[part 14 of 15: package /ComponentTypes]
AUTOSAR XML (schema 4-3-0)
package /ComponentTypes  (continued)
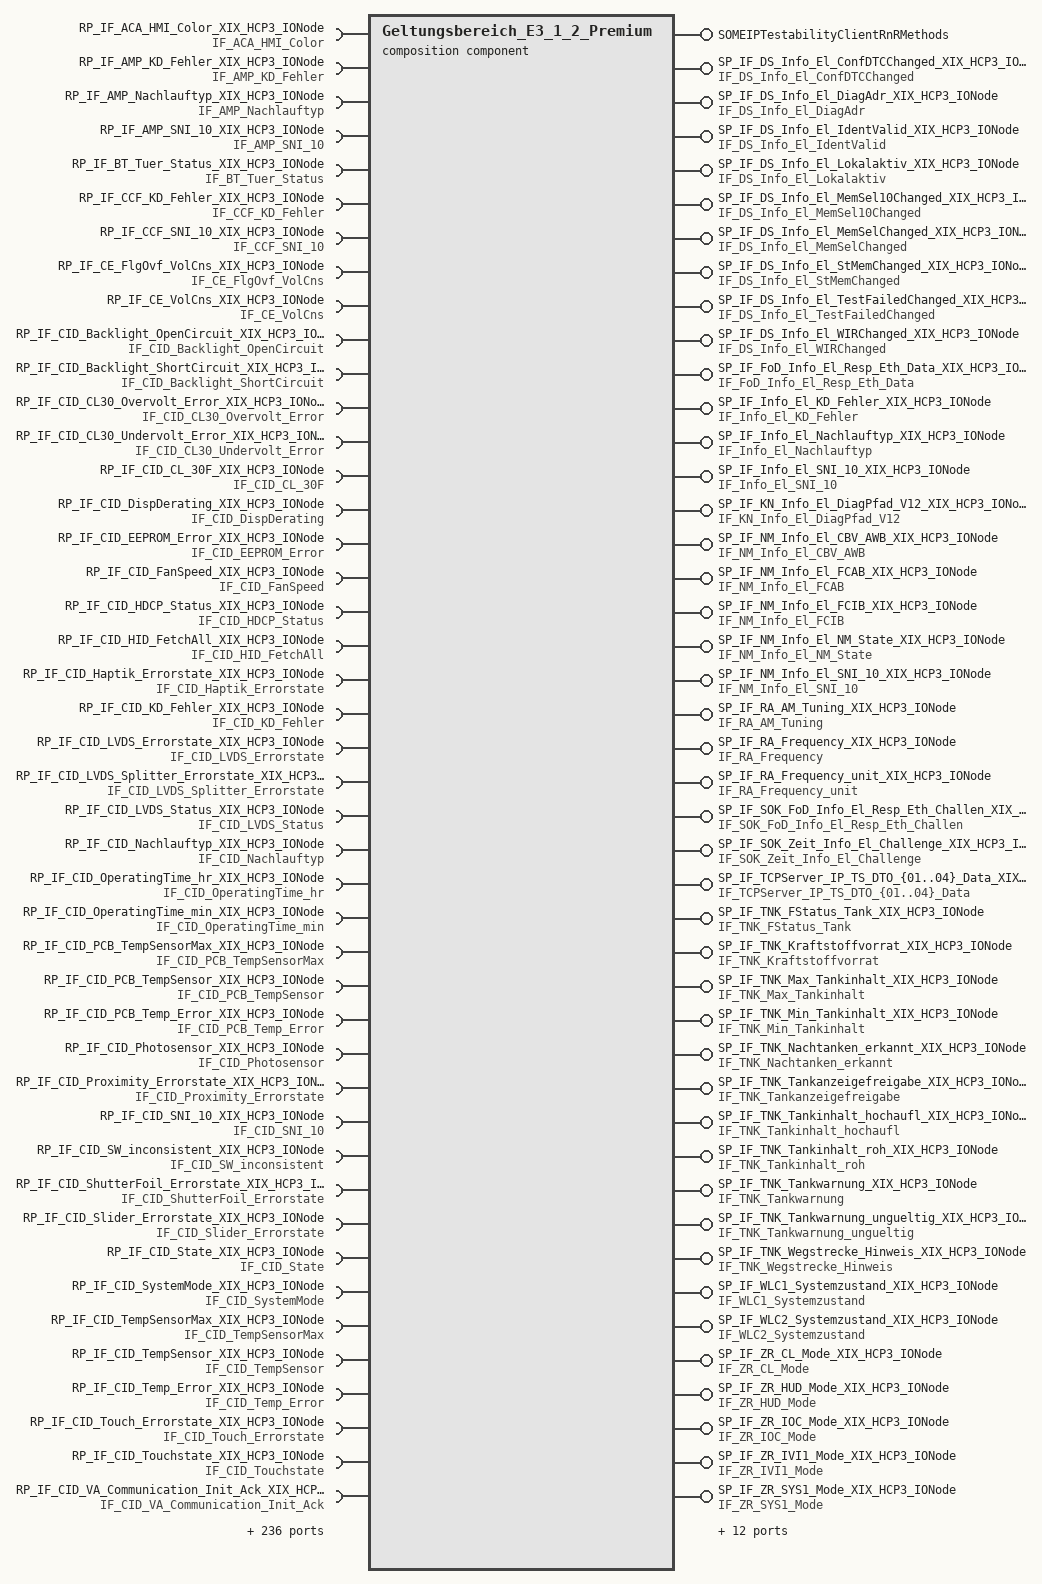
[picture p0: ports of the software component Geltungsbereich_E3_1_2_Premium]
  composition sw component type Geltungsbereich_E3_1_2_Premium
    59 x provide port:
      SOMEIPTestabilityClientRnRMethods: provided-interface=SOMEIPTestabilityClientRnRMethods
      SP_IF_DS_Info_El_ConfDTCChanged_XIX_HCP3_IONode: provided-interface=IF_DS_Info_El_ConfDTCChanged
      SP_IF_DS_Info_El_DiagAdr_XIX_HCP3_IONode: provided-interface=IF_DS_Info_El_DiagAdr
      SP_IF_DS_Info_El_IdentValid_XIX_HCP3_IONode: provided-interface=IF_DS_Info_El_IdentValid
      SP_IF_DS_Info_El_Lokalaktiv_XIX_HCP3_IONode: provided-interface=IF_DS_Info_El_Lokalaktiv
      SP_IF_DS_Info_El_MemSel10Changed_XIX_HCP3_IONode: provided-interface=IF_DS_Info_El_MemSel10Changed
      SP_IF_DS_Info_El_MemSelChanged_XIX_HCP3_IONode: provided-interface=IF_DS_Info_El_MemSelChanged
      SP_IF_DS_Info_El_StMemChanged_XIX_HCP3_IONode: provided-interface=IF_DS_Info_El_StMemChanged
      SP_IF_DS_Info_El_TestFailedChanged_XIX_HCP3_IONode: provided-interface=IF_DS_Info_El_TestFailedChanged
      SP_IF_DS_Info_El_WIRChanged_XIX_HCP3_IONode: provided-interface=IF_DS_Info_El_WIRChanged
      SP_IF_FoD_Info_El_Resp_Eth_Data_XIX_HCP3_IONode: provided-interface=IF_FoD_Info_El_Resp_Eth_Data
      SP_IF_Info_El_KD_Fehler_XIX_HCP3_IONode: provided-interface=IF_Info_El_KD_Fehler
      SP_IF_Info_El_Nachlauftyp_XIX_HCP3_IONode: provided-interface=IF_Info_El_Nachlauftyp
      SP_IF_Info_El_SNI_10_XIX_HCP3_IONode: provided-interface=IF_Info_El_SNI_10
      SP_IF_KN_Info_El_DiagPfad_V12_XIX_HCP3_IONode: provided-interface=IF_KN_Info_El_DiagPfad_V12
      SP_IF_NM_Info_El_CBV_AWB_XIX_HCP3_IONode: provided-interface=IF_NM_Info_El_CBV_AWB
      SP_IF_NM_Info_El_FCAB_XIX_HCP3_IONode: provided-interface=IF_NM_Info_El_FCAB
      SP_IF_NM_Info_El_FCIB_XIX_HCP3_IONode: provided-interface=IF_NM_Info_El_FCIB
      SP_IF_NM_Info_El_NM_State_XIX_HCP3_IONode: provided-interface=IF_NM_Info_El_NM_State
      SP_IF_NM_Info_El_SNI_10_XIX_HCP3_IONode: provided-interface=IF_NM_Info_El_SNI_10
      SP_IF_RA_AM_Tuning_XIX_HCP3_IONode: provided-interface=IF_RA_AM_Tuning
      SP_IF_RA_Frequency_XIX_HCP3_IONode: provided-interface=IF_RA_Frequency
      SP_IF_RA_Frequency_unit_XIX_HCP3_IONode: provided-interface=IF_RA_Frequency_unit
      SP_IF_SOK_FoD_Info_El_Resp_Eth_Challen_XIX_HCP3_IONode: provided-interface=IF_SOK_FoD_Info_El_Resp_Eth_Challen
      SP_IF_SOK_Zeit_Info_El_Challenge_XIX_HCP3_IONode: provided-interface=IF_SOK_Zeit_Info_El_Challenge
      SP_IF_TCPServer_IP_TS_DTO_{01..04}_Data_XIX_HCP3_IONode: provided-interface=IF_TCPServer_IP_TS_DTO_{01..04}_Data
      SP_IF_TNK_FStatus_Tank_XIX_HCP3_IONode: provided-interface=IF_TNK_FStatus_Tank
      SP_IF_TNK_Kraftstoffvorrat_XIX_HCP3_IONode: provided-interface=IF_TNK_Kraftstoffvorrat
      SP_IF_TNK_Max_Tankinhalt_XIX_HCP3_IONode: provided-interface=IF_TNK_Max_Tankinhalt
      SP_IF_TNK_Min_Tankinhalt_XIX_HCP3_IONode: provided-interface=IF_TNK_Min_Tankinhalt
      SP_IF_TNK_Nachtanken_erkannt_XIX_HCP3_IONode: provided-interface=IF_TNK_Nachtanken_erkannt
      SP_IF_TNK_Tankanzeigefreigabe_XIX_HCP3_IONode: provided-interface=IF_TNK_Tankanzeigefreigabe
      SP_IF_TNK_Tankinhalt_hochaufl_XIX_HCP3_IONode: provided-interface=IF_TNK_Tankinhalt_hochaufl
      SP_IF_TNK_Tankinhalt_roh_XIX_HCP3_IONode: provided-interface=IF_TNK_Tankinhalt_roh
      SP_IF_TNK_Tankwarnung_XIX_HCP3_IONode: provided-interface=IF_TNK_Tankwarnung
      SP_IF_TNK_Tankwarnung_ungueltig_XIX_HCP3_IONode: provided-interface=IF_TNK_Tankwarnung_ungueltig
      SP_IF_TNK_Wegstrecke_Hinweis_XIX_HCP3_IONode: provided-interface=IF_TNK_Wegstrecke_Hinweis
      SP_IF_WLC1_Systemzustand_XIX_HCP3_IONode: provided-interface=IF_WLC1_Systemzustand
      SP_IF_WLC2_Systemzustand_XIX_HCP3_IONode: provided-interface=IF_WLC2_Systemzustand
      SP_IF_ZR_CL_Mode_XIX_HCP3_IONode: provided-interface=IF_ZR_CL_Mode
      SP_IF_ZR_HUD_Mode_XIX_HCP3_IONode: provided-interface=IF_ZR_HUD_Mode
      SP_IF_ZR_IOC_Mode_XIX_HCP3_IONode: provided-interface=IF_ZR_IOC_Mode
      SP_IF_ZR_IVI1_Mode_XIX_HCP3_IONode: provided-interface=IF_ZR_IVI1_Mode
      SP_IF_ZR_SYS1_Mode_XIX_HCP3_IONode: provided-interface=IF_ZR_SYS1_Mode
      SP_IF_ZR_State_CID_XIX_HCP3_IONode: provided-interface=IF_ZR_State_CID
      SP_IF_ZR_State_FID_XIX_HCP3_IONode: provided-interface=IF_ZR_State_FID
      SP_IF_ZR_State_PID_XIX_HCP3_IONode: provided-interface=IF_ZR_State_PID
      SP_IF_ZR_VA_Challenge_CID_XIX_HCP3_IONode: provided-interface=IF_ZR_VA_Challenge_CID
      SP_IF_ZR_VA_Challenge_FID_XIX_HCP3_IONode: provided-interface=IF_ZR_VA_Challenge_FID
      SP_IF_ZR_VA_Challenge_PID_XIX_HCP3_IONode: provided-interface=IF_ZR_VA_Challenge_PID
      SP_IF_ZR_VA_Communication_Init_Ack_CID_XIX_HCP3_IONode: provided-interface=IF_ZR_VA_Communication_Init_Ack_CID
      SP_IF_ZR_VA_Communication_Init_Ack_FID_XIX_HCP3_IONode: provided-interface=IF_ZR_VA_Communication_Init_Ack_FID
      SP_IF_ZR_VA_Communication_Init_Ack_PID_XIX_HCP3_IONode: provided-interface=IF_ZR_VA_Communication_Init_Ack_PID
      SP_IF_ZR_VA_Communication_Init_CID_XIX_HCP3_IONode: provided-interface=IF_ZR_VA_Communication_Init_CID
      SP_IF_ZR_VA_Communication_Init_FID_XIX_HCP3_IONode: provided-interface=IF_ZR_VA_Communication_Init_FID
      SP_IF_ZR_VA_Communication_Init_PID_XIX_HCP3_IONode: provided-interface=IF_ZR_VA_Communication_Init_PID
    286 x require port:
      RP_IF_ACA_HMI_Color_XIX_HCP3_IONode: required-interface=IF_ACA_HMI_Color
      RP_IF_AMP_KD_Fehler_XIX_HCP3_IONode: required-interface=IF_AMP_KD_Fehler
      RP_IF_AMP_Nachlauftyp_XIX_HCP3_IONode: required-interface=IF_AMP_Nachlauftyp
      RP_IF_AMP_SNI_10_XIX_HCP3_IONode: required-interface=IF_AMP_SNI_10
      RP_IF_BT_Tuer_Status_XIX_HCP3_IONode: required-interface=IF_BT_Tuer_Status
      RP_IF_CCF_KD_Fehler_XIX_HCP3_IONode: required-interface=IF_CCF_KD_Fehler
      RP_IF_CCF_SNI_10_XIX_HCP3_IONode: required-interface=IF_CCF_SNI_10
      RP_IF_CE_FlgOvf_VolCns_XIX_HCP3_IONode: required-interface=IF_CE_FlgOvf_VolCns
      RP_IF_CE_VolCns_XIX_HCP3_IONode: required-interface=IF_CE_VolCns
      RP_IF_CID_Backlight_OpenCircuit_XIX_HCP3_IONode: required-interface=IF_CID_Backlight_OpenCircuit
      RP_IF_CID_Backlight_ShortCircuit_XIX_HCP3_IONode: required-interface=IF_CID_Backlight_ShortCircuit
      RP_IF_CID_CL30_Overvolt_Error_XIX_HCP3_IONode: required-interface=IF_CID_CL30_Overvolt_Error
      RP_IF_CID_CL30_Undervolt_Error_XIX_HCP3_IONode: required-interface=IF_CID_CL30_Undervolt_Error
      RP_IF_CID_CL_30F_XIX_HCP3_IONode: required-interface=IF_CID_CL_30F
      RP_IF_CID_DispDerating_XIX_HCP3_IONode: required-interface=IF_CID_DispDerating
      RP_IF_CID_EEPROM_Error_XIX_HCP3_IONode: required-interface=IF_CID_EEPROM_Error
      RP_IF_CID_FanSpeed_XIX_HCP3_IONode: required-interface=IF_CID_FanSpeed
      RP_IF_CID_HDCP_Status_XIX_HCP3_IONode: required-interface=IF_CID_HDCP_Status
      RP_IF_CID_HID_FetchAll_XIX_HCP3_IONode: required-interface=IF_CID_HID_FetchAll
      RP_IF_CID_Haptik_Errorstate_XIX_HCP3_IONode: required-interface=IF_CID_Haptik_Errorstate
      RP_IF_CID_KD_Fehler_XIX_HCP3_IONode: required-interface=IF_CID_KD_Fehler
      RP_IF_CID_LVDS_Errorstate_XIX_HCP3_IONode: required-interface=IF_CID_LVDS_Errorstate
      RP_IF_CID_LVDS_Splitter_Errorstate_XIX_HCP3_IONode: required-interface=IF_CID_LVDS_Splitter_Errorstate
      RP_IF_CID_LVDS_Status_XIX_HCP3_IONode: required-interface=IF_CID_LVDS_Status
      RP_IF_CID_Nachlauftyp_XIX_HCP3_IONode: required-interface=IF_CID_Nachlauftyp
      RP_IF_CID_OperatingTime_hr_XIX_HCP3_IONode: required-interface=IF_CID_OperatingTime_hr
      RP_IF_CID_OperatingTime_min_XIX_HCP3_IONode: required-interface=IF_CID_OperatingTime_min
      RP_IF_CID_PCB_TempSensorMax_XIX_HCP3_IONode: required-interface=IF_CID_PCB_TempSensorMax
      RP_IF_CID_PCB_TempSensor_XIX_HCP3_IONode: required-interface=IF_CID_PCB_TempSensor
      RP_IF_CID_PCB_Temp_Error_XIX_HCP3_IONode: required-interface=IF_CID_PCB_Temp_Error
      RP_IF_CID_Photosensor_XIX_HCP3_IONode: required-interface=IF_CID_Photosensor
      RP_IF_CID_Proximity_Errorstate_XIX_HCP3_IONode: required-interface=IF_CID_Proximity_Errorstate
      RP_IF_CID_SNI_10_XIX_HCP3_IONode: required-interface=IF_CID_SNI_10
      RP_IF_CID_SW_inconsistent_XIX_HCP3_IONode: required-interface=IF_CID_SW_inconsistent
      RP_IF_CID_ShutterFoil_Errorstate_XIX_HCP3_IONode: required-interface=IF_CID_ShutterFoil_Errorstate
      RP_IF_CID_Slider_Errorstate_XIX_HCP3_IONode: required-interface=IF_CID_Slider_Errorstate
      RP_IF_CID_State_XIX_HCP3_IONode: required-interface=IF_CID_State
      RP_IF_CID_SystemMode_XIX_HCP3_IONode: required-interface=IF_CID_SystemMode
      RP_IF_CID_TempSensorMax_XIX_HCP3_IONode: required-interface=IF_CID_TempSensorMax
      RP_IF_CID_TempSensor_XIX_HCP3_IONode: required-interface=IF_CID_TempSensor
      RP_IF_CID_Temp_Error_XIX_HCP3_IONode: required-interface=IF_CID_Temp_Error
      RP_IF_CID_Touch_Errorstate_XIX_HCP3_IONode: required-interface=IF_CID_Touch_Errorstate
      RP_IF_CID_Touchstate_XIX_HCP3_IONode: required-interface=IF_CID_Touchstate
      RP_IF_CID_VA_Communication_Init_Ack_XIX_HCP3_IONode: required-interface=IF_CID_VA_Communication_Init_Ack
      RP_IF_CID_VA_Communication_Init_XIX_HCP3_IONode: required-interface=IF_CID_VA_Communication_Init
      RP_IF_CID_VA_Response_XIX_HCP3_IONode: required-interface=IF_CID_VA_Response
      RP_IF_CID_VW_SL_App_SW_Version_Nr_XIX_HCP3_IONode: required-interface=IF_CID_VW_SL_App_SW_Version_Nr
      RP_IF_CID_VW_SL_HW_Version_Nr_XIX_HCP3_IONode: required-interface=IF_CID_VW_SL_HW_Version_Nr
      RP_IF_CID_VW_SL_Spare_Part_Nr_EndNr_XIX_HCP3_IONode: required-interface=IF_CID_VW_SL_Spare_Part_Nr_EndNr
      RP_IF_CID_VW_SL_Spare_Part_Nr_Index_XIX_HCP3_IONode: required-interface=IF_CID_VW_SL_Spare_Part_Nr_Index
      RP_IF_CID_VW_SL_Spare_Part_Nr_MittelNr_XIX_HCP3_IONode: required-interface=IF_CID_VW_SL_Spare_Part_Nr_MittelNr
      RP_IF_CID_VW_SL_Spare_Part_Nr_TMA_XIX_HCP3_IONode: required-interface=IF_CID_VW_SL_Spare_Part_Nr_TMA
      RP_IF_DTSO_StPTEgySrc_XIX_HCP3_IONode: required-interface=IF_DTSO_StPTEgySrc
      RP_IF_DTSO_StPrpUnitAcvWhl_XIX_HCP3_IONode: required-interface=IF_DTSO_StPrpUnitAcvWhl
      RP_IF_DW_Kilometerstand_XIX_HCP3_IONode: required-interface=IF_DW_Kilometerstand
      RP_IF_DispKBI_FS_KD_Fehler_XIX_HCP3_IONode: required-interface=IF_DispKBI_FS_KD_Fehler
      RP_IF_DispKBI_FS_Nachlauftyp_XIX_HCP3_IONode: required-interface=IF_DispKBI_FS_Nachlauftyp
      RP_IF_DispKBI_FS_SNI_10_XIX_HCP3_IONode: required-interface=IF_DispKBI_FS_SNI_10
      RP_IF_FID_Backlight_OpenCircuit_XIX_HCP3_IONode: required-interface=IF_FID_Backlight_OpenCircuit
      RP_IF_FID_Backlight_ShortCircuit_XIX_HCP3_IONode: required-interface=IF_FID_Backlight_ShortCircuit
      RP_IF_FID_CL30_Overvolt_Error_XIX_HCP3_IONode: required-interface=IF_FID_CL30_Overvolt_Error
      RP_IF_FID_CL30_Undervolt_Error_XIX_HCP3_IONode: required-interface=IF_FID_CL30_Undervolt_Error
      RP_IF_FID_CL_30F_XIX_HCP3_IONode: required-interface=IF_FID_CL_30F
      RP_IF_FID_DispDerating_XIX_HCP3_IONode: required-interface=IF_FID_DispDerating
      RP_IF_FID_EEPROM_Error_XIX_HCP3_IONode: required-interface=IF_FID_EEPROM_Error
      RP_IF_FID_LVDS_Errorstate_XIX_HCP3_IONode: required-interface=IF_FID_LVDS_Errorstate
      RP_IF_FID_LVDS_State_XIX_HCP3_IONode: required-interface=IF_FID_LVDS_State
      RP_IF_FID_OperatingTime_hr_XIX_HCP3_IONode: required-interface=IF_FID_OperatingTime_hr
      RP_IF_FID_OperatingTime_min_XIX_HCP3_IONode: required-interface=IF_FID_OperatingTime_min
      RP_IF_FID_PCB_TempSensorMax_XIX_HCP3_IONode: required-interface=IF_FID_PCB_TempSensorMax
      RP_IF_FID_PCB_TempSensor_XIX_HCP3_IONode: required-interface=IF_FID_PCB_TempSensor
      RP_IF_FID_PCB_Temp_Error_XIX_HCP3_IONode: required-interface=IF_FID_PCB_Temp_Error
      RP_IF_FID_Photosensor_XIX_HCP3_IONode: required-interface=IF_FID_Photosensor
      RP_IF_FID_SW_inconsistent_XIX_HCP3_IONode: required-interface=IF_FID_SW_inconsistent
      RP_IF_FID_State_XIX_HCP3_IONode: required-interface=IF_FID_State
      RP_IF_FID_SystemMode_XIX_HCP3_IONode: required-interface=IF_FID_SystemMode
      RP_IF_FID_TempSensorMax_XIX_HCP3_IONode: required-interface=IF_FID_TempSensorMax
      RP_IF_FID_TempSensor_XIX_HCP3_IONode: required-interface=IF_FID_TempSensor
      RP_IF_FID_Temp_Error_XIX_HCP3_IONode: required-interface=IF_FID_Temp_Error
      RP_IF_FID_VA_Communication_Init_Ack_XIX_HCP3_IONode: required-interface=IF_FID_VA_Communication_Init_Ack
      RP_IF_FID_VA_Communication_Init_XIX_HCP3_IONode: required-interface=IF_FID_VA_Communication_Init
      RP_IF_FID_VA_Response_XIX_HCP3_IONode: required-interface=IF_FID_VA_Response
      RP_IF_FT_Tuer_Status_XIX_HCP3_IONode: required-interface=IF_FT_Tuer_Status
      RP_IF_FT_Tuer_geoeffnet_XIX_HCP3_IONode: required-interface=IF_FT_Tuer_geoeffnet
      RP_IF_FoD_Info_El_Req_Eth_Data_XIX_HCP3_IONode: required-interface=IF_FoD_Info_El_Req_Eth_Data
      RP_IF_Gateway_Nachlauftyp_XIX_HCP3_IONode: required-interface=IF_Gateway_Nachlauftyp
      RP_IF_HBFS_Tuer_Status_XIX_HCP3_IONode: required-interface=IF_HBFS_Tuer_Status
      RP_IF_HCP3Sys03_KD_Fehler_XIX_HCP3_IONode: required-interface=IF_HCP3Sys03_KD_Fehler
      RP_IF_HCP3Sys03_SNI_10_XIX_HCP3_IONode: required-interface=IF_HCP3Sys03_SNI_10
      RP_IF_HFS_Tuer_Status_XIX_HCP3_IONode: required-interface=IF_HFS_Tuer_Status
      RP_IF_HUD_KD_Fehler_XIX_HCP3_IONode: required-interface=IF_HUD_KD_Fehler
      RP_IF_HUD_Nachlauftyp_XIX_HCP3_IONode: required-interface=IF_HUD_Nachlauftyp
      RP_IF_HUD_SNI_10_XIX_HCP3_IONode: required-interface=IF_HUD_SNI_10
      RP_IF_SG_HWP_01_XIX_HCP3_IONode: required-interface=IF_SG_HWP_01
      RP_IF_HWP_HMI_State_XIX_HCP3_IONode: required-interface=IF_HWP_HMI_State
      RP_IF_ICAS3Sys01_KD_Fehler_XIX_HCP3_IONode: required-interface=IF_ICAS3Sys01_KD_Fehler
      RP_IF_ICAS3Sys01_SNI_10_XIX_HCP3_IONode: required-interface=IF_ICAS3Sys01_SNI_10
      RP_IF_IP_TS_CTO_01_Data_XIX_HCP3_IONode: required-interface=IF_IP_TS_CTO_01_Data
      RP_IF_IP_TS_DTO_{01..04}_Data_XIX_HCP3_IONode: required-interface=IF_IP_TS_DTO_{01..04}_Data
      RP_IF_KL_Geblaese_Status_XIX_HCP3_IONode: required-interface=IF_KL_Geblaese_Status
      RP_IF_KN_AMP_DiagPfad_V12_XIX_HCP3_IONode: required-interface=IF_KN_AMP_DiagPfad_V12
      RP_IF_KN_CCF_DiagPfad_V12_XIX_HCP3_IONode: required-interface=IF_KN_CCF_DiagPfad_V12
      RP_IF_KN_CID_DiagPfad_V12_XIX_HCP3_IONode: required-interface=IF_KN_CID_DiagPfad_V12
      RP_IF_KN_DispKBI_FS_DiagPfad_V12_XIX_HCP3_IONode: required-interface=IF_KN_DispKBI_FS_DiagPfad_V12
      RP_IF_KN_HCP3Sys03_DiagPfad_V12_XIX_HCP3_IONode: required-interface=IF_KN_HCP3Sys03_DiagPfad_V12
      RP_IF_KN_HUD_DiagPfad_V12_XIX_HCP3_IONode: required-interface=IF_KN_HUD_DiagPfad_V12
      RP_IF_KN_ICAS3Sys01_DiagPfad_V12_XIX_HCP3_IONode: required-interface=IF_KN_ICAS3Sys01_DiagPfad_V12
      RP_IF_KN_PID_DiagPfad_V12_XIX_HCP3_IONode: required-interface=IF_KN_PID_DiagPfad_V12
      RP_IF_KN_WLC1_DiagPfad_V12_XIX_HCP3_IONode: required-interface=IF_KN_WLC1_DiagPfad_V12
      RP_IF_KN_WLC2_DiagPfad_V12_XIX_HCP3_IONode: required-interface=IF_KN_WLC2_DiagPfad_V12
      RP_IF_SG_ClampControl_01_XIX_HCP3_IONode: required-interface=IF_SG_ClampControl_01
      RP_IF_LSR_CL30_Overvolt_Error_XIX_HCP3_IONode: required-interface=IF_LSR_CL30_Overvolt_Error
      RP_IF_LSR_CL30_Undervoltage_Error_XIX_HCP3_IONode: required-interface=IF_LSR_CL30_Undervoltage_Error
      RP_IF_LSR_EEPROM_Error_TF_XIX_HCP3_IONode: required-interface=IF_LSR_EEPROM_Error_TF
      RP_IF_LSR_EEPROM_Error_TNCTOC_XIX_HCP3_IONode: required-interface=IF_LSR_EEPROM_Error_TNCTOC
      RP_IF_LSR_SW_inconsistent_TF_XIX_HCP3_IONode: required-interface=IF_LSR_SW_inconsistent_TF
      RP_IF_LSR_SW_inconsistent_TNCTOC_XIX_HCP3_IONode: required-interface=IF_LSR_SW_inconsistent_TNCTOC
      RP_IF_LSR_SystemMode_XIX_HCP3_IONode: required-interface=IF_LSR_SystemMode
      RP_IF_LSR_VW_SL_App_SW_Version_Nr_XIX_HCP3_IONode: required-interface=IF_LSR_VW_SL_App_SW_Version_Nr
      RP_IF_LSR_VW_SL_HW_Version_Nr_XIX_HCP3_IONode: required-interface=IF_LSR_VW_SL_HW_Version_Nr
      RP_IF_LSR_VW_SL_Spare_Part_Nr_EndNr_XIX_HCP3_IONode: required-interface=IF_LSR_VW_SL_Spare_Part_Nr_EndNr
      RP_IF_LSR_VW_SL_Spare_Part_Nr_Index_XIX_HCP3_IONode: required-interface=IF_LSR_VW_SL_Spare_Part_Nr_Index
      RP_IF_LSR_VW_SL_Spare_Part_Nr_MittelNr_XIX_HCP3_IONode: required-interface=IF_LSR_VW_SL_Spare_Part_Nr_MittelNr
      RP_IF_LSR_VW_SL_Spare_Part_Nr_TMA_XIX_HCP3_IONode: required-interface=IF_LSR_VW_SL_Spare_Part_Nr_TMA
      RP_IF_LSR_dimming_PWM_XIX_HCP3_IONode: required-interface=IF_LSR_dimming_PWM
      RP_IF_LSR_dimming_post_carriage_XIX_HCP3_IONode: required-interface=IF_LSR_dimming_post_carriage
      RP_IF_MFL_Eventcode_1_XIX_HCP3_IONode: required-interface=IF_MFL_Eventcode_1
      RP_IF_MFL_Eventcode_2_XIX_HCP3_IONode: required-interface=IF_MFL_Eventcode_2
      RP_IF_MFL_Marke_XIX_HCP3_IONode: required-interface=IF_MFL_Marke
      RP_IF_MFL_Paddle_Verbau_XIX_HCP3_IONode: required-interface=IF_MFL_Paddle_Verbau
      RP_IF_MFL_Tastencode_1_XIX_HCP3_IONode: required-interface=IF_MFL_Tastencode_1
      RP_IF_MFL_Tastencode_2_XIX_HCP3_IONode: required-interface=IF_MFL_Tastencode_2
      RP_IF_MFL_Variante_XIX_HCP3_IONode: required-interface=IF_MFL_Variante
      RP_IF_MM_PropulsionSystemActive_XIX_HCP3_IONode: required-interface=IF_MM_PropulsionSystemActive
      RP_IF_NM_AMP_FCIB_XIX_HCP3_IONode: required-interface=IF_NM_AMP_FCIB
      RP_IF_NM_CCF_CBV_AWB_XIX_HCP3_IONode: required-interface=IF_NM_CCF_CBV_AWB
      RP_IF_NM_CCF_CBV_CRI_XIX_HCP3_IONode: required-interface=IF_NM_CCF_CBV_CRI
      RP_IF_NM_CCF_FCAB_XIX_HCP3_IONode: required-interface=IF_NM_CCF_FCAB
      RP_IF_NM_CCF_FCIB_XIX_HCP3_IONode: required-interface=IF_NM_CCF_FCIB
      RP_IF_NM_CCF_NM_State_XIX_HCP3_IONode: required-interface=IF_NM_CCF_NM_State
      RP_IF_NM_CCF_SNI_10_XIX_HCP3_IONode: required-interface=IF_NM_CCF_SNI_10
      RP_IF_NM_CID_CBV_AWB_XIX_HCP3_IONode: required-interface=IF_NM_CID_CBV_AWB
      RP_IF_NM_CID_FCAB_XIX_HCP3_IONode: required-interface=IF_NM_CID_FCAB
      RP_IF_NM_CID_FCIB_XIX_HCP3_IONode: required-interface=IF_NM_CID_FCIB
      RP_IF_NM_CID_NM_State_XIX_HCP3_IONode: required-interface=IF_NM_CID_NM_State
      RP_IF_NM_CID_SNI_10_XIX_HCP3_IONode: required-interface=IF_NM_CID_SNI_10
      RP_IF_NM_DispKBI_FS_CBV_AWB_XIX_HCP3_IONode: required-interface=IF_NM_DispKBI_FS_CBV_AWB
      RP_IF_NM_DispKBI_FS_FCAB_XIX_HCP3_IONode: required-interface=IF_NM_DispKBI_FS_FCAB
      RP_IF_NM_DispKBI_FS_FCIB_XIX_HCP3_IONode: required-interface=IF_NM_DispKBI_FS_FCIB
      RP_IF_NM_DispKBI_FS_NM_State_XIX_HCP3_IONode: required-interface=IF_NM_DispKBI_FS_NM_State
      RP_IF_NM_DispKBI_FS_SNI_10_XIX_HCP3_IONode: required-interface=IF_NM_DispKBI_FS_SNI_10
      RP_IF_NM_Gateway_CBV_AWB_XIX_HCP3_IONode: required-interface=IF_NM_Gateway_CBV_AWB
      RP_IF_NM_Gateway_FCAB_XIX_HCP3_IONode: required-interface=IF_NM_Gateway_FCAB
      RP_IF_NM_Gateway_FCIB_XIX_HCP3_IONode: required-interface=IF_NM_Gateway_FCIB
      RP_IF_NM_Gateway_NM_State_XIX_HCP3_IONode: required-interface=IF_NM_Gateway_NM_State
      RP_IF_NM_Gateway_SNI_10_XIX_HCP3_IONode: required-interface=IF_NM_Gateway_SNI_10
      RP_IF_NM_HUD_CBV_AWB_XIX_HCP3_IONode: required-interface=IF_NM_HUD_CBV_AWB
      RP_IF_NM_HUD_FCAB_XIX_HCP3_IONode: required-interface=IF_NM_HUD_FCAB
      RP_IF_NM_HUD_FCIB_XIX_HCP3_IONode: required-interface=IF_NM_HUD_FCIB
      RP_IF_NM_HUD_NM_State_XIX_HCP3_IONode: required-interface=IF_NM_HUD_NM_State
      RP_IF_NM_HUD_SNI_10_XIX_HCP3_IONode: required-interface=IF_NM_HUD_SNI_10
      RP_IF_NM_LSR_1_CBV_AWB_XIX_HCP3_IONode: required-interface=IF_NM_LSR_1_CBV_AWB
      RP_IF_NM_LSR_1_FCAB_XIX_HCP3_IONode: required-interface=IF_NM_LSR_1_FCAB
      RP_IF_NM_LSR_1_NM_State_XIX_HCP3_IONode: required-interface=IF_NM_LSR_1_NM_State
      RP_IF_NM_LSR_1_SNI_10_XIX_HCP3_IONode: required-interface=IF_NM_LSR_1_SNI_10
      RP_IF_NM_PID_CBV_AWB_XIX_HCP3_IONode: required-interface=IF_NM_PID_CBV_AWB
      RP_IF_NM_PID_FCAB_XIX_HCP3_IONode: required-interface=IF_NM_PID_FCAB
      RP_IF_NM_PID_FCIB_XIX_HCP3_IONode: required-interface=IF_NM_PID_FCIB
      RP_IF_NM_PID_NM_State_XIX_HCP3_IONode: required-interface=IF_NM_PID_NM_State
      RP_IF_NM_PID_SNI_10_XIX_HCP3_IONode: required-interface=IF_NM_PID_SNI_10
      RP_IF_NM_WLC1_CBV_AWB_XIX_HCP3_IONode: required-interface=IF_NM_WLC1_CBV_AWB
      RP_IF_NM_WLC1_FCAB_XIX_HCP3_IONode: required-interface=IF_NM_WLC1_FCAB
      RP_IF_NM_WLC1_FCIB_XIX_HCP3_IONode: required-interface=IF_NM_WLC1_FCIB
      RP_IF_NM_WLC1_NM_State_XIX_HCP3_IONode: required-interface=IF_NM_WLC1_NM_State
      RP_IF_NM_WLC1_SNI_10_XIX_HCP3_IONode: required-interface=IF_NM_WLC1_SNI_10
      RP_IF_NM_WLC2_CBV_AWB_XIX_HCP3_IONode: required-interface=IF_NM_WLC2_CBV_AWB
      RP_IF_NM_WLC2_FCAB_XIX_HCP3_IONode: required-interface=IF_NM_WLC2_FCAB
      RP_IF_NM_WLC2_FCIB_XIX_HCP3_IONode: required-interface=IF_NM_WLC2_FCIB
      RP_IF_NM_WLC2_NM_State_XIX_HCP3_IONode: required-interface=IF_NM_WLC2_NM_State
      RP_IF_NM_WLC2_SNI_10_XIX_HCP3_IONode: required-interface=IF_NM_WLC2_SNI_10
      RP_IF_NVEM_Abschaltstufe_XIX_HCP3_IONode: required-interface=IF_NVEM_Abschaltstufe
      RP_IF_OBD_Driving_Cycle_XIX_HCP3_IONode: required-interface=IF_OBD_Driving_Cycle
      RP_IF_OBD_Warm_Up_Cycle_XIX_HCP3_IONode: required-interface=IF_OBD_Warm_Up_Cycle
      RP_IF_SG_ORU_Control_A_01_XIX_HCP3_IONode: required-interface=IF_SG_ORU_Control_A_01
      RP_IF_SG_ORU_Control_D_01_XIX_HCP3_IONode: required-interface=IF_SG_ORU_Control_D_01
      RP_IF_ORU_Status_XIX_HCP3_IONode: required-interface=IF_ORU_Status
      RP_IF_SG_OTAMC_D_01_XIX_HCP3_IONode: required-interface=IF_SG_OTAMC_D_01
      RP_IF_PID_Backlight_OpenCircuit_XIX_HCP3_IONode: required-interface=IF_PID_Backlight_OpenCircuit
      RP_IF_PID_Backlight_ShortCircuit_XIX_HCP3_IONode: required-interface=IF_PID_Backlight_ShortCircuit
      RP_IF_PID_CL30_Overvoltage_Error_XIX_HCP3_IONode: required-interface=IF_PID_CL30_Overvoltage_Error
      RP_IF_PID_CL30_Undervoltage_Error_XIX_HCP3_IONode: required-interface=IF_PID_CL30_Undervoltage_Error
      RP_IF_PID_CL_30F_XIX_HCP3_IONode: required-interface=IF_PID_CL_30F
      RP_IF_PID_DispDerating_XIX_HCP3_IONode: required-interface=IF_PID_DispDerating
      RP_IF_PID_EEPROM_Error_XIX_HCP3_IONode: required-interface=IF_PID_EEPROM_Error
      RP_IF_PID_FanSpeed_XIX_HCP3_IONode: required-interface=IF_PID_FanSpeed
      RP_IF_PID_HDCP_Status_XIX_HCP3_IONode: required-interface=IF_PID_HDCP_Status
      RP_IF_PID_Haptik_Errorstate_XIX_HCP3_IONode: required-interface=IF_PID_Haptik_Errorstate
      RP_IF_PID_KD_Fehler_XIX_HCP3_IONode: required-interface=IF_PID_KD_Fehler
      RP_IF_PID_LVDS_Errorstate_XIX_HCP3_IONode: required-interface=IF_PID_LVDS_Errorstate
      RP_IF_PID_LVDS_Splitter_Errorstate_XIX_HCP3_IONode: required-interface=IF_PID_LVDS_Splitter_Errorstate
      RP_IF_PID_LVDS_State_XIX_HCP3_IONode: required-interface=IF_PID_LVDS_State
      RP_IF_PID_Nachlauftyp_XIX_HCP3_IONode: required-interface=IF_PID_Nachlauftyp
      RP_IF_PID_OperatingTime_hr_XIX_HCP3_IONode: required-interface=IF_PID_OperatingTime_hr
      RP_IF_PID_OperatingTime_min_XIX_HCP3_IONode: required-interface=IF_PID_OperatingTime_min
      RP_IF_PID_PCB_TempSensorMax_XIX_HCP3_IONode: required-interface=IF_PID_PCB_TempSensorMax
      RP_IF_PID_PCB_TempSensor_XIX_HCP3_IONode: required-interface=IF_PID_PCB_TempSensor
      RP_IF_PID_PCB_Temp_Error_XIX_HCP3_IONode: required-interface=IF_PID_PCB_Temp_Error
      RP_IF_PID_Photosensor_XIX_HCP3_IONode: required-interface=IF_PID_Photosensor
      RP_IF_PID_Proximity_Errorstate_XIX_HCP3_IONode: required-interface=IF_PID_Proximity_Errorstate
      RP_IF_PID_SNI_10_XIX_HCP3_IONode: required-interface=IF_PID_SNI_10
      RP_IF_PID_SW_inconsistent_XIX_HCP3_IONode: required-interface=IF_PID_SW_inconsistent
      RP_IF_PID_ShutterFoil_Errorstate_XIX_HCP3_IONode: required-interface=IF_PID_ShutterFoil_Errorstate
      RP_IF_PID_Slider_Errorstate_XIX_HCP3_IONode: required-interface=IF_PID_Slider_Errorstate
      RP_IF_PID_State_XIX_HCP3_IONode: required-interface=IF_PID_State
      RP_IF_PID_SystemMode_XIX_HCP3_IONode: required-interface=IF_PID_SystemMode
      RP_IF_PID_TempSensorMax_XIX_HCP3_IONode: required-interface=IF_PID_TempSensorMax
      RP_IF_PID_TempSensor_XIX_HCP3_IONode: required-interface=IF_PID_TempSensor
      RP_IF_PID_Temp_Error_XIX_HCP3_IONode: required-interface=IF_PID_Temp_Error
      RP_IF_PID_Touch_Errorstate_XIX_HCP3_IONode: required-interface=IF_PID_Touch_Errorstate
      RP_IF_PID_Touchstate_XIX_HCP3_IONode: required-interface=IF_PID_Touchstate
      RP_IF_PID_VA_Communication_Init_Ack_XIX_HCP3_IONode: required-interface=IF_PID_VA_Communication_Init_Ack
      RP_IF_PID_VA_Communication_Init_XIX_HCP3_IONode: required-interface=IF_PID_VA_Communication_Init
      RP_IF_PID_VA_Response_XIX_HCP3_IONode: required-interface=IF_PID_VA_Response
      RP_IF_PID_VW_SL_App_SW_Version_Nr_XIX_HCP3_IONode: required-interface=IF_PID_VW_SL_App_SW_Version_Nr
      RP_IF_PID_VW_SL_HW_Version_Nr_XIX_HCP3_IONode: required-interface=IF_PID_VW_SL_HW_Version_Nr
      RP_IF_PID_VW_SL_Spare_Part_Nr_EndNr_XIX_HCP3_IONode: required-interface=IF_PID_VW_SL_Spare_Part_Nr_EndNr
      RP_IF_PID_VW_SL_Spare_Part_Nr_Index_XIX_HCP3_IONode: required-interface=IF_PID_VW_SL_Spare_Part_Nr_Index
      RP_IF_PID_VW_SL_Spare_Part_Nr_MittelNr_XIX_HCP3_IONode: required-interface=IF_PID_VW_SL_Spare_Part_Nr_MittelNr
      RP_IF_PID_VW_SL_Spare_Part_Nr_TMA_XIX_HCP3_IONode: required-interface=IF_PID_VW_SL_Spare_Part_Nr_TMA
      RP_IF_PTAcvSrv_StDrvMd_XIX_HCP3_IONode: required-interface=IF_PTAcvSrv_StDrvMd
      RP_IF_PTAcvSrv_StPwrMd_XIX_HCP3_IONode: required-interface=IF_PTAcvSrv_StPwrMd
      RP_IF_SI_NWDF_30_XIX_HCP3_IONode: required-interface=IF_SI_NWDF_30
      RP_IF_SI_NWDF_XIX_HCP3_IONode: required-interface=IF_SI_NWDF
      RP_IF_SI_NWDF_gueltig_XIX_HCP3_IONode: required-interface=IF_SI_NWDF_gueltig
      RP_IF_SI_P_Mode_XIX_HCP3_IONode: required-interface=IF_SI_P_Mode
      RP_IF_SI_P_Mode_gueltig_XIX_HCP3_IONode: required-interface=IF_SI_P_Mode_gueltig
      RP_IF_SI_QRS_Mode_XIX_HCP3_IONode: required-interface=IF_SI_QRS_Mode
      RP_IF_SI_T_Mode_XIX_HCP3_IONode: required-interface=IF_SI_T_Mode
      RP_IF_SI_T_Schutz_XIX_HCP3_IONode: required-interface=IF_SI_T_Schutz
      RP_IF_SOK_FoD_Info_El_Req_Eth_Challeng_XIX_HCP3_IONode: required-interface=IF_SOK_FoD_Info_El_Req_Eth_Challeng
      RP_IF_SOK_Zeit_Info_El_Zeit_XIX_HCP3_IONode: required-interface=IF_SOK_Zeit_Info_El_Zeit
      RP_IF_SOK_ungeschuetzte_Zeit_XIX_HCP3_IONode: required-interface=IF_SOK_ungeschuetzte_Zeit
      RP_IF_STH_KVS_Ueberlauf_XIX_HCP3_IONode: required-interface=IF_STH_KVS_Ueberlauf
      RP_IF_STH_KVS_XIX_HCP3_IONode: required-interface=IF_STH_KVS
      RP_IF_TG_Geber_1_Mittelwert_XIX_HCP3_IONode: required-interface=IF_TG_Geber_1_Mittelwert
      RP_IF_TG_Geber_1_Stand_XIX_HCP3_IONode: required-interface=IF_TG_Geber_1_Stand
      RP_IF_TG_Geber_2_Mittelwert_XIX_HCP3_IONode: required-interface=IF_TG_Geber_2_Mittelwert
      RP_IF_TG_Geber_2_Stand_XIX_HCP3_IONode: required-interface=IF_TG_Geber_2_Stand
      RP_IF_TG_Geber_3_Mittelwert_XIX_HCP3_IONode: required-interface=IF_TG_Geber_3_Mittelwert
      RP_IF_TG_Geber_3_Stand_XIX_HCP3_IONode: required-interface=IF_TG_Geber_3_Stand
      RP_IF_TG_Geber_4_Mittelwert_XIX_HCP3_IONode: required-interface=IF_TG_Geber_4_Mittelwert
      RP_IF_TG_Geber_4_Stand_XIX_HCP3_IONode: required-interface=IF_TG_Geber_4_Stand
      RP_IF_TG_QBit_Geber_{1..4}_XIX_HCP3_IONode: required-interface=IF_TG_QBit_Geber_{1..4}
      RP_IF_UH_Jahr_XIX_HCP3_IONode: required-interface=IF_UH_Jahr
      RP_IF_UH_Minute_XIX_HCP3_IONode: required-interface=IF_UH_Minute
      RP_IF_UH_Monat_XIX_HCP3_IONode: required-interface=IF_UH_Monat
      RP_IF_UH_Sekunde_XIX_HCP3_IONode: required-interface=IF_UH_Sekunde
      RP_IF_UH_Stunde_XIX_HCP3_IONode: required-interface=IF_UH_Stunde
      RP_IF_UH_Tag_XIX_HCP3_IONode: required-interface=IF_UH_Tag
      RP_IF_VDSO_DKmtg_Auth_XIX_HCP3_IONode: required-interface=IF_VDSO_DKmtg_Auth
      RP_IF_VDSO_DKmtg_XIX_HCP3_IONode: required-interface=IF_VDSO_DKmtg
      RP_IF_SG_VDSO_05_XIX_HCP3_IONode: required-interface=IF_SG_VDSO_05
      RP_IF_SG_WFS_02_XIX_HCP3_IONode: required-interface=IF_SG_WFS_02
      RP_IF_WLC1_ChargingEfficiency_XIX_HCP3_IONode: required-interface=IF_WLC1_ChargingEfficiency
      RP_IF_WLC1_ChargingStatus_XIX_HCP3_IONode: required-interface=IF_WLC1_ChargingStatus
      RP_IF_WLC1_KD_Fehler_XIX_HCP3_IONode: required-interface=IF_WLC1_KD_Fehler
      RP_IF_WLC1_Nachlauftyp_XIX_HCP3_IONode: required-interface=IF_WLC1_Nachlauftyp
      RP_IF_WLC1_SNI_10_XIX_HCP3_IONode: required-interface=IF_WLC1_SNI_10
      RP_IF_WLC1_UsedChargingStandard_XIX_HCP3_IONode: required-interface=IF_WLC1_UsedChargingStandard
      RP_IF_WLC2_ChargingEfficiency_XIX_HCP3_IONode: required-interface=IF_WLC2_ChargingEfficiency
      RP_IF_WLC2_ChargingStatus_XIX_HCP3_IONode: required-interface=IF_WLC2_ChargingStatus
      RP_IF_WLC2_KD_Fehler_XIX_HCP3_IONode: required-interface=IF_WLC2_KD_Fehler
      RP_IF_WLC2_Nachlauftyp_XIX_HCP3_IONode: required-interface=IF_WLC2_Nachlauftyp
      RP_IF_WLC2_SNI_10_XIX_HCP3_IONode: required-interface=IF_WLC2_SNI_10
      RP_IF_WLC2_UsedChargingStandard_XIX_HCP3_IONode: required-interface=IF_WLC2_UsedChargingStandard
      RP_IF_ZV_Heck_offen_XIX_HCP3_IONode: required-interface=IF_ZV_Heck_offen
      RP_IF_ZV_Tasten_HMI_Anf_XIX_HCP3_IONode: required-interface=IF_ZV_Tasten_HMI_Anf
      RP_IF_ZV_verriegelt_extern_ist_02_XIX_HCP3_IONode: required-interface=IF_ZV_verriegelt_extern_ist_02
      SOMEIPTestabilityClientEvents: required-interface=SOMEIPTestabilityClientEvents
      SOMEIPTestabilityClientMethods: required-interface=SOMEIPTestabilityClientMethods
    14 x component:
      FoDSlave_HCP3_XIX_FoD_XIX_HCP3_IONode: type=FoDSlave_HCP3_XIX_FoD_XIX_HCP3_IONode
      IDS_Sensors_HCP3_IONode_XIX_IDS_ANH_XIX_HCP3_IONode: type=IDS_Sensors_HCP3_IONode_XIX_IDS_ANH_XIX_HCP3_IONode
      Infrastructure_Info_El_XIX_network_infrastructure_XIX_HCP3_IONode: type=Infrastructure_Info_El_XIX_network_infrastructure_XIX_HCP3_IONode
      ORU_Infrastructure_Info_El_XIX_ORU6_XIX_HCP3_IONode: type=ORU_Infrastructure_Info_El_XIX_ORU6_XIX_HCP3_IONode
      OTA_Infrastructure_HCP3_XIX_OTAMC_XIX_HCP3_IONode: type=OTA_Infrastructure_HCP3_XIX_OTAMC_XIX_HCP3_IONode
      OTA_Infrastructure_Info_El_XIX_RP_XIX_HCP3_IONode: type=OTA_Infrastructure_Info_El_XIX_RP_XIX_HCP3_IONode
      PowerManagement_HCP3_IONode_XIX_CockpitInfotainment_Systemfunktionen_XIX_HCP3_IONode: type=PowerManagement_HCP3_IONode_XIX_CockpitInfotainment_Systemfunktionen_XIX_HCP3_IONode
      SOK_Participant_HCP3_IONode_XIX_SOK_XIX_HCP3_IONode: type=SOK_Participant_HCP3_IONode_XIX_SOK_XIX_HCP3_IONode
      TankAlgorithm_XIX_Tank_XIX_HCP3_IONode: type=TankAlgorithm_XIX_Tank_XIX_HCP3_IONode
      Tracing_HCP3_IONode_XIX_CockpitInfotainment_Systemfunktionen_XIX_HCP3_IONode: type=Tracing_HCP3_IONode_XIX_CockpitInfotainment_Systemfunktionen_XIX_HCP3_IONode
      VNSM3_1_XIX_WUSL_XIX_HCP3_IONode: type=VNSM3_1_XIX_WUSL_XIX_HCP3_IONode
      VehicleComm_HCP3_IONode_XIX_CockpitInfotainment_Systemfunktionen_XIX_HCP3_IONode: type=VehicleComm_HCP3_IONode_XIX_CockpitInfotainment_Systemfunktionen_XIX_HCP3_IONode
      WUM_Client3_XIX_WUM_XIX_HCP3_IONode: type=WUM_Client3_XIX_WUM_XIX_HCP3_IONode
      diagnosis_infrastructure_Info_El_XIX_diagnosis_infrastructure_XIX_HCP3_IONode: type=diagnosis_infrastructure_Info_El_XIX_diagnosis_infrastructure_XIX_HCP3_IONode
    delegate VehicleComm_HCP3_IONode_XIX_CockpitInfotainment_Systemfunktionen_XIX_HCP3_IONode.RP_IF_ACA_HMI_Color_XIX_VehicleComm_HCP3_IONode_XIX_CockpitInfotainment_Systemfunktionen_XIX_HCP3_IONode <-> outer port RP_IF_ACA_HMI_Color_XIX_HCP3_IONode  # _XIX_AdaptiveCruiseAssistACA_XIX_ACA_4_XIX_HCP21_SMH_PERF_XIX_VehicleComm_HCP3_IONode_XIX_CockpitInfotainment_Systemfunktionen_XIX_HCP3_IONode_XIX_ACA_HMI_Color
    delegate PowerManagement_HCP3_IONode_XIX_CockpitInfotainment_Systemfunktionen_XIX_HCP3_IONode.RP_IF_CID_LVDS_Status_XIX_PowerManagement_HCP3_IONode_XIX_CockpitInfotainment_Systemfunktionen_XIX_HCP3_IONode <-> outer port RP_IF_CID_LVDS_Status_XIX_HCP3_IONode  # _XIX_CI_Common_XIX_UserInterface_XIX_CI_Disp_XIX_PowerManagement_HCP3_IONode_XIX_CockpitInfotainment_Systemfunktionen_XIX_HCP3_IONode_XIX_CID_LVDS_Status
    delegate PowerManagement_HCP3_IONode_XIX_CockpitInfotainment_Systemfunktionen_XIX_HCP3_IONode.RP_IF_CID_State_XIX_PowerManagement_HCP3_IONode_XIX_CockpitInfotainment_Systemfunktionen_XIX_HCP3_IONode <-> outer port RP_IF_CID_State_XIX_HCP3_IONode  # _XIX_CI_Common_XIX_UserInterface_XIX_CI_Disp_XIX_PowerManagement_HCP3_IONode_XIX_CockpitInfotainment_Systemfunktionen_XIX_HCP3_IONode_XIX_CID_State
    delegate Tracing_HCP3_IONode_XIX_CockpitInfotainment_Systemfunktionen_XIX_HCP3_IONode.RP_IF_CID_Proximity_Errorstate_XIX_Tracing_HCP3_IONode_XIX_CockpitInfotainment_Systemfunktionen_XIX_HCP3_IONode <-> outer port RP_IF_CID_Proximity_Errorstate_XIX_HCP3_IONode  # _XIX_CI_Common_XIX_UserInterface_XIX_CI_Disp_XIX_Tracing_HCP3_IONode_XIX_CockpitInfotainment_Systemfunktionen_XIX_HCP3_IONode_XIX_CID_Proximity_Errorstate
    delegate Tracing_HCP3_IONode_XIX_CockpitInfotainment_Systemfunktionen_XIX_HCP3_IONode.RP_IF_CID_Temp_Error_XIX_Tracing_HCP3_IONode_XIX_CockpitInfotainment_Systemfunktionen_XIX_HCP3_IONode <-> outer port RP_IF_CID_Temp_Error_XIX_HCP3_IONode  # _XIX_CI_Common_XIX_UserInterface_XIX_CI_Disp_XIX_Tracing_HCP3_IONode_XIX_CockpitInfotainment_Systemfunktionen_XIX_HCP3_IONode_XIX_CID_Temp_Error
    delegate Tracing_HCP3_IONode_XIX_CockpitInfotainment_Systemfunktionen_XIX_HCP3_IONode.RP_IF_CID_Slider_Errorstate_XIX_Tracing_HCP3_IONode_XIX_CockpitInfotainment_Systemfunktionen_XIX_HCP3_IONode <-> outer port RP_IF_CID_Slider_Errorstate_XIX_HCP3_IONode  # _XIX_CI_Common_XIX_UserInterface_XIX_CI_Disp_XIX_Tracing_HCP3_IONode_XIX_CockpitInfotainment_Systemfunktionen_XIX_HCP3_IONode_XIX_CID_Slider_Errorstate
    delegate Tracing_HCP3_IONode_XIX_CockpitInfotainment_Systemfunktionen_XIX_HCP3_IONode.RP_IF_CID_OperatingTime_hr_XIX_Tracing_HCP3_IONode_XIX_CockpitInfotainment_Systemfunktionen_XIX_HCP3_IONode <-> outer port RP_IF_CID_OperatingTime_hr_XIX_HCP3_IONode  # _XIX_CI_Common_XIX_UserInterface_XIX_CI_Disp_XIX_Tracing_HCP3_IONode_XIX_CockpitInfotainment_Systemfunktionen_XIX_HCP3_IONode_XIX_CID_OperatingTime_hr
    delegate Tracing_HCP3_IONode_XIX_CockpitInfotainment_Systemfunktionen_XIX_HCP3_IONode.RP_IF_CID_Photosensor_XIX_Tracing_HCP3_IONode_XIX_CockpitInfotainment_Systemfunktionen_XIX_HCP3_IONode <-> outer port RP_IF_CID_Photosensor_XIX_HCP3_IONode  # _XIX_CI_Common_XIX_UserInterface_XIX_CI_Disp_XIX_Tracing_HCP3_IONode_XIX_CockpitInfotainment_Systemfunktionen_XIX_HCP3_IONode_XIX_CID_Photosensor
    delegate Tracing_HCP3_IONode_XIX_CockpitInfotainment_Systemfunktionen_XIX_HCP3_IONode.RP_IF_CID_Touchstate_XIX_Tracing_HCP3_IONode_XIX_CockpitInfotainment_Systemfunktionen_XIX_HCP3_IONode <-> outer port RP_IF_CID_Touchstate_XIX_HCP3_IONode  # _XIX_CI_Common_XIX_UserInterface_XIX_CI_Disp_XIX_Tracing_HCP3_IONode_XIX_CockpitInfotainment_Systemfunktionen_XIX_HCP3_IONode_XIX_CID_Touchstate
    delegate Tracing_HCP3_IONode_XIX_CockpitInfotainment_Systemfunktionen_XIX_HCP3_IONode.RP_IF_CID_Haptik_Errorstate_XIX_Tracing_HCP3_IONode_XIX_CockpitInfotainment_Systemfunktionen_XIX_HCP3_IONode <-> outer port RP_IF_CID_Haptik_Errorstate_XIX_HCP3_IONode  # _XIX_CI_Common_XIX_UserInterface_XIX_CI_Disp_XIX_Tracing_HCP3_IONode_XIX_CockpitInfotainment_Systemfunktionen_XIX_HCP3_IONode_XIX_CID_Haptik_Errorstate
    delegate Tracing_HCP3_IONode_XIX_CockpitInfotainment_Systemfunktionen_XIX_HCP3_IONode.RP_IF_CID_OperatingTime_min_XIX_Tracing_HCP3_IONode_XIX_CockpitInfotainment_Systemfunktionen_XIX_HCP3_IONode <-> outer port RP_IF_CID_OperatingTime_min_XIX_HCP3_IONode  # _XIX_CI_Common_XIX_UserInterface_XIX_CI_Disp_XIX_Tracing_HCP3_IONode_XIX_CockpitInfotainment_Systemfunktionen_XIX_HCP3_IONode_XIX_CID_OperatingTime_min
    delegate Tracing_HCP3_IONode_XIX_CockpitInfotainment_Systemfunktionen_XIX_HCP3_IONode.RP_IF_CID_SW_inconsistent_XIX_Tracing_HCP3_IONode_XIX_CockpitInfotainment_Systemfunktionen_XIX_HCP3_IONode <-> outer port RP_IF_CID_SW_inconsistent_XIX_HCP3_IONode  # _XIX_CI_Common_XIX_UserInterface_XIX_CI_Disp_XIX_Tracing_HCP3_IONode_XIX_CockpitInfotainment_Systemfunktionen_XIX_HCP3_IONode_XIX_CID_SW_inconsistent
    delegate Tracing_HCP3_IONode_XIX_CockpitInfotainment_Systemfunktionen_XIX_HCP3_IONode.RP_IF_CID_LVDS_Splitter_Errorstate_XIX_Tracing_HCP3_IONode_XIX_CockpitInfotainment_Systemfunktionen_XIX_HCP3_IONode <-> outer port RP_IF_CID_LVDS_Splitter_Errorstate_XIX_HCP3_IONode  # _XIX_CI_Common_XIX_UserInterface_XIX_CI_Disp_XIX_Tracing_HCP3_IONode_XIX_CockpitInfotainment_Systemfunktionen_XIX_HCP3_IONode_XIX_CID_LVDS_Splitter_Errorstate
    delegate Tracing_HCP3_IONode_XIX_CockpitInfotainment_Systemfunktionen_XIX_HCP3_IONode.RP_IF_CID_PCB_Temp_Error_XIX_Tracing_HCP3_IONode_XIX_CockpitInfotainment_Systemfunktionen_XIX_HCP3_IONode <-> outer port RP_IF_CID_PCB_Temp_Error_XIX_HCP3_IONode  # _XIX_CI_Common_XIX_UserInterface_XIX_CI_Disp_XIX_Tracing_HCP3_IONode_XIX_CockpitInfotainment_Systemfunktionen_XIX_HCP3_IONode_XIX_CID_PCB_Temp_Error
    delegate Tracing_HCP3_IONode_XIX_CockpitInfotainment_Systemfunktionen_XIX_HCP3_IONode.RP_IF_CID_PCB_TempSensorMax_XIX_Tracing_HCP3_IONode_XIX_CockpitInfotainment_Systemfunktionen_XIX_HCP3_IONode <-> outer port RP_IF_CID_PCB_TempSensorMax_XIX_HCP3_IONode  # _XIX_CI_Common_XIX_UserInterface_XIX_CI_Disp_XIX_Tracing_HCP3_IONode_XIX_CockpitInfotainment_Systemfunktionen_XIX_HCP3_IONode_XIX_CID_PCB_TempSensorMax
    delegate Tracing_HCP3_IONode_XIX_CockpitInfotainment_Systemfunktionen_XIX_HCP3_IONode.RP_IF_CID_DispDerating_XIX_Tracing_HCP3_IONode_XIX_CockpitInfotainment_Systemfunktionen_XIX_HCP3_IONode <-> outer port RP_IF_CID_DispDerating_XIX_HCP3_IONode  # _XIX_CI_Common_XIX_UserInterface_XIX_CI_Disp_XIX_Tracing_HCP3_IONode_XIX_CockpitInfotainment_Systemfunktionen_XIX_HCP3_IONode_XIX_CID_DispDerating
    delegate Tracing_HCP3_IONode_XIX_CockpitInfotainment_Systemfunktionen_XIX_HCP3_IONode.RP_IF_CID_HID_FetchAll_XIX_Tracing_HCP3_IONode_XIX_CockpitInfotainment_Systemfunktionen_XIX_HCP3_IONode <-> outer port RP_IF_CID_HID_FetchAll_XIX_HCP3_IONode  # _XIX_CI_Common_XIX_UserInterface_XIX_CI_Disp_XIX_Tracing_HCP3_IONode_XIX_CockpitInfotainment_Systemfunktionen_XIX_HCP3_IONode_XIX_CID_HID_FetchAll
    delegate Tracing_HCP3_IONode_XIX_CockpitInfotainment_Systemfunktionen_XIX_HCP3_IONode.RP_IF_CID_ShutterFoil_Errorstate_XIX_Tracing_HCP3_IONode_XIX_CockpitInfotainment_Systemfunktionen_XIX_HCP3_IONode <-> outer port RP_IF_CID_ShutterFoil_Errorstate_XIX_HCP3_IONode  # _XIX_CI_Common_XIX_UserInterface_XIX_CI_Disp_XIX_Tracing_HCP3_IONode_XIX_CockpitInfotainment_Systemfunktionen_XIX_HCP3_IONode_XIX_CID_ShutterFoil_Errorstate
    delegate Tracing_HCP3_IONode_XIX_CockpitInfotainment_Systemfunktionen_XIX_HCP3_IONode.RP_IF_CID_LVDS_Errorstate_XIX_Tracing_HCP3_IONode_XIX_CockpitInfotainment_Systemfunktionen_XIX_HCP3_IONode <-> outer port RP_IF_CID_LVDS_Errorstate_XIX_HCP3_IONode  # _XIX_CI_Common_XIX_UserInterface_XIX_CI_Disp_XIX_Tracing_HCP3_IONode_XIX_CockpitInfotainment_Systemfunktionen_XIX_HCP3_IONode_XIX_CID_LVDS_Errorstate
    delegate Tracing_HCP3_IONode_XIX_CockpitInfotainment_Systemfunktionen_XIX_HCP3_IONode.RP_IF_CID_Backlight_OpenCircuit_XIX_Tracing_HCP3_IONode_XIX_CockpitInfotainment_Systemfunktionen_XIX_HCP3_IONode <-> outer port RP_IF_CID_Backlight_OpenCircuit_XIX_HCP3_IONode  # _XIX_CI_Common_XIX_UserInterface_XIX_CI_Disp_XIX_Tracing_HCP3_IONode_XIX_CockpitInfotainment_Systemfunktionen_XIX_HCP3_IONode_XIX_CID_Backlight_OpenCircuit
    delegate Tracing_HCP3_IONode_XIX_CockpitInfotainment_Systemfunktionen_XIX_HCP3_IONode.RP_IF_CID_FanSpeed_XIX_Tracing_HCP3_IONode_XIX_CockpitInfotainment_Systemfunktionen_XIX_HCP3_IONode <-> outer port RP_IF_CID_FanSpeed_XIX_HCP3_IONode  # _XIX_CI_Common_XIX_UserInterface_XIX_CI_Disp_XIX_Tracing_HCP3_IONode_XIX_CockpitInfotainment_Systemfunktionen_XIX_HCP3_IONode_XIX_CID_FanSpeed
    delegate Tracing_HCP3_IONode_XIX_CockpitInfotainment_Systemfunktionen_XIX_HCP3_IONode.RP_IF_CID_PCB_TempSensor_XIX_Tracing_HCP3_IONode_XIX_CockpitInfotainment_Systemfunktionen_XIX_HCP3_IONode <-> outer port RP_IF_CID_PCB_TempSensor_XIX_HCP3_IONode  # _XIX_CI_Common_XIX_UserInterface_XIX_CI_Disp_XIX_Tracing_HCP3_IONode_XIX_CockpitInfotainment_Systemfunktionen_XIX_HCP3_IONode_XIX_CID_PCB_TempSensor
    delegate Tracing_HCP3_IONode_XIX_CockpitInfotainment_Systemfunktionen_XIX_HCP3_IONode.RP_IF_CID_TempSensorMax_XIX_Tracing_HCP3_IONode_XIX_CockpitInfotainment_Systemfunktionen_XIX_HCP3_IONode <-> outer port RP_IF_CID_TempSensorMax_XIX_HCP3_IONode  # _XIX_CI_Common_XIX_UserInterface_XIX_CI_Disp_XIX_Tracing_HCP3_IONode_XIX_CockpitInfotainment_Systemfunktionen_XIX_HCP3_IONode_XIX_CID_TempSensorMax
    delegate Tracing_HCP3_IONode_XIX_CockpitInfotainment_Systemfunktionen_XIX_HCP3_IONode.RP_IF_CID_CL_30F_XIX_Tracing_HCP3_IONode_XIX_CockpitInfotainment_Systemfunktionen_XIX_HCP3_IONode <-> outer port RP_IF_CID_CL_30F_XIX_HCP3_IONode  # _XIX_CI_Common_XIX_UserInterface_XIX_CI_Disp_XIX_Tracing_HCP3_IONode_XIX_CockpitInfotainment_Systemfunktionen_XIX_HCP3_IONode_XIX_CID_CL_30F
    delegate Tracing_HCP3_IONode_XIX_CockpitInfotainment_Systemfunktionen_XIX_HCP3_IONode.RP_IF_CID_CL30_Undervolt_Error_XIX_Tracing_HCP3_IONode_XIX_CockpitInfotainment_Systemfunktionen_XIX_HCP3_IONode <-> outer port RP_IF_CID_CL30_Undervolt_Error_XIX_HCP3_IONode  # _XIX_CI_Common_XIX_UserInterface_XIX_CI_Disp_XIX_Tracing_HCP3_IONode_XIX_CockpitInfotainment_Systemfunktionen_XIX_HCP3_IONode_XIX_CID_CL30_Undervolt_Error
    delegate Tracing_HCP3_IONode_XIX_CockpitInfotainment_Systemfunktionen_XIX_HCP3_IONode.RP_IF_CID_SystemMode_XIX_Tracing_HCP3_IONode_XIX_CockpitInfotainment_Systemfunktionen_XIX_HCP3_IONode <-> outer port RP_IF_CID_SystemMode_XIX_HCP3_IONode  # _XIX_CI_Common_XIX_UserInterface_XIX_CI_Disp_XIX_Tracing_HCP3_IONode_XIX_CockpitInfotainment_Systemfunktionen_XIX_HCP3_IONode_XIX_CID_SystemMode
    delegate Tracing_HCP3_IONode_XIX_CockpitInfotainment_Systemfunktionen_XIX_HCP3_IONode.RP_IF_CID_Backlight_ShortCircuit_XIX_Tracing_HCP3_IONode_XIX_CockpitInfotainment_Systemfunktionen_XIX_HCP3_IONode <-> outer port RP_IF_CID_Backlight_ShortCircuit_XIX_HCP3_IONode  # _XIX_CI_Common_XIX_UserInterface_XIX_CI_Disp_XIX_Tracing_HCP3_IONode_XIX_CockpitInfotainment_Systemfunktionen_XIX_HCP3_IONode_XIX_CID_Backlight_ShortCircuit
    delegate Tracing_HCP3_IONode_XIX_CockpitInfotainment_Systemfunktionen_XIX_HCP3_IONode.RP_IF_CID_TempSensor_XIX_Tracing_HCP3_IONode_XIX_CockpitInfotainment_Systemfunktionen_XIX_HCP3_IONode <-> outer port RP_IF_CID_TempSensor_XIX_HCP3_IONode  # _XIX_CI_Common_XIX_UserInterface_XIX_CI_Disp_XIX_Tracing_HCP3_IONode_XIX_CockpitInfotainment_Systemfunktionen_XIX_HCP3_IONode_XIX_CID_TempSensor
    delegate Tracing_HCP3_IONode_XIX_CockpitInfotainment_Systemfunktionen_XIX_HCP3_IONode.RP_IF_CID_HDCP_Status_XIX_Tracing_HCP3_IONode_XIX_CockpitInfotainment_Systemfunktionen_XIX_HCP3_IONode <-> outer port RP_IF_CID_HDCP_Status_XIX_HCP3_IONode  # _XIX_CI_Common_XIX_UserInterface_XIX_CI_Disp_XIX_Tracing_HCP3_IONode_XIX_CockpitInfotainment_Systemfunktionen_XIX_HCP3_IONode_XIX_CID_HDCP_Status
    delegate Tracing_HCP3_IONode_XIX_CockpitInfotainment_Systemfunktionen_XIX_HCP3_IONode.RP_IF_CID_EEPROM_Error_XIX_Tracing_HCP3_IONode_XIX_CockpitInfotainment_Systemfunktionen_XIX_HCP3_IONode <-> outer port RP_IF_CID_EEPROM_Error_XIX_HCP3_IONode  # _XIX_CI_Common_XIX_UserInterface_XIX_CI_Disp_XIX_Tracing_HCP3_IONode_XIX_CockpitInfotainment_Systemfunktionen_XIX_HCP3_IONode_XIX_CID_EEPROM_Error
    delegate Tracing_HCP3_IONode_XIX_CockpitInfotainment_Systemfunktionen_XIX_HCP3_IONode.RP_IF_CID_CL30_Overvolt_Error_XIX_Tracing_HCP3_IONode_XIX_CockpitInfotainment_Systemfunktionen_XIX_HCP3_IONode <-> outer port RP_IF_CID_CL30_Overvolt_Error_XIX_HCP3_IONode  # _XIX_CI_Common_XIX_UserInterface_XIX_CI_Disp_XIX_Tracing_HCP3_IONode_XIX_CockpitInfotainment_Systemfunktionen_XIX_HCP3_IONode_XIX_CID_CL30_Overvolt_Error
    delegate Tracing_HCP3_IONode_XIX_CockpitInfotainment_Systemfunktionen_XIX_HCP3_IONode.RP_IF_CID_Touch_Errorstate_XIX_Tracing_HCP3_IONode_XIX_CockpitInfotainment_Systemfunktionen_XIX_HCP3_IONode <-> outer port RP_IF_CID_Touch_Errorstate_XIX_HCP3_IONode  # _XIX_CI_Common_XIX_UserInterface_XIX_CI_Disp_XIX_Tracing_HCP3_IONode_XIX_CockpitInfotainment_Systemfunktionen_XIX_HCP3_IONode_XIX_CID_Touch_Errorstate
    delegate VehicleComm_HCP3_IONode_XIX_CockpitInfotainment_Systemfunktionen_XIX_HCP3_IONode.RP_IF_CID_VA_Response_XIX_VehicleComm_HCP3_IONode_XIX_CockpitInfotainment_Systemfunktionen_XIX_HCP3_IONode <-> outer port RP_IF_CID_VA_Response_XIX_HCP3_IONode  # _XIX_CI_Common_XIX_UserInterface_XIX_CI_Disp_XIX_VehicleComm_HCP3_IONode_XIX_CockpitInfotainment_Systemfunktionen_XIX_HCP3_IONode_XIX_CID_VA_Response
    delegate VehicleComm_HCP3_IONode_XIX_CockpitInfotainment_Systemfunktionen_XIX_HCP3_IONode.RP_IF_CID_VA_Communication_Init_Ack_XIX_VehicleComm_HCP3_IONode_XIX_CockpitInfotainment_Systemfunktionen_XIX_HCP3_IONode <-> outer port RP_IF_CID_VA_Communication_Init_Ack_XIX_HCP3_IONode  # _XIX_CI_Common_XIX_UserInterface_XIX_CI_Disp_XIX_VehicleComm_HCP3_IONode_XIX_CockpitInfotainment_Systemfunktionen_XIX_HCP3_IONode_XIX_CID_VA_Communication_Init_Ack
    delegate VehicleComm_HCP3_IONode_XIX_CockpitInfotainment_Systemfunktionen_XIX_HCP3_IONode.RP_IF_CID_VA_Communication_Init_XIX_VehicleComm_HCP3_IONode_XIX_CockpitInfotainment_Systemfunktionen_XIX_HCP3_IONode <-> outer port RP_IF_CID_VA_Communication_Init_XIX_HCP3_IONode  # _XIX_CI_Common_XIX_UserInterface_XIX_CI_Disp_XIX_VehicleComm_HCP3_IONode_XIX_CockpitInfotainment_Systemfunktionen_XIX_HCP3_IONode_XIX_CID_VA_Communication_Init
    delegate Tracing_HCP3_IONode_XIX_CockpitInfotainment_Systemfunktionen_XIX_HCP3_IONode.RP_IF_CID_VW_SL_HW_Version_Nr_XIX_Tracing_HCP3_IONode_XIX_CockpitInfotainment_Systemfunktionen_XIX_HCP3_IONode <-> outer port RP_IF_CID_VW_SL_HW_Version_Nr_XIX_HCP3_IONode  # _XIX_CI_ECU_Info_XIX_UserInterface_XIX_CI_Disp_XIX_Tracing_HCP3_IONode_XIX_CockpitInfotainment_Systemfunktionen_XIX_HCP3_IONode_XIX_CID_VW_SL_HW_Version_Nr
    delegate Tracing_HCP3_IONode_XIX_CockpitInfotainment_Systemfunktionen_XIX_HCP3_IONode.RP_IF_CID_VW_SL_Spare_Part_Nr_Index_XIX_Tracing_HCP3_IONode_XIX_CockpitInfotainment_Systemfunktionen_XIX_HCP3_IONode <-> outer port RP_IF_CID_VW_SL_Spare_Part_Nr_Index_XIX_HCP3_IONode  # _XIX_CI_ECU_Info_XIX_UserInterface_XIX_CI_Disp_XIX_Tracing_HCP3_IONode_XIX_CockpitInfotainment_Systemfunktionen_XIX_HCP3_IONode_XIX_CID_VW_SL_Spare_Part_Nr_Index
    delegate Tracing_HCP3_IONode_XIX_CockpitInfotainment_Systemfunktionen_XIX_HCP3_IONode.RP_IF_CID_VW_SL_Spare_Part_Nr_MittelNr_XIX_Tracing_HCP3_IONode_XIX_CockpitInfotainment_Systemfunktionen_XIX_HCP3_IONode <-> outer port RP_IF_CID_VW_SL_Spare_Part_Nr_MittelNr_XIX_HCP3_IONode  # _XIX_CI_ECU_Info_XIX_UserInterface_XIX_CI_Disp_XIX_Tracing_HCP3_IONode_XIX_CockpitInfotainment_Systemfunktionen_XIX_HCP3_IONode_XIX_CID_VW_SL_Spare_Part_Nr_MittelNr
    delegate Tracing_HCP3_IONode_XIX_CockpitInfotainment_Systemfunktionen_XIX_HCP3_IONode.RP_IF_CID_VW_SL_App_SW_Version_Nr_XIX_Tracing_HCP3_IONode_XIX_CockpitInfotainment_Systemfunktionen_XIX_HCP3_IONode <-> outer port RP_IF_CID_VW_SL_App_SW_Version_Nr_XIX_HCP3_IONode  # _XIX_CI_ECU_Info_XIX_UserInterface_XIX_CI_Disp_XIX_Tracing_HCP3_IONode_XIX_CockpitInfotainment_Systemfunktionen_XIX_HCP3_IONode_XIX_CID_VW_SL_App_SW_Version_Nr
    delegate Tracing_HCP3_IONode_XIX_CockpitInfotainment_Systemfunktionen_XIX_HCP3_IONode.RP_IF_CID_VW_SL_Spare_Part_Nr_TMA_XIX_Tracing_HCP3_IONode_XIX_CockpitInfotainment_Systemfunktionen_XIX_HCP3_IONode <-> outer port RP_IF_CID_VW_SL_Spare_Part_Nr_TMA_XIX_HCP3_IONode  # _XIX_CI_ECU_Info_XIX_UserInterface_XIX_CI_Disp_XIX_Tracing_HCP3_IONode_XIX_CockpitInfotainment_Systemfunktionen_XIX_HCP3_IONode_XIX_CID_VW_SL_Spare_Part_Nr_TMA
    delegate Tracing_HCP3_IONode_XIX_CockpitInfotainment_Systemfunktionen_XIX_HCP3_IONode.RP_IF_CID_VW_SL_Spare_Part_Nr_EndNr_XIX_Tracing_HCP3_IONode_XIX_CockpitInfotainment_Systemfunktionen_XIX_HCP3_IONode <-> outer port RP_IF_CID_VW_SL_Spare_Part_Nr_EndNr_XIX_HCP3_IONode  # _XIX_CI_ECU_Info_XIX_UserInterface_XIX_CI_Disp_XIX_Tracing_HCP3_IONode_XIX_CockpitInfotainment_Systemfunktionen_XIX_HCP3_IONode_XIX_CID_VW_SL_Spare_Part_Nr_EndNr
    delegate PowerManagement_HCP3_IONode_XIX_CockpitInfotainment_Systemfunktionen_XIX_HCP3_IONode.RP_IF_ZV_Tasten_HMI_Anf_XIX_PowerManagement_HCP3_IONode_XIX_CockpitInfotainment_Systemfunktionen_XIX_HCP3_IONode <-> outer port RP_IF_ZV_Tasten_HMI_Anf_XIX_HCP3_IONode  # _XIX_CentralLocking_XIX_AccessControl_XIX_HCP4_uC1_1_XIX_PowerManagement_HCP3_IONode_XIX_CockpitInfotainment_Systemfunktionen_XIX_HCP3_IONode_XIX_ZV_Tasten_HMI_Anf
    delegate PowerManagement_HCP3_IONode_XIX_CockpitInfotainment_Systemfunktionen_XIX_HCP3_IONode.RP_IF_ZV_verriegelt_extern_ist_02_XIX_PowerManagement_HCP3_IONode_XIX_CockpitInfotainment_Systemfunktionen_XIX_HCP3_IONode <-> outer port RP_IF_ZV_verriegelt_extern_ist_02_XIX_HCP3_IONode  # _XIX_CentralLocking_XIX_AccessControl_XIX_HCP4_uC1_1_XIX_PowerManagement_HCP3_IONode_XIX_CockpitInfotainment_Systemfunktionen_XIX_HCP3_IONode_XIX_ZV_verriegelt_extern_ist_02
    delegate VehicleComm_HCP3_IONode_XIX_CockpitInfotainment_Systemfunktionen_XIX_HCP3_IONode.RP_IF_ZV_Heck_offen_XIX_VehicleComm_HCP3_IONode_XIX_CockpitInfotainment_Systemfunktionen_XIX_HCP3_IONode <-> outer port RP_IF_ZV_Heck_offen_XIX_HCP3_IONode  # _XIX_CentralLocking_XIX_AccessControl_XIX_HCP4_uC1_1_XIX_VehicleComm_HCP3_IONode_XIX_CockpitInfotainment_Systemfunktionen_XIX_HCP3_IONode_XIX_ZV_Heck_offen
    delegate FoDSlave_HCP3_XIX_FoD_XIX_HCP3_IONode.RP_IF_SG_ClampControl_01_XIX_FoDSlave_HCP3_XIX_FoD_XIX_HCP3_IONode <-> outer port RP_IF_SG_ClampControl_01_XIX_HCP3_IONode
    delegate Infrastructure_Info_El_XIX_network_infrastructure_XIX_HCP3_IONode.RP_IF_SG_ClampControl_01_XIX_Infrastructure_Info_El_XIX_network_infrastructure_XIX_HCP3_IONode <-> outer port RP_IF_SG_ClampControl_01_XIX_HCP3_IONode  # DCon_XIX_ClampControl_XIX_ClampControl_XIX_HCP4_uC1_1_XIX_Infrastructure_Info_El_XIX_network_infrastructure_XIX_HCP3_IONode_XIX_SG_ClampControl_01
    delegate PowerManagement_HCP3_IONode_XIX_CockpitInfotainment_Systemfunktionen_XIX_HCP3_IONode.RP_IF_SG_ClampControl_01_XIX_PowerManagement_HCP3_IONode_XIX_CockpitInfotainment_Systemfunktionen_XIX_HCP3_IONode <-> outer port RP_IF_SG_ClampControl_01_XIX_HCP3_IONode  # DCon_XIX_ClampControl_XIX_ClampControl_XIX_HCP4_uC1_1_XIX_PowerManagement_HCP3_IONode_XIX_CockpitInfotainment_Systemfunktionen_XIX_HCP3_IONode_XIX_SG_ClampControl_01
    delegate VehicleComm_HCP3_IONode_XIX_CockpitInfotainment_Systemfunktionen_XIX_HCP3_IONode.RP_IF_SG_ClampControl_01_XIX_VehicleComm_HCP3_IONode_XIX_CockpitInfotainment_Systemfunktionen_XIX_HCP3_IONode <-> outer port RP_IF_SG_ClampControl_01_XIX_HCP3_IONode  # DCon_XIX_ClampControl_XIX_ClampControl_XIX_HCP4_uC1_1_XIX_VehicleComm_HCP3_IONode_XIX_CockpitInfotainment_Systemfunktionen_XIX_HCP3_IONode_XIX_SG_ClampControl_01
    delegate WUM_Client3_XIX_WUM_XIX_HCP3_IONode.RP_IF_SG_ClampControl_01_XIX_WUM_Client3_XIX_WUM_XIX_HCP3_IONode <-> outer port RP_IF_SG_ClampControl_01_XIX_HCP3_IONode
    delegate PowerManagement_HCP3_IONode_XIX_CockpitInfotainment_Systemfunktionen_XIX_HCP3_IONode.RP_IF_KL_Geblaese_Status_XIX_PowerManagement_HCP3_IONode_XIX_CockpitInfotainment_Systemfunktionen_XIX_HCP3_IONode <-> outer port RP_IF_KL_Geblaese_Status_XIX_HCP3_IONode  # _XIX_ClimateControl_XIX_Klima_XIX_HCP4_uC2_2_XIX_PowerManagement_HCP3_IONode_XIX_CockpitInfotainment_Systemfunktionen_XIX_HCP3_IONode_XIX_KL_Geblaese_Status
    delegate TankAlgorithm_XIX_Tank_XIX_HCP3_IONode.RP_IF_CE_FlgOvf_VolCns_XIX_TankAlgorithm_XIX_Tank_XIX_HCP3_IONode <-> outer port RP_IF_CE_FlgOvf_VolCns_XIX_HCP3_IONode
    delegate TankAlgorithm_XIX_Tank_XIX_HCP3_IONode.RP_IF_CE_VolCns_XIX_TankAlgorithm_XIX_Tank_XIX_HCP3_IONode <-> outer port RP_IF_CE_VolCns_XIX_HCP3_IONode
    delegate diagnosis_infrastructure_Info_El_XIX_diagnosis_infrastructure_XIX_HCP3_IONode.RP_IF_DW_Kilometerstand_XIX_diagnosis_infrastructure_Info_El_XIX_diagnosis_infrastructure_XIX_HCP3_IONode <-> outer port RP_IF_DW_Kilometerstand_XIX_HCP3_IONode  # _XIX_DiagnoseWegstrecke_XIX_DiagBasis_XIX_HCP5_P1_Gateway_XIX_diagnosis_infrastructure_Info_El_XIX_diagnosis_infrastructure_XIX_HCP3_IONode_XIX_DW_Kilometerstand
    delegate TankAlgorithm_XIX_Tank_XIX_HCP3_IONode.RP_IF_DTSO_StPTEgySrc_XIX_TankAlgorithm_XIX_Tank_XIX_HCP3_IONode <-> outer port RP_IF_DTSO_StPTEgySrc_XIX_HCP3_IONode
    delegate TankAlgorithm_XIX_Tank_XIX_HCP3_IONode.RP_IF_DTSO_StPrpUnitAcvWhl_XIX_TankAlgorithm_XIX_Tank_XIX_HCP3_IONode <-> outer port RP_IF_DTSO_StPrpUnitAcvWhl_XIX_HCP3_IONode
    delegate PowerManagement_HCP3_IONode_XIX_CockpitInfotainment_Systemfunktionen_XIX_HCP3_IONode.RP_IF_FID_LVDS_State_XIX_PowerManagement_HCP3_IONode_XIX_CockpitInfotainment_Systemfunktionen_XIX_HCP3_IONode <-> outer port RP_IF_FID_LVDS_State_XIX_HCP3_IONode  # _XIX_FIDAnzeigen_XIX_Fahrerinformation_XIX_Kombi_XIX_PowerManagement_HCP3_IONode_XIX_CockpitInfotainment_Systemfunktionen_XIX_HCP3_IONode_XIX_FID_LVDS_State
    delegate PowerManagement_HCP3_IONode_XIX_CockpitInfotainment_Systemfunktionen_XIX_HCP3_IONode.RP_IF_FID_State_XIX_PowerManagement_HCP3_IONode_XIX_CockpitInfotainment_Systemfunktionen_XIX_HCP3_IONode <-> outer port RP_IF_FID_State_XIX_HCP3_IONode  # _XIX_FIDAnzeigen_XIX_Fahrerinformation_XIX_Kombi_XIX_PowerManagement_HCP3_IONode_XIX_CockpitInfotainment_Systemfunktionen_XIX_HCP3_IONode_XIX_FID_State
    delegate Tracing_HCP3_IONode_XIX_CockpitInfotainment_Systemfunktionen_XIX_HCP3_IONode.RP_IF_FID_SW_inconsistent_XIX_Tracing_HCP3_IONode_XIX_CockpitInfotainment_Systemfunktionen_XIX_HCP3_IONode <-> outer port RP_IF_FID_SW_inconsistent_XIX_HCP3_IONode  # _XIX_FIDAnzeigen_XIX_Fahrerinformation_XIX_Kombi_XIX_Tracing_HCP3_IONode_XIX_CockpitInfotainment_Systemfunktionen_XIX_HCP3_IONode_XIX_FID_SW_inconsistent
    delegate Tracing_HCP3_IONode_XIX_CockpitInfotainment_Systemfunktionen_XIX_HCP3_IONode.RP_IF_FID_EEPROM_Error_XIX_Tracing_HCP3_IONode_XIX_CockpitInfotainment_Systemfunktionen_XIX_HCP3_IONode <-> outer port RP_IF_FID_EEPROM_Error_XIX_HCP3_IONode  # _XIX_FIDAnzeigen_XIX_Fahrerinformation_XIX_Kombi_XIX_Tracing_HCP3_IONode_XIX_CockpitInfotainment_Systemfunktionen_XIX_HCP3_IONode_XIX_FID_EEPROM_Error
    delegate Tracing_HCP3_IONode_XIX_CockpitInfotainment_Systemfunktionen_XIX_HCP3_IONode.RP_IF_FID_TempSensor_XIX_Tracing_HCP3_IONode_XIX_CockpitInfotainment_Systemfunktionen_XIX_HCP3_IONode <-> outer port RP_IF_FID_TempSensor_XIX_HCP3_IONode  # _XIX_FIDAnzeigen_XIX_Fahrerinformation_XIX_Kombi_XIX_Tracing_HCP3_IONode_XIX_CockpitInfotainment_Systemfunktionen_XIX_HCP3_IONode_XIX_FID_TempSensor
    delegate Tracing_HCP3_IONode_XIX_CockpitInfotainment_Systemfunktionen_XIX_HCP3_IONode.RP_IF_FID_SystemMode_XIX_Tracing_HCP3_IONode_XIX_CockpitInfotainment_Systemfunktionen_XIX_HCP3_IONode <-> outer port RP_IF_FID_SystemMode_XIX_HCP3_IONode  # _XIX_FIDAnzeigen_XIX_Fahrerinformation_XIX_Kombi_XIX_Tracing_HCP3_IONode_XIX_CockpitInfotainment_Systemfunktionen_XIX_HCP3_IONode_XIX_FID_SystemMode
    delegate Tracing_HCP3_IONode_XIX_CockpitInfotainment_Systemfunktionen_XIX_HCP3_IONode.RP_IF_FID_CL_30F_XIX_Tracing_HCP3_IONode_XIX_CockpitInfotainment_Systemfunktionen_XIX_HCP3_IONode <-> outer port RP_IF_FID_CL_30F_XIX_HCP3_IONode  # _XIX_FIDAnzeigen_XIX_Fahrerinformation_XIX_Kombi_XIX_Tracing_HCP3_IONode_XIX_CockpitInfotainment_Systemfunktionen_XIX_HCP3_IONode_XIX_FID_CL_30F
    delegate Tracing_HCP3_IONode_XIX_CockpitInfotainment_Systemfunktionen_XIX_HCP3_IONode.RP_IF_FID_Temp_Error_XIX_Tracing_HCP3_IONode_XIX_CockpitInfotainment_Systemfunktionen_XIX_HCP3_IONode <-> outer port RP_IF_FID_Temp_Error_XIX_HCP3_IONode  # _XIX_FIDAnzeigen_XIX_Fahrerinformation_XIX_Kombi_XIX_Tracing_HCP3_IONode_XIX_CockpitInfotainment_Systemfunktionen_XIX_HCP3_IONode_XIX_FID_Temp_Error
    delegate Tracing_HCP3_IONode_XIX_CockpitInfotainment_Systemfunktionen_XIX_HCP3_IONode.RP_IF_FID_Backlight_OpenCircuit_XIX_Tracing_HCP3_IONode_XIX_CockpitInfotainment_Systemfunktionen_XIX_HCP3_IONode <-> outer port RP_IF_FID_Backlight_OpenCircuit_XIX_HCP3_IONode  # _XIX_FIDAnzeigen_XIX_Fahrerinformation_XIX_Kombi_XIX_Tracing_HCP3_IONode_XIX_CockpitInfotainment_Systemfunktionen_XIX_HCP3_IONode_XIX_FID_Backlight_OpenCircuit
    delegate Tracing_HCP3_IONode_XIX_CockpitInfotainment_Systemfunktionen_XIX_HCP3_IONode.RP_IF_FID_PCB_Temp_Error_XIX_Tracing_HCP3_IONode_XIX_CockpitInfotainment_Systemfunktionen_XIX_HCP3_IONode <-> outer port RP_IF_FID_PCB_Temp_Error_XIX_HCP3_IONode  # _XIX_FIDAnzeigen_XIX_Fahrerinformation_XIX_Kombi_XIX_Tracing_HCP3_IONode_XIX_CockpitInfotainment_Systemfunktionen_XIX_HCP3_IONode_XIX_FID_PCB_Temp_Error
    delegate Tracing_HCP3_IONode_XIX_CockpitInfotainment_Systemfunktionen_XIX_HCP3_IONode.RP_IF_FID_Photosensor_XIX_Tracing_HCP3_IONode_XIX_CockpitInfotainment_Systemfunktionen_XIX_HCP3_IONode <-> outer port RP_IF_FID_Photosensor_XIX_HCP3_IONode  # _XIX_FIDAnzeigen_XIX_Fahrerinformation_XIX_Kombi_XIX_Tracing_HCP3_IONode_XIX_CockpitInfotainment_Systemfunktionen_XIX_HCP3_IONode_XIX_FID_Photosensor
    delegate Tracing_HCP3_IONode_XIX_CockpitInfotainment_Systemfunktionen_XIX_HCP3_IONode.RP_IF_FID_CL30_Overvolt_Error_XIX_Tracing_HCP3_IONode_XIX_CockpitInfotainment_Systemfunktionen_XIX_HCP3_IONode <-> outer port RP_IF_FID_CL30_Overvolt_Error_XIX_HCP3_IONode  # _XIX_FIDAnzeigen_XIX_Fahrerinformation_XIX_Kombi_XIX_Tracing_HCP3_IONode_XIX_CockpitInfotainment_Systemfunktionen_XIX_HCP3_IONode_XIX_FID_CL30_Overvolt_Error
    delegate Tracing_HCP3_IONode_XIX_CockpitInfotainment_Systemfunktionen_XIX_HCP3_IONode.RP_IF_FID_DispDerating_XIX_Tracing_HCP3_IONode_XIX_CockpitInfotainment_Systemfunktionen_XIX_HCP3_IONode <-> outer port RP_IF_FID_DispDerating_XIX_HCP3_IONode  # _XIX_FIDAnzeigen_XIX_Fahrerinformation_XIX_Kombi_XIX_Tracing_HCP3_IONode_XIX_CockpitInfotainment_Systemfunktionen_XIX_HCP3_IONode_XIX_FID_DispDerating
    delegate Tracing_HCP3_IONode_XIX_CockpitInfotainment_Systemfunktionen_XIX_HCP3_IONode.RP_IF_FID_OperatingTime_min_XIX_Tracing_HCP3_IONode_XIX_CockpitInfotainment_Systemfunktionen_XIX_HCP3_IONode <-> outer port RP_IF_FID_OperatingTime_min_XIX_HCP3_IONode  # _XIX_FIDAnzeigen_XIX_Fahrerinformation_XIX_Kombi_XIX_Tracing_HCP3_IONode_XIX_CockpitInfotainment_Systemfunktionen_XIX_HCP3_IONode_XIX_FID_OperatingTime_min
    delegate Tracing_HCP3_IONode_XIX_CockpitInfotainment_Systemfunktionen_XIX_HCP3_IONode.RP_IF_FID_PCB_TempSensorMax_XIX_Tracing_HCP3_IONode_XIX_CockpitInfotainment_Systemfunktionen_XIX_HCP3_IONode <-> outer port RP_IF_FID_PCB_TempSensorMax_XIX_HCP3_IONode  # _XIX_FIDAnzeigen_XIX_Fahrerinformation_XIX_Kombi_XIX_Tracing_HCP3_IONode_XIX_CockpitInfotainment_Systemfunktionen_XIX_HCP3_IONode_XIX_FID_PCB_TempSensorMax
    delegate Tracing_HCP3_IONode_XIX_CockpitInfotainment_Systemfunktionen_XIX_HCP3_IONode.RP_IF_FID_CL30_Undervolt_Error_XIX_Tracing_HCP3_IONode_XIX_CockpitInfotainment_Systemfunktionen_XIX_HCP3_IONode <-> outer port RP_IF_FID_CL30_Undervolt_Error_XIX_HCP3_IONode  # _XIX_FIDAnzeigen_XIX_Fahrerinformation_XIX_Kombi_XIX_Tracing_HCP3_IONode_XIX_CockpitInfotainment_Systemfunktionen_XIX_HCP3_IONode_XIX_FID_CL30_Undervolt_Error
    delegate Tracing_HCP3_IONode_XIX_CockpitInfotainment_Systemfunktionen_XIX_HCP3_IONode.RP_IF_FID_PCB_TempSensor_XIX_Tracing_HCP3_IONode_XIX_CockpitInfotainment_Systemfunktionen_XIX_HCP3_IONode <-> outer port RP_IF_FID_PCB_TempSensor_XIX_HCP3_IONode  # _XIX_FIDAnzeigen_XIX_Fahrerinformation_XIX_Kombi_XIX_Tracing_HCP3_IONode_XIX_CockpitInfotainment_Systemfunktionen_XIX_HCP3_IONode_XIX_FID_PCB_TempSensor
    delegate Tracing_HCP3_IONode_XIX_CockpitInfotainment_Systemfunktionen_XIX_HCP3_IONode.RP_IF_FID_TempSensorMax_XIX_Tracing_HCP3_IONode_XIX_CockpitInfotainment_Systemfunktionen_XIX_HCP3_IONode <-> outer port RP_IF_FID_TempSensorMax_XIX_HCP3_IONode  # _XIX_FIDAnzeigen_XIX_Fahrerinformation_XIX_Kombi_XIX_Tracing_HCP3_IONode_XIX_CockpitInfotainment_Systemfunktionen_XIX_HCP3_IONode_XIX_FID_TempSensorMax
    delegate Tracing_HCP3_IONode_XIX_CockpitInfotainment_Systemfunktionen_XIX_HCP3_IONode.RP_IF_FID_Backlight_ShortCircuit_XIX_Tracing_HCP3_IONode_XIX_CockpitInfotainment_Systemfunktionen_XIX_HCP3_IONode <-> outer port RP_IF_FID_Backlight_ShortCircuit_XIX_HCP3_IONode  # _XIX_FIDAnzeigen_XIX_Fahrerinformation_XIX_Kombi_XIX_Tracing_HCP3_IONode_XIX_CockpitInfotainment_Systemfunktionen_XIX_HCP3_IONode_XIX_FID_Backlight_ShortCircuit
    delegate Tracing_HCP3_IONode_XIX_CockpitInfotainment_Systemfunktionen_XIX_HCP3_IONode.RP_IF_FID_OperatingTime_hr_XIX_Tracing_HCP3_IONode_XIX_CockpitInfotainment_Systemfunktionen_XIX_HCP3_IONode <-> outer port RP_IF_FID_OperatingTime_hr_XIX_HCP3_IONode  # _XIX_FIDAnzeigen_XIX_Fahrerinformation_XIX_Kombi_XIX_Tracing_HCP3_IONode_XIX_CockpitInfotainment_Systemfunktionen_XIX_HCP3_IONode_XIX_FID_OperatingTime_hr
    delegate Tracing_HCP3_IONode_XIX_CockpitInfotainment_Systemfunktionen_XIX_HCP3_IONode.RP_IF_FID_LVDS_Errorstate_XIX_Tracing_HCP3_IONode_XIX_CockpitInfotainment_Systemfunktionen_XIX_HCP3_IONode <-> outer port RP_IF_FID_LVDS_Errorstate_XIX_HCP3_IONode  # _XIX_FIDAnzeigen_XIX_Fahrerinformation_XIX_Kombi_XIX_Tracing_HCP3_IONode_XIX_CockpitInfotainment_Systemfunktionen_XIX_HCP3_IONode_XIX_FID_LVDS_Errorstate
    delegate VehicleComm_HCP3_IONode_XIX_CockpitInfotainment_Systemfunktionen_XIX_HCP3_IONode.RP_IF_FID_VA_Response_XIX_VehicleComm_HCP3_IONode_XIX_CockpitInfotainment_Systemfunktionen_XIX_HCP3_IONode <-> outer port RP_IF_FID_VA_Response_XIX_HCP3_IONode  # _XIX_FIDAnzeigen_XIX_Fahrerinformation_XIX_Kombi_XIX_VehicleComm_HCP3_IONode_XIX_CockpitInfotainment_Systemfunktionen_XIX_HCP3_IONode_XIX_FID_VA_Response
    delegate VehicleComm_HCP3_IONode_XIX_CockpitInfotainment_Systemfunktionen_XIX_HCP3_IONode.RP_IF_FID_VA_Communication_Init_Ack_XIX_VehicleComm_HCP3_IONode_XIX_CockpitInfotainment_Systemfunktionen_XIX_HCP3_IONode <-> outer port RP_IF_FID_VA_Communication_Init_Ack_XIX_HCP3_IONode  # _XIX_FIDAnzeigen_XIX_Fahrerinformation_XIX_Kombi_XIX_VehicleComm_HCP3_IONode_XIX_CockpitInfotainment_Systemfunktionen_XIX_HCP3_IONode_XIX_FID_VA_Communication_Init_Ack
    delegate VehicleComm_HCP3_IONode_XIX_CockpitInfotainment_Systemfunktionen_XIX_HCP3_IONode.RP_IF_FID_VA_Communication_Init_XIX_VehicleComm_HCP3_IONode_XIX_CockpitInfotainment_Systemfunktionen_XIX_HCP3_IONode <-> outer port RP_IF_FID_VA_Communication_Init_XIX_HCP3_IONode  # _XIX_FIDAnzeigen_XIX_Fahrerinformation_XIX_Kombi_XIX_VehicleComm_HCP3_IONode_XIX_CockpitInfotainment_Systemfunktionen_XIX_HCP3_IONode_XIX_FID_VA_Communication_Init
    delegate VehicleComm_HCP3_IONode_XIX_CockpitInfotainment_Systemfunktionen_XIX_HCP3_IONode.RP_IF_FID_LVDS_Errorstate_XIX_VehicleComm_HCP3_IONode_XIX_CockpitInfotainment_Systemfunktionen_XIX_HCP3_IONode <-> outer port RP_IF_FID_LVDS_Errorstate_XIX_HCP3_IONode  # _XIX_FIDAnzeigen_XIX_Fahrerinformation_XIX_Kombi_XIX_VehicleComm_HCP3_IONode_XIX_CockpitInfotainment_Systemfunktionen_XIX_HCP3_IONode_XIX_FID_LVDS_Errorstate
    delegate VehicleComm_HCP3_IONode_XIX_CockpitInfotainment_Systemfunktionen_XIX_HCP3_IONode.RP_IF_FID_SW_inconsistent_XIX_VehicleComm_HCP3_IONode_XIX_CockpitInfotainment_Systemfunktionen_XIX_HCP3_IONode <-> outer port RP_IF_FID_SW_inconsistent_XIX_HCP3_IONode  # _XIX_FIDAnzeigen_XIX_Fahrerinformation_XIX_Kombi_XIX_VehicleComm_HCP3_IONode_XIX_CockpitInfotainment_Systemfunktionen_XIX_HCP3_IONode_XIX_FID_SW_inconsistent
    delegate FoDSlave_HCP3_XIX_FoD_XIX_HCP3_IONode.RP_IF_FoD_Info_El_Req_Eth_Data_XIX_FoDSlave_HCP3_XIX_FoD_XIX_HCP3_IONode <-> outer port RP_IF_FoD_Info_El_Req_Eth_Data_XIX_HCP3_IONode
    delegate FoDSlave_HCP3_XIX_FoD_XIX_HCP3_IONode.RP_IF_SOK_FoD_Info_El_Req_Eth_Challeng_XIX_FoDSlave_HCP3_XIX_FoD_XIX_HCP3_IONode <-> outer port RP_IF_SOK_FoD_Info_El_Req_Eth_Challeng_XIX_HCP3_IONode
    delegate FoDSlave_HCP3_XIX_FoD_XIX_HCP3_IONode.SP_IF_FoD_Info_El_Resp_Eth_Data_XIX_FoDSlave_HCP3_XIX_FoD_XIX_HCP3_IONode <-> outer port SP_IF_FoD_Info_El_Resp_Eth_Data_XIX_HCP3_IONode
    delegate FoDSlave_HCP3_XIX_FoD_XIX_HCP3_IONode.SP_IF_SOK_FoD_Info_El_Resp_Eth_Challen_XIX_FoDSlave_HCP3_XIX_FoD_XIX_HCP3_IONode <-> outer port SP_IF_SOK_FoD_Info_El_Resp_Eth_Challen_XIX_HCP3_IONode
    delegate Infrastructure_Info_El_XIX_network_infrastructure_XIX_HCP3_IONode.RP_IF_IP_TS_CTO_01_Data_XIX_Infrastructure_Info_El_XIX_network_infrastructure_XIX_HCP3_IONode <-> outer port RP_IF_IP_TS_CTO_01_Data_XIX_HCP3_IONode
    delegate Infrastructure_Info_El_XIX_network_infrastructure_XIX_HCP3_IONode.RP_IF_IP_TS_DTO_{01..04}_Data_XIX_Infrastructure_Info_El_XIX_network_infrastructure_XIX_HCP3_IONode <-> outer port RP_IF_IP_TS_DTO_{01..04}_Data_XIX_HCP3_IONode
    delegate Infrastructure_Info_El_XIX_network_infrastructure_XIX_HCP3_IONode.RP_SOMEIPTestabilityClientEvents <-> outer port SOMEIPTestabilityClientEvents  # _XIX_Grundumfang_XIX_TestSysIP_XIX_Infrastructure_Info_El_XIX_network_infrastructure_XIX_HCP3_IONode_XIX_SOMEIPTestabilityClientEvents
    delegate Infrastructure_Info_El_XIX_network_infrastructure_XIX_HCP3_IONode.RP_SOMEIPTestabilityClientMethods <-> outer port SOMEIPTestabilityClientMethods  # _XIX_Grundumfang_XIX_TestSysIP_XIX_Infrastructure_Info_El_XIX_network_infrastructure_XIX_HCP3_IONode_XIX_SOMEIPTestabilityClientMethods
    delegate VehicleComm_HCP3_IONode_XIX_CockpitInfotainment_Systemfunktionen_XIX_HCP3_IONode.RP_IF_HWP_HMI_State_XIX_VehicleComm_HCP3_IONode_XIX_CockpitInfotainment_Systemfunktionen_XIX_HCP3_IONode <-> outer port RP_IF_HWP_HMI_State_XIX_HCP3_IONode  # _XIX_HWP_StrategicModuleComfort_XIX_HAF_XIX_HCP21_IPM_ACA_XIX_VehicleComm_HCP3_IONode_XIX_CockpitInfotainment_Systemfunktionen_XIX_HCP3_IONode_XIX_HWP_HMI_State
    delegate VehicleComm_HCP3_IONode_XIX_CockpitInfotainment_Systemfunktionen_XIX_HCP3_IONode.RP_IF_SG_HWP_01_XIX_VehicleComm_HCP3_IONode_XIX_CockpitInfotainment_Systemfunktionen_XIX_HCP3_IONode <-> outer port RP_IF_SG_HWP_01_XIX_HCP3_IONode  # DCon_XIX_HWP_StrategicModuleSafety_XIX_HAF_XIX_HCP21_SMH_SAFE_XIX_VehicleComm_HCP3_IONode_XIX_CockpitInfotainment_Systemfunktionen_XIX_HCP3_IONode_XIX_SG_HWP_01
    delegate VehicleComm_HCP3_IONode_XIX_CockpitInfotainment_Systemfunktionen_XIX_HCP3_IONode.RP_IF_SG_WFS_02_XIX_VehicleComm_HCP3_IONode_XIX_CockpitInfotainment_Systemfunktionen_XIX_HCP3_IONode <-> outer port RP_IF_SG_WFS_02_XIX_HCP3_IONode  # DCon_XIX_Immobilizer_XIX_WFS6_XIX_HCP4_uC1_1_XIX_VehicleComm_HCP3_IONode_XIX_CockpitInfotainment_Systemfunktionen_XIX_HCP3_IONode_XIX_SG_WFS_02
    delegate diagnosis_infrastructure_Info_El_XIX_diagnosis_infrastructure_XIX_HCP3_IONode.RP_IF_SG_WFS_02_XIX_diagnosis_infrastructure_Info_El_XIX_diagnosis_infrastructure_XIX_HCP3_IONode <-> outer port RP_IF_SG_WFS_02_XIX_HCP3_IONode  # DCon_XIX_Immobilizer_XIX_WFS6_XIX_HCP4_uC1_1_XIX_diagnosis_infrastructure_Info_El_XIX_diagnosis_infrastructure_XIX_HCP3_IONode_XIX_SG_WFS_02
    delegate Infrastructure_Info_El_XIX_network_infrastructure_XIX_HCP3_IONode.RP_IF_AMP_Nachlauftyp_XIX_Infrastructure_Info_El_XIX_network_infrastructure_XIX_HCP3_IONode <-> outer port RP_IF_AMP_Nachlauftyp_XIX_HCP3_IONode  # _XIX_Infrastructure_AMP_XIX_network_infrastructure_XIX_DSP_XIX_Infrastructure_Info_El_XIX_network_infrastructure_XIX_HCP3_IONode_XIX_AMP_Nachlauftyp
    delegate VNSM3_1_XIX_WUSL_XIX_HCP3_IONode.RP_IF_NM_AMP_FCIB_XIX_VNSM3_1_XIX_WUSL_XIX_HCP3_IONode <-> outer port RP_IF_NM_AMP_FCIB_XIX_HCP3_IONode
    delegate Infrastructure_Info_El_XIX_network_infrastructure_XIX_HCP3_IONode.RP_IF_NM_CCF_CBV_AWB_XIX_Infrastructure_Info_El_XIX_network_infrastructure_XIX_HCP3_IONode <-> outer port RP_IF_NM_CCF_CBV_AWB_XIX_HCP3_IONode  # _XIX_Infrastructure_CCF_XIX_network_infrastructure_XIX_BKE_XIX_Infrastructure_Info_El_XIX_network_infrastructure_XIX_HCP3_IONode_XIX_NM_CCF_CBV_AWB
    delegate Infrastructure_Info_El_XIX_network_infrastructure_XIX_HCP3_IONode.RP_IF_NM_CCF_CBV_CRI_XIX_Infrastructure_Info_El_XIX_network_infrastructure_XIX_HCP3_IONode <-> outer port RP_IF_NM_CCF_CBV_CRI_XIX_HCP3_IONode  # _XIX_Infrastructure_CCF_XIX_network_infrastructure_XIX_BKE_XIX_Infrastructure_Info_El_XIX_network_infrastructure_XIX_HCP3_IONode_XIX_NM_CCF_CBV_CRI
    delegate Infrastructure_Info_El_XIX_network_infrastructure_XIX_HCP3_IONode.RP_IF_NM_CCF_NM_State_XIX_Infrastructure_Info_El_XIX_network_infrastructure_XIX_HCP3_IONode <-> outer port RP_IF_NM_CCF_NM_State_XIX_HCP3_IONode  # _XIX_Infrastructure_CCF_XIX_network_infrastructure_XIX_BKE_XIX_Infrastructure_Info_El_XIX_network_infrastructure_XIX_HCP3_IONode_XIX_NM_CCF_NM_State
    delegate Infrastructure_Info_El_XIX_network_infrastructure_XIX_HCP3_IONode.RP_IF_NM_CCF_FCAB_XIX_Infrastructure_Info_El_XIX_network_infrastructure_XIX_HCP3_IONode <-> outer port RP_IF_NM_CCF_FCAB_XIX_HCP3_IONode  # _XIX_Infrastructure_CCF_XIX_network_infrastructure_XIX_BKE_XIX_Infrastructure_Info_El_XIX_network_infrastructure_XIX_HCP3_IONode_XIX_NM_CCF_FCAB
    delegate VNSM3_1_XIX_WUSL_XIX_HCP3_IONode.RP_IF_NM_CCF_FCAB_XIX_VNSM3_1_XIX_WUSL_XIX_HCP3_IONode <-> outer port RP_IF_NM_CCF_FCAB_XIX_HCP3_IONode
    delegate VNSM3_1_XIX_WUSL_XIX_HCP3_IONode.RP_IF_NM_CCF_FCIB_XIX_VNSM3_1_XIX_WUSL_XIX_HCP3_IONode <-> outer port RP_IF_NM_CCF_FCIB_XIX_HCP3_IONode
    delegate WUM_Client3_XIX_WUM_XIX_HCP3_IONode.RP_IF_NM_CCF_CBV_AWB_XIX_WUM_Client3_XIX_WUM_XIX_HCP3_IONode <-> outer port RP_IF_NM_CCF_CBV_AWB_XIX_HCP3_IONode
    delegate WUM_Client3_XIX_WUM_XIX_HCP3_IONode.RP_IF_NM_CCF_NM_State_XIX_WUM_Client3_XIX_WUM_XIX_HCP3_IONode <-> outer port RP_IF_NM_CCF_NM_State_XIX_HCP3_IONode
    delegate WUM_Client3_XIX_WUM_XIX_HCP3_IONode.RP_IF_NM_CCF_SNI_10_XIX_WUM_Client3_XIX_WUM_XIX_HCP3_IONode <-> outer port RP_IF_NM_CCF_SNI_10_XIX_HCP3_IONode
    delegate Infrastructure_Info_El_XIX_network_infrastructure_XIX_HCP3_IONode.RP_IF_NM_CID_FCAB_XIX_Infrastructure_Info_El_XIX_network_infrastructure_XIX_HCP3_IONode <-> outer port RP_IF_NM_CID_FCAB_XIX_HCP3_IONode  # _XIX_Infrastructure_CID_XIX_network_infrastructure_XIX_CI_Disp_XIX_Infrastructure_Info_El_XIX_network_infrastructure_XIX_HCP3_IONode_XIX_NM_CID_FCAB
    delegate Infrastructure_Info_El_XIX_network_infrastructure_XIX_HCP3_IONode.RP_IF_CID_Nachlauftyp_XIX_Infrastructure_Info_El_XIX_network_infrastructure_XIX_HCP3_IONode <-> outer port RP_IF_CID_Nachlauftyp_XIX_HCP3_IONode  # _XIX_Infrastructure_CID_XIX_network_infrastructure_XIX_CI_Disp_XIX_Infrastructure_Info_El_XIX_network_infrastructure_XIX_HCP3_IONode_XIX_CID_Nachlauftyp
    delegate VNSM3_1_XIX_WUSL_XIX_HCP3_IONode.RP_IF_NM_CID_FCAB_XIX_VNSM3_1_XIX_WUSL_XIX_HCP3_IONode <-> outer port RP_IF_NM_CID_FCAB_XIX_HCP3_IONode
    delegate VNSM3_1_XIX_WUSL_XIX_HCP3_IONode.RP_IF_NM_CID_FCIB_XIX_VNSM3_1_XIX_WUSL_XIX_HCP3_IONode <-> outer port RP_IF_NM_CID_FCIB_XIX_HCP3_IONode
    delegate WUM_Client3_XIX_WUM_XIX_HCP3_IONode.RP_IF_NM_CID_CBV_AWB_XIX_WUM_Client3_XIX_WUM_XIX_HCP3_IONode <-> outer port RP_IF_NM_CID_CBV_AWB_XIX_HCP3_IONode
    delegate WUM_Client3_XIX_WUM_XIX_HCP3_IONode.RP_IF_NM_CID_NM_State_XIX_WUM_Client3_XIX_WUM_XIX_HCP3_IONode <-> outer port RP_IF_NM_CID_NM_State_XIX_HCP3_IONode
    delegate WUM_Client3_XIX_WUM_XIX_HCP3_IONode.RP_IF_NM_CID_SNI_10_XIX_WUM_Client3_XIX_WUM_XIX_HCP3_IONode <-> outer port RP_IF_NM_CID_SNI_10_XIX_HCP3_IONode
    delegate Infrastructure_Info_El_XIX_network_infrastructure_XIX_HCP3_IONode.RP_IF_DispKBI_FS_Nachlauftyp_XIX_Infrastructure_Info_El_XIX_network_infrastructure_XIX_HCP3_IONode <-> outer port RP_IF_DispKBI_FS_Nachlauftyp_XIX_HCP3_IONode  # _XIX_Infrastructure_DispKBI_FS_XIX_network_infrastructure_XIX_Main_Disp_XIX_Infrastructure_Info_El_XIX_network_infrastructure_XIX_HCP3_IONode_XIX_DispKBI_FS_Nachlauftyp
    delegate Infrastructure_Info_El_XIX_network_infrastructure_XIX_HCP3_IONode.RP_IF_NM_DispKBI_FS_FCAB_XIX_Infrastructure_Info_El_XIX_network_infrastructure_XIX_HCP3_IONode <-> outer port RP_IF_NM_DispKBI_FS_FCAB_XIX_HCP3_IONode  # _XIX_Infrastructure_DispKBI_FS_XIX_network_infrastructure_XIX_Main_Disp_XIX_Infrastructure_Info_El_XIX_network_infrastructure_XIX_HCP3_IONode_XIX_NM_DispKBI_FS_FCAB
    delegate VNSM3_1_XIX_WUSL_XIX_HCP3_IONode.RP_IF_NM_DispKBI_FS_FCIB_XIX_VNSM3_1_XIX_WUSL_XIX_HCP3_IONode <-> outer port RP_IF_NM_DispKBI_FS_FCIB_XIX_HCP3_IONode  # _XIX_Infrastructure_DispKBI_FS_XIX_network_infrastructure_XIX_Main_Disp_XIX_VNSM3_1_XIX_WUSL_XIX_HCP3_IONode_XIX_NM_DispKBI_FS_FCIB
    delegate VNSM3_1_XIX_WUSL_XIX_HCP3_IONode.RP_IF_NM_DispKBI_FS_FCAB_XIX_VNSM3_1_XIX_WUSL_XIX_HCP3_IONode <-> outer port RP_IF_NM_DispKBI_FS_FCAB_XIX_HCP3_IONode  # _XIX_Infrastructure_DispKBI_FS_XIX_network_infrastructure_XIX_Main_Disp_XIX_VNSM3_1_XIX_WUSL_XIX_HCP3_IONode_XIX_NM_DispKBI_FS_FCAB
    delegate WUM_Client3_XIX_WUM_XIX_HCP3_IONode.RP_IF_NM_DispKBI_FS_SNI_10_XIX_WUM_Client3_XIX_WUM_XIX_HCP3_IONode <-> outer port RP_IF_NM_DispKBI_FS_SNI_10_XIX_HCP3_IONode  # _XIX_Infrastructure_DispKBI_FS_XIX_network_infrastructure_XIX_Main_Disp_XIX_WUM_Client3_XIX_WUM_XIX_HCP3_IONode_XIX_NM_DispKBI_FS_SNI_10
    delegate WUM_Client3_XIX_WUM_XIX_HCP3_IONode.RP_IF_NM_DispKBI_FS_NM_State_XIX_WUM_Client3_XIX_WUM_XIX_HCP3_IONode <-> outer port RP_IF_NM_DispKBI_FS_NM_State_XIX_HCP3_IONode  # _XIX_Infrastructure_DispKBI_FS_XIX_network_infrastructure_XIX_Main_Disp_XIX_WUM_Client3_XIX_WUM_XIX_HCP3_IONode_XIX_NM_DispKBI_FS_NM_State
    delegate WUM_Client3_XIX_WUM_XIX_HCP3_IONode.RP_IF_NM_DispKBI_FS_CBV_AWB_XIX_WUM_Client3_XIX_WUM_XIX_HCP3_IONode <-> outer port RP_IF_NM_DispKBI_FS_CBV_AWB_XIX_HCP3_IONode  # _XIX_Infrastructure_DispKBI_FS_XIX_network_infrastructure_XIX_Main_Disp_XIX_WUM_Client3_XIX_WUM_XIX_HCP3_IONode_XIX_NM_DispKBI_FS_CBV_AWB
    delegate Infrastructure_Info_El_XIX_network_infrastructure_XIX_HCP3_IONode.RP_IF_NM_Gateway_FCAB_XIX_Infrastructure_Info_El_XIX_network_infrastructure_XIX_HCP3_IONode <-> outer port RP_IF_NM_Gateway_FCAB_XIX_HCP3_IONode  # _XIX_Infrastructure_Gateway_XIX_network_infrastructure_XIX_HCP5_P1_Gateway_XIX_Infrastructure_Info_El_XIX_network_infrastructure_XIX_HCP3_IONode_XIX_NM_Gateway_FCAB
    delegate Infrastructure_Info_El_XIX_network_infrastructure_XIX_HCP3_IONode.RP_IF_Gateway_Nachlauftyp_XIX_Infrastructure_Info_El_XIX_network_infrastructure_XIX_HCP3_IONode <-> outer port RP_IF_Gateway_Nachlauftyp_XIX_HCP3_IONode  # _XIX_Infrastructure_Gateway_XIX_network_infrastructure_XIX_HCP5_P1_Gateway_XIX_Infrastructure_Info_El_XIX_network_infrastructure_XIX_HCP3_IONode_XIX_Gateway_Nachlauftyp
    delegate VNSM3_1_XIX_WUSL_XIX_HCP3_IONode.RP_IF_NM_Gateway_FCIB_XIX_VNSM3_1_XIX_WUSL_XIX_HCP3_IONode <-> outer port RP_IF_NM_Gateway_FCIB_XIX_HCP3_IONode  # _XIX_Infrastructure_Gateway_XIX_network_infrastructure_XIX_HCP5_P1_Gateway_XIX_VNSM3_1_XIX_WUSL_XIX_HCP3_IONode_XIX_NM_Gateway_FCIB
    delegate VNSM3_1_XIX_WUSL_XIX_HCP3_IONode.RP_IF_NM_Gateway_FCAB_XIX_VNSM3_1_XIX_WUSL_XIX_HCP3_IONode <-> outer port RP_IF_NM_Gateway_FCAB_XIX_HCP3_IONode  # _XIX_Infrastructure_Gateway_XIX_network_infrastructure_XIX_HCP5_P1_Gateway_XIX_VNSM3_1_XIX_WUSL_XIX_HCP3_IONode_XIX_NM_Gateway_FCAB
    delegate WUM_Client3_XIX_WUM_XIX_HCP3_IONode.RP_IF_NM_Gateway_CBV_AWB_XIX_WUM_Client3_XIX_WUM_XIX_HCP3_IONode <-> outer port RP_IF_NM_Gateway_CBV_AWB_XIX_HCP3_IONode  # _XIX_Infrastructure_Gateway_XIX_network_infrastructure_XIX_HCP5_P1_Gateway_XIX_WUM_Client3_XIX_WUM_XIX_HCP3_IONode_XIX_NM_Gateway_CBV_AWB
    delegate WUM_Client3_XIX_WUM_XIX_HCP3_IONode.RP_IF_NM_Gateway_NM_State_XIX_WUM_Client3_XIX_WUM_XIX_HCP3_IONode <-> outer port RP_IF_NM_Gateway_NM_State_XIX_HCP3_IONode  # _XIX_Infrastructure_Gateway_XIX_network_infrastructure_XIX_HCP5_P1_Gateway_XIX_WUM_Client3_XIX_WUM_XIX_HCP3_IONode_XIX_NM_Gateway_NM_State
    delegate WUM_Client3_XIX_WUM_XIX_HCP3_IONode.RP_IF_NM_Gateway_SNI_10_XIX_WUM_Client3_XIX_WUM_XIX_HCP3_IONode <-> outer port RP_IF_NM_Gateway_SNI_10_XIX_HCP3_IONode  # _XIX_Infrastructure_Gateway_XIX_network_infrastructure_XIX_HCP5_P1_Gateway_XIX_WUM_Client3_XIX_WUM_XIX_HCP3_IONode_XIX_NM_Gateway_SNI_10
    delegate Infrastructure_Info_El_XIX_network_infrastructure_XIX_HCP3_IONode.RP_IF_NM_HUD_FCAB_XIX_Infrastructure_Info_El_XIX_network_infrastructure_XIX_HCP3_IONode <-> outer port RP_IF_NM_HUD_FCAB_XIX_HCP3_IONode  # _XIX_Infrastructure_HUD_XIX_network_infrastructure_XIX_AR_HUD_XIX_Infrastructure_Info_El_XIX_network_infrastructure_XIX_HCP3_IONode_XIX_NM_HUD_FCAB
    delegate Infrastructure_Info_El_XIX_network_infrastructure_XIX_HCP3_IONode.RP_IF_HUD_Nachlauftyp_XIX_Infrastructure_Info_El_XIX_network_infrastructure_XIX_HCP3_IONode <-> outer port RP_IF_HUD_Nachlauftyp_XIX_HCP3_IONode  # _XIX_Infrastructure_HUD_XIX_network_infrastructure_XIX_AR_HUD_XIX_Infrastructure_Info_El_XIX_network_infrastructure_XIX_HCP3_IONode_XIX_HUD_Nachlauftyp
    delegate VNSM3_1_XIX_WUSL_XIX_HCP3_IONode.RP_IF_NM_HUD_FCAB_XIX_VNSM3_1_XIX_WUSL_XIX_HCP3_IONode <-> outer port RP_IF_NM_HUD_FCAB_XIX_HCP3_IONode
    delegate VNSM3_1_XIX_WUSL_XIX_HCP3_IONode.RP_IF_NM_HUD_FCIB_XIX_VNSM3_1_XIX_WUSL_XIX_HCP3_IONode <-> outer port RP_IF_NM_HUD_FCIB_XIX_HCP3_IONode
    delegate WUM_Client3_XIX_WUM_XIX_HCP3_IONode.RP_IF_NM_HUD_CBV_AWB_XIX_WUM_Client3_XIX_WUM_XIX_HCP3_IONode <-> outer port RP_IF_NM_HUD_CBV_AWB_XIX_HCP3_IONode
    delegate WUM_Client3_XIX_WUM_XIX_HCP3_IONode.RP_IF_NM_HUD_NM_State_XIX_WUM_Client3_XIX_WUM_XIX_HCP3_IONode <-> outer port RP_IF_NM_HUD_NM_State_XIX_HCP3_IONode
    delegate WUM_Client3_XIX_WUM_XIX_HCP3_IONode.RP_IF_NM_HUD_SNI_10_XIX_WUM_Client3_XIX_WUM_XIX_HCP3_IONode <-> outer port RP_IF_NM_HUD_SNI_10_XIX_HCP3_IONode
    delegate Infrastructure_Info_El_XIX_network_infrastructure_XIX_HCP3_IONode.SP_IF_DS_Info_El_Lokalaktiv_XIX_Infrastructure_Info_El_XIX_network_infrastructure_XIX_HCP3_IONode <-> outer port SP_IF_DS_Info_El_Lokalaktiv_XIX_HCP3_IONode  # _XIX_Infrastructure_Info_El_XIX_network_infrastructure_XIX_HCP3_IONode_XIX_RSM_Generierung_XIX_NVEV_Basis_XIX_HCP5_P2_OBD_Safety_XIX_DS_Info_El_Lokalaktiv
    delegate Infrastructure_Info_El_XIX_network_infrastructure_XIX_HCP3_IONode.SP_IF_Info_El_Nachlauftyp_XIX_Infrastructure_Info_El_XIX_network_infrastructure_XIX_HCP3_IONode <-> outer port SP_IF_Info_El_Nachlauftyp_XIX_HCP3_IONode  # _XIX_Infrastructure_Info_El_XIX_network_infrastructure_XIX_HCP3_IONode_XIX_Infrastructure_Gateway_XIX_network_infrastructure_XIX_HCP5_P1_Gateway_XIX_Info_El_Nachlauftyp
    delegate Infrastructure_Info_El_XIX_network_infrastructure_XIX_HCP3_IONode.SP_IF_NM_Info_El_CBV_AWB_XIX_Infrastructure_Info_El_XIX_network_infrastructure_XIX_HCP3_IONode <-> outer port SP_IF_NM_Info_El_CBV_AWB_XIX_HCP3_IONode  # _XIX_Infrastructure_Info_El_XIX_network_infrastructure_XIX_HCP3_IONode_XIX_WUM_Client5_XIX_WUM_XIX_HCP5_P1_Gateway_XIX_NM_Info_El_CBV_AWB
    delegate Infrastructure_Info_El_XIX_network_infrastructure_XIX_HCP3_IONode.SP_IF_NM_Info_El_FCAB_XIX_Infrastructure_Info_El_XIX_network_infrastructure_XIX_HCP3_IONode <-> outer port SP_IF_NM_Info_El_FCAB_XIX_HCP3_IONode  # _XIX_Infrastructure_Info_El_XIX_network_infrastructure_XIX_HCP3_IONode_XIX_Infrastructure_HUD_XIX_network_infrastructure_XIX_AR_HUD_XIX_NM_Info_El_FCAB
    delegate Infrastructure_Info_El_XIX_network_infrastructure_XIX_HCP3_IONode.SP_IF_NM_Info_El_FCIB_XIX_Infrastructure_Info_El_XIX_network_infrastructure_XIX_HCP3_IONode <-> outer port SP_IF_NM_Info_El_FCIB_XIX_HCP3_IONode  # _XIX_Infrastructure_Info_El_XIX_network_infrastructure_XIX_HCP3_IONode_XIX_VNSM5_1_XIX_WUSL_XIX_HCP5_P1_Gateway_XIX_NM_Info_El_FCIB
    delegate Infrastructure_Info_El_XIX_network_infrastructure_XIX_HCP3_IONode.SP_IF_NM_Info_El_NM_State_XIX_Infrastructure_Info_El_XIX_network_infrastructure_XIX_HCP3_IONode <-> outer port SP_IF_NM_Info_El_NM_State_XIX_HCP3_IONode  # _XIX_Infrastructure_Info_El_XIX_network_infrastructure_XIX_HCP3_IONode_XIX_WUM_Client5_XIX_WUM_XIX_HCP5_P1_Gateway_XIX_NM_Info_El_NM_State
    delegate Infrastructure_Info_El_XIX_network_infrastructure_XIX_HCP3_IONode.SP_IF_NM_Info_El_SNI_10_XIX_Infrastructure_Info_El_XIX_network_infrastructure_XIX_HCP3_IONode <-> outer port SP_IF_NM_Info_El_SNI_10_XIX_HCP3_IONode  # _XIX_Infrastructure_Info_El_XIX_network_infrastructure_XIX_HCP3_IONode_XIX_WUM_Client5_XIX_WUM_XIX_HCP5_P1_Gateway_XIX_NM_Info_El_SNI_10
    delegate Infrastructure_Info_El_XIX_network_infrastructure_XIX_HCP3_IONode.SP_IF_TCPServer_IP_TS_DTO_{01..04}_Data_XIX_Infrastructure_Info_El_XIX_network_infrastructure_XIX_HCP3_IONode <-> outer port SP_IF_TCPServer_IP_TS_DTO_{01..04}_Data_XIX_HCP3_IONode  # _XIX_Infrastructure_Info_El_XIX_network_infrastructure_XIX_HCP3_IONode_XIX_Grundumfang_XIX_TestSysIP_XIX_TCPServer_IP_TS_DTO_{01..04}_Data
    delegate Infrastructure_Info_El_XIX_network_infrastructure_XIX_HCP3_IONode.RP_IF_NM_LSR_1_FCAB_XIX_Infrastructure_Info_El_XIX_network_infrastructure_XIX_HCP3_IONode <-> outer port RP_IF_NM_LSR_1_FCAB_XIX_HCP3_IONode  # _XIX_Infrastructure_LSR_1_XIX_network_infrastructure_XIX_LSR_XIX_Infrastructure_Info_El_XIX_network_infrastructure_XIX_HCP3_IONode_XIX_NM_LSR_1_FCAB
    delegate VNSM3_1_XIX_WUSL_XIX_HCP3_IONode.RP_IF_NM_LSR_1_FCAB_XIX_VNSM3_1_XIX_WUSL_XIX_HCP3_IONode <-> outer port RP_IF_NM_LSR_1_FCAB_XIX_HCP3_IONode
    delegate WUM_Client3_XIX_WUM_XIX_HCP3_IONode.RP_IF_NM_LSR_1_CBV_AWB_XIX_WUM_Client3_XIX_WUM_XIX_HCP3_IONode <-> outer port RP_IF_NM_LSR_1_CBV_AWB_XIX_HCP3_IONode
    delegate WUM_Client3_XIX_WUM_XIX_HCP3_IONode.RP_IF_NM_LSR_1_NM_State_XIX_WUM_Client3_XIX_WUM_XIX_HCP3_IONode <-> outer port RP_IF_NM_LSR_1_NM_State_XIX_HCP3_IONode
    delegate WUM_Client3_XIX_WUM_XIX_HCP3_IONode.RP_IF_NM_LSR_1_SNI_10_XIX_WUM_Client3_XIX_WUM_XIX_HCP3_IONode <-> outer port RP_IF_NM_LSR_1_SNI_10_XIX_HCP3_IONode
    delegate Infrastructure_Info_El_XIX_network_infrastructure_XIX_HCP3_IONode.RP_IF_PID_Nachlauftyp_XIX_Infrastructure_Info_El_XIX_network_infrastructure_XIX_HCP3_IONode <-> outer port RP_IF_PID_Nachlauftyp_XIX_HCP3_IONode  # _XIX_Infrastructure_PID_XIX_network_infrastructure_XIX_PI_Disp_XIX_Infrastructure_Info_El_XIX_network_infrastructure_XIX_HCP3_IONode_XIX_PID_Nachlauftyp
    delegate Infrastructure_Info_El_XIX_network_infrastructure_XIX_HCP3_IONode.RP_IF_NM_PID_FCAB_XIX_Infrastructure_Info_El_XIX_network_infrastructure_XIX_HCP3_IONode <-> outer port RP_IF_NM_PID_FCAB_XIX_HCP3_IONode  # _XIX_Infrastructure_PID_XIX_network_infrastructure_XIX_PI_Disp_XIX_Infrastructure_Info_El_XIX_network_infrastructure_XIX_HCP3_IONode_XIX_NM_PID_FCAB
    delegate VNSM3_1_XIX_WUSL_XIX_HCP3_IONode.RP_IF_NM_PID_FCAB_XIX_VNSM3_1_XIX_WUSL_XIX_HCP3_IONode <-> outer port RP_IF_NM_PID_FCAB_XIX_HCP3_IONode
    delegate VNSM3_1_XIX_WUSL_XIX_HCP3_IONode.RP_IF_NM_PID_FCIB_XIX_VNSM3_1_XIX_WUSL_XIX_HCP3_IONode <-> outer port RP_IF_NM_PID_FCIB_XIX_HCP3_IONode
    delegate WUM_Client3_XIX_WUM_XIX_HCP3_IONode.RP_IF_NM_PID_CBV_AWB_XIX_WUM_Client3_XIX_WUM_XIX_HCP3_IONode <-> outer port RP_IF_NM_PID_CBV_AWB_XIX_HCP3_IONode
    delegate WUM_Client3_XIX_WUM_XIX_HCP3_IONode.RP_IF_NM_PID_NM_State_XIX_WUM_Client3_XIX_WUM_XIX_HCP3_IONode <-> outer port RP_IF_NM_PID_NM_State_XIX_HCP3_IONode
    delegate WUM_Client3_XIX_WUM_XIX_HCP3_IONode.RP_IF_NM_PID_SNI_10_XIX_WUM_Client3_XIX_WUM_XIX_HCP3_IONode <-> outer port RP_IF_NM_PID_SNI_10_XIX_HCP3_IONode
    delegate Infrastructure_Info_El_XIX_network_infrastructure_XIX_HCP3_IONode.RP_IF_WLC1_Nachlauftyp_XIX_Infrastructure_Info_El_XIX_network_infrastructure_XIX_HCP3_IONode <-> outer port RP_IF_WLC1_Nachlauftyp_XIX_HCP3_IONode  # _XIX_Infrastructure_WLC1_XIX_network_infrastructure_XIX_WLC_01_XIX_Infrastructure_Info_El_XIX_network_infrastructure_XIX_HCP3_IONode_XIX_WLC1_Nachlauftyp
    delegate Infrastructure_Info_El_XIX_network_infrastructure_XIX_HCP3_IONode.RP_IF_NM_WLC1_FCAB_XIX_Infrastructure_Info_El_XIX_network_infrastructure_XIX_HCP3_IONode <-> outer port RP_IF_NM_WLC1_FCAB_XIX_HCP3_IONode  # _XIX_Infrastructure_WLC1_XIX_network_infrastructure_XIX_WLC_01_XIX_Infrastructure_Info_El_XIX_network_infrastructure_XIX_HCP3_IONode_XIX_NM_WLC1_FCAB
    delegate VNSM3_1_XIX_WUSL_XIX_HCP3_IONode.RP_IF_NM_WLC1_FCAB_XIX_VNSM3_1_XIX_WUSL_XIX_HCP3_IONode <-> outer port RP_IF_NM_WLC1_FCAB_XIX_HCP3_IONode
    delegate VNSM3_1_XIX_WUSL_XIX_HCP3_IONode.RP_IF_NM_WLC1_FCIB_XIX_VNSM3_1_XIX_WUSL_XIX_HCP3_IONode <-> outer port RP_IF_NM_WLC1_FCIB_XIX_HCP3_IONode
    delegate WUM_Client3_XIX_WUM_XIX_HCP3_IONode.RP_IF_NM_WLC1_CBV_AWB_XIX_WUM_Client3_XIX_WUM_XIX_HCP3_IONode <-> outer port RP_IF_NM_WLC1_CBV_AWB_XIX_HCP3_IONode
    delegate WUM_Client3_XIX_WUM_XIX_HCP3_IONode.RP_IF_NM_WLC1_NM_State_XIX_WUM_Client3_XIX_WUM_XIX_HCP3_IONode <-> outer port RP_IF_NM_WLC1_NM_State_XIX_HCP3_IONode
    delegate WUM_Client3_XIX_WUM_XIX_HCP3_IONode.RP_IF_NM_WLC1_SNI_10_XIX_WUM_Client3_XIX_WUM_XIX_HCP3_IONode <-> outer port RP_IF_NM_WLC1_SNI_10_XIX_HCP3_IONode
    delegate Infrastructure_Info_El_XIX_network_infrastructure_XIX_HCP3_IONode.RP_IF_NM_WLC2_FCAB_XIX_Infrastructure_Info_El_XIX_network_infrastructure_XIX_HCP3_IONode <-> outer port RP_IF_NM_WLC2_FCAB_XIX_HCP3_IONode  # _XIX_Infrastructure_WLC2_XIX_network_infrastructure_XIX_WLC_02_XIX_Infrastructure_Info_El_XIX_network_infrastructure_XIX_HCP3_IONode_XIX_NM_WLC2_FCAB
    delegate Infrastructure_Info_El_XIX_network_infrastructure_XIX_HCP3_IONode.RP_IF_WLC2_Nachlauftyp_XIX_Infrastructure_Info_El_XIX_network_infrastructure_XIX_HCP3_IONode <-> outer port RP_IF_WLC2_Nachlauftyp_XIX_HCP3_IONode  # _XIX_Infrastructure_WLC2_XIX_network_infrastructure_XIX_WLC_02_XIX_Infrastructure_Info_El_XIX_network_infrastructure_XIX_HCP3_IONode_XIX_WLC2_Nachlauftyp
    delegate VNSM3_1_XIX_WUSL_XIX_HCP3_IONode.RP_IF_NM_WLC2_FCAB_XIX_VNSM3_1_XIX_WUSL_XIX_HCP3_IONode <-> outer port RP_IF_NM_WLC2_FCAB_XIX_HCP3_IONode
    delegate VNSM3_1_XIX_WUSL_XIX_HCP3_IONode.RP_IF_NM_WLC2_FCIB_XIX_VNSM3_1_XIX_WUSL_XIX_HCP3_IONode <-> outer port RP_IF_NM_WLC2_FCIB_XIX_HCP3_IONode
    delegate WUM_Client3_XIX_WUM_XIX_HCP3_IONode.RP_IF_NM_WLC2_CBV_AWB_XIX_WUM_Client3_XIX_WUM_XIX_HCP3_IONode <-> outer port RP_IF_NM_WLC2_CBV_AWB_XIX_HCP3_IONode
    delegate WUM_Client3_XIX_WUM_XIX_HCP3_IONode.RP_IF_NM_WLC2_NM_State_XIX_WUM_Client3_XIX_WUM_XIX_HCP3_IONode <-> outer port RP_IF_NM_WLC2_NM_State_XIX_HCP3_IONode
    delegate WUM_Client3_XIX_WUM_XIX_HCP3_IONode.RP_IF_NM_WLC2_SNI_10_XIX_WUM_Client3_XIX_WUM_XIX_HCP3_IONode <-> outer port RP_IF_NM_WLC2_SNI_10_XIX_HCP3_IONode
    delegate Tracing_HCP3_IONode_XIX_CockpitInfotainment_Systemfunktionen_XIX_HCP3_IONode.RP_IF_LSR_CL30_Undervoltage_Error_XIX_Tracing_HCP3_IONode_XIX_CockpitInfotainment_Systemfunktionen_XIX_HCP3_IONode <-> outer port RP_IF_LSR_CL30_Undervoltage_Error_XIX_HCP3_IONode  # _XIX_LSR_Common_XIX_UserInterface_XIX_BKE_XIX_Tracing_HCP3_IONode_XIX_CockpitInfotainment_Systemfunktionen_XIX_HCP3_IONode_XIX_LSR_CL30_Undervoltage_Error
    delegate Tracing_HCP3_IONode_XIX_CockpitInfotainment_Systemfunktionen_XIX_HCP3_IONode.RP_IF_LSR_dimming_PWM_XIX_Tracing_HCP3_IONode_XIX_CockpitInfotainment_Systemfunktionen_XIX_HCP3_IONode <-> outer port RP_IF_LSR_dimming_PWM_XIX_HCP3_IONode  # _XIX_LSR_Common_XIX_UserInterface_XIX_BKE_XIX_Tracing_HCP3_IONode_XIX_CockpitInfotainment_Systemfunktionen_XIX_HCP3_IONode_XIX_LSR_dimming_PWM
    delegate Tracing_HCP3_IONode_XIX_CockpitInfotainment_Systemfunktionen_XIX_HCP3_IONode.RP_IF_LSR_CL30_Overvolt_Error_XIX_Tracing_HCP3_IONode_XIX_CockpitInfotainment_Systemfunktionen_XIX_HCP3_IONode <-> outer port RP_IF_LSR_CL30_Overvolt_Error_XIX_HCP3_IONode  # _XIX_LSR_Common_XIX_UserInterface_XIX_BKE_XIX_Tracing_HCP3_IONode_XIX_CockpitInfotainment_Systemfunktionen_XIX_HCP3_IONode_XIX_LSR_CL30_Overvolt_Error
    delegate Tracing_HCP3_IONode_XIX_CockpitInfotainment_Systemfunktionen_XIX_HCP3_IONode.RP_IF_LSR_SystemMode_XIX_Tracing_HCP3_IONode_XIX_CockpitInfotainment_Systemfunktionen_XIX_HCP3_IONode <-> outer port RP_IF_LSR_SystemMode_XIX_HCP3_IONode  # _XIX_LSR_Common_XIX_UserInterface_XIX_BKE_XIX_Tracing_HCP3_IONode_XIX_CockpitInfotainment_Systemfunktionen_XIX_HCP3_IONode_XIX_LSR_SystemMode
    delegate Tracing_HCP3_IONode_XIX_CockpitInfotainment_Systemfunktionen_XIX_HCP3_IONode.RP_IF_LSR_dimming_post_carriage_XIX_Tracing_HCP3_IONode_XIX_CockpitInfotainment_Systemfunktionen_XIX_HCP3_IONode <-> outer port RP_IF_LSR_dimming_post_carriage_XIX_HCP3_IONode  # _XIX_LSR_Common_XIX_UserInterface_XIX_BKE_XIX_Tracing_HCP3_IONode_XIX_CockpitInfotainment_Systemfunktionen_XIX_HCP3_IONode_XIX_LSR_dimming_post_carriage
    delegate VehicleComm_HCP3_IONode_XIX_CockpitInfotainment_Systemfunktionen_XIX_HCP3_IONode.RP_IF_LSR_SW_inconsistent_TF_XIX_VehicleComm_HCP3_IONode_XIX_CockpitInfotainment_Systemfunktionen_XIX_HCP3_IONode <-> outer port RP_IF_LSR_SW_inconsistent_TF_XIX_HCP3_IONode  # _XIX_LSR_Common_XIX_UserInterface_XIX_BKE_XIX_VehicleComm_HCP3_IONode_XIX_CockpitInfotainment_Systemfunktionen_XIX_HCP3_IONode_XIX_LSR_SW_inconsistent_TF
    delegate VehicleComm_HCP3_IONode_XIX_CockpitInfotainment_Systemfunktionen_XIX_HCP3_IONode.RP_IF_LSR_EEPROM_Error_TF_XIX_VehicleComm_HCP3_IONode_XIX_CockpitInfotainment_Systemfunktionen_XIX_HCP3_IONode <-> outer port RP_IF_LSR_EEPROM_Error_TF_XIX_HCP3_IONode  # _XIX_LSR_Common_XIX_UserInterface_XIX_BKE_XIX_VehicleComm_HCP3_IONode_XIX_CockpitInfotainment_Systemfunktionen_XIX_HCP3_IONode_XIX_LSR_EEPROM_Error_TF
    delegate VehicleComm_HCP3_IONode_XIX_CockpitInfotainment_Systemfunktionen_XIX_HCP3_IONode.RP_IF_LSR_SW_inconsistent_TNCTOC_XIX_VehicleComm_HCP3_IONode_XIX_CockpitInfotainment_Systemfunktionen_XIX_HCP3_IONode <-> outer port RP_IF_LSR_SW_inconsistent_TNCTOC_XIX_HCP3_IONode  # _XIX_LSR_Common_XIX_UserInterface_XIX_BKE_XIX_VehicleComm_HCP3_IONode_XIX_CockpitInfotainment_Systemfunktionen_XIX_HCP3_IONode_XIX_LSR_SW_inconsistent_TNCTOC
    delegate VehicleComm_HCP3_IONode_XIX_CockpitInfotainment_Systemfunktionen_XIX_HCP3_IONode.RP_IF_LSR_EEPROM_Error_TNCTOC_XIX_VehicleComm_HCP3_IONode_XIX_CockpitInfotainment_Systemfunktionen_XIX_HCP3_IONode <-> outer port RP_IF_LSR_EEPROM_Error_TNCTOC_XIX_HCP3_IONode  # _XIX_LSR_Common_XIX_UserInterface_XIX_BKE_XIX_VehicleComm_HCP3_IONode_XIX_CockpitInfotainment_Systemfunktionen_XIX_HCP3_IONode_XIX_LSR_EEPROM_Error_TNCTOC
    delegate Tracing_HCP3_IONode_XIX_CockpitInfotainment_Systemfunktionen_XIX_HCP3_IONode.RP_IF_LSR_VW_SL_Spare_Part_Nr_MittelNr_XIX_Tracing_HCP3_IONode_XIX_CockpitInfotainment_Systemfunktionen_XIX_HCP3_IONode <-> outer port RP_IF_LSR_VW_SL_Spare_Part_Nr_MittelNr_XIX_HCP3_IONode  # _XIX_LSR_ECU_Info_XIX_UserInterface_XIX_LSR_XIX_Tracing_HCP3_IONode_XIX_CockpitInfotainment_Systemfunktionen_XIX_HCP3_IONode_XIX_LSR_VW_SL_Spare_Part_Nr_MittelNr
    delegate Tracing_HCP3_IONode_XIX_CockpitInfotainment_Systemfunktionen_XIX_HCP3_IONode.RP_IF_LSR_VW_SL_Spare_Part_Nr_TMA_XIX_Tracing_HCP3_IONode_XIX_CockpitInfotainment_Systemfunktionen_XIX_HCP3_IONode <-> outer port RP_IF_LSR_VW_SL_Spare_Part_Nr_TMA_XIX_HCP3_IONode  # _XIX_LSR_ECU_Info_XIX_UserInterface_XIX_LSR_XIX_Tracing_HCP3_IONode_XIX_CockpitInfotainment_Systemfunktionen_XIX_HCP3_IONode_XIX_LSR_VW_SL_Spare_Part_Nr_TMA
    delegate Tracing_HCP3_IONode_XIX_CockpitInfotainment_Systemfunktionen_XIX_HCP3_IONode.RP_IF_LSR_VW_SL_Spare_Part_Nr_Index_XIX_Tracing_HCP3_IONode_XIX_CockpitInfotainment_Systemfunktionen_XIX_HCP3_IONode <-> outer port RP_IF_LSR_VW_SL_Spare_Part_Nr_Index_XIX_HCP3_IONode  # _XIX_LSR_ECU_Info_XIX_UserInterface_XIX_LSR_XIX_Tracing_HCP3_IONode_XIX_CockpitInfotainment_Systemfunktionen_XIX_HCP3_IONode_XIX_LSR_VW_SL_Spare_Part_Nr_Index
    delegate Tracing_HCP3_IONode_XIX_CockpitInfotainment_Systemfunktionen_XIX_HCP3_IONode.RP_IF_LSR_VW_SL_Spare_Part_Nr_EndNr_XIX_Tracing_HCP3_IONode_XIX_CockpitInfotainment_Systemfunktionen_XIX_HCP3_IONode <-> outer port RP_IF_LSR_VW_SL_Spare_Part_Nr_EndNr_XIX_HCP3_IONode  # _XIX_LSR_ECU_Info_XIX_UserInterface_XIX_LSR_XIX_Tracing_HCP3_IONode_XIX_CockpitInfotainment_Systemfunktionen_XIX_HCP3_IONode_XIX_LSR_VW_SL_Spare_Part_Nr_EndNr
    delegate Tracing_HCP3_IONode_XIX_CockpitInfotainment_Systemfunktionen_XIX_HCP3_IONode.RP_IF_LSR_VW_SL_HW_Version_Nr_XIX_Tracing_HCP3_IONode_XIX_CockpitInfotainment_Systemfunktionen_XIX_HCP3_IONode <-> outer port RP_IF_LSR_VW_SL_HW_Version_Nr_XIX_HCP3_IONode  # _XIX_LSR_ECU_Info_XIX_UserInterface_XIX_LSR_XIX_Tracing_HCP3_IONode_XIX_CockpitInfotainment_Systemfunktionen_XIX_HCP3_IONode_XIX_LSR_VW_SL_HW_Version_Nr
    delegate Tracing_HCP3_IONode_XIX_CockpitInfotainment_Systemfunktionen_XIX_HCP3_IONode.RP_IF_LSR_VW_SL_App_SW_Version_Nr_XIX_Tracing_HCP3_IONode_XIX_CockpitInfotainment_Systemfunktionen_XIX_HCP3_IONode <-> outer port RP_IF_LSR_VW_SL_App_SW_Version_Nr_XIX_HCP3_IONode  # _XIX_LSR_ECU_Info_XIX_UserInterface_XIX_LSR_XIX_Tracing_HCP3_IONode_XIX_CockpitInfotainment_Systemfunktionen_XIX_HCP3_IONode_XIX_LSR_VW_SL_App_SW_Version_Nr
    delegate VehicleComm_HCP3_IONode_XIX_CockpitInfotainment_Systemfunktionen_XIX_HCP3_IONode.RP_IF_MFL_Marke_XIX_VehicleComm_HCP3_IONode_XIX_CockpitInfotainment_Systemfunktionen_XIX_HCP3_IONode <-> outer port RP_IF_MFL_Marke_XIX_HCP3_IONode  # _XIX_MFLBedienung_XIX_Bedienung_XIX_MFL_XIX_VehicleComm_HCP3_IONode_XIX_CockpitInfotainment_Systemfunktionen_XIX_HCP3_IONode_XIX_MFL_Marke
    delegate VehicleComm_HCP3_IONode_XIX_CockpitInfotainment_Systemfunktionen_XIX_HCP3_IONode.RP_IF_MFL_Variante_XIX_VehicleComm_HCP3_IONode_XIX_CockpitInfotainment_Systemfunktionen_XIX_HCP3_IONode <-> outer port RP_IF_MFL_Variante_XIX_HCP3_IONode  # _XIX_MFLBedienung_XIX_Bedienung_XIX_MFL_XIX_VehicleComm_HCP3_IONode_XIX_CockpitInfotainment_Systemfunktionen_XIX_HCP3_IONode_XIX_MFL_Variante
    delegate VehicleComm_HCP3_IONode_XIX_CockpitInfotainment_Systemfunktionen_XIX_HCP3_IONode.RP_IF_MFL_Eventcode_2_XIX_VehicleComm_HCP3_IONode_XIX_CockpitInfotainment_Systemfunktionen_XIX_HCP3_IONode <-> outer port RP_IF_MFL_Eventcode_2_XIX_HCP3_IONode  # _XIX_MFLBedienung_XIX_Bedienung_XIX_MFL_XIX_VehicleComm_HCP3_IONode_XIX_CockpitInfotainment_Systemfunktionen_XIX_HCP3_IONode_XIX_MFL_Eventcode_2
    delegate VehicleComm_HCP3_IONode_XIX_CockpitInfotainment_Systemfunktionen_XIX_HCP3_IONode.RP_IF_MFL_Paddle_Verbau_XIX_VehicleComm_HCP3_IONode_XIX_CockpitInfotainment_Systemfunktionen_XIX_HCP3_IONode <-> outer port RP_IF_MFL_Paddle_Verbau_XIX_HCP3_IONode  # _XIX_MFLBedienung_XIX_Bedienung_XIX_MFL_XIX_VehicleComm_HCP3_IONode_XIX_CockpitInfotainment_Systemfunktionen_XIX_HCP3_IONode_XIX_MFL_Paddle_Verbau
    delegate VehicleComm_HCP3_IONode_XIX_CockpitInfotainment_Systemfunktionen_XIX_HCP3_IONode.RP_IF_MFL_Tastencode_2_XIX_VehicleComm_HCP3_IONode_XIX_CockpitInfotainment_Systemfunktionen_XIX_HCP3_IONode <-> outer port RP_IF_MFL_Tastencode_2_XIX_HCP3_IONode  # _XIX_MFLBedienung_XIX_Bedienung_XIX_MFL_XIX_VehicleComm_HCP3_IONode_XIX_CockpitInfotainment_Systemfunktionen_XIX_HCP3_IONode_XIX_MFL_Tastencode_2
    delegate VehicleComm_HCP3_IONode_XIX_CockpitInfotainment_Systemfunktionen_XIX_HCP3_IONode.RP_IF_MFL_Eventcode_1_XIX_VehicleComm_HCP3_IONode_XIX_CockpitInfotainment_Systemfunktionen_XIX_HCP3_IONode <-> outer port RP_IF_MFL_Eventcode_1_XIX_HCP3_IONode  # _XIX_MFLBedienung_XIX_Bedienung_XIX_MFL_XIX_VehicleComm_HCP3_IONode_XIX_CockpitInfotainment_Systemfunktionen_XIX_HCP3_IONode_XIX_MFL_Eventcode_1
    delegate VehicleComm_HCP3_IONode_XIX_CockpitInfotainment_Systemfunktionen_XIX_HCP3_IONode.RP_IF_MFL_Tastencode_1_XIX_VehicleComm_HCP3_IONode_XIX_CockpitInfotainment_Systemfunktionen_XIX_HCP3_IONode <-> outer port RP_IF_MFL_Tastencode_1_XIX_HCP3_IONode  # _XIX_MFLBedienung_XIX_Bedienung_XIX_MFL_XIX_VehicleComm_HCP3_IONode_XIX_CockpitInfotainment_Systemfunktionen_XIX_HCP3_IONode_XIX_MFL_Tastencode_1
    delegate diagnosis_infrastructure_Info_El_XIX_diagnosis_infrastructure_XIX_HCP3_IONode.RP_IF_MM_PropulsionSystemActive_XIX_diagnosis_infrastructure_Info_El_XIX_diagnosis_infrastructure_XIX_HCP3_IONode <-> outer port RP_IF_MM_PropulsionSystemActive_XIX_HCP3_IONode  # _XIX_MIL_Master_XIX_OBD_XIX_HCP1_XIX_diagnosis_infrastructure_Info_El_XIX_diagnosis_infrastructure_XIX_HCP3_IONode_XIX_MM_PropulsionSystemActive
    delegate diagnosis_infrastructure_Info_El_XIX_diagnosis_infrastructure_XIX_HCP3_IONode.RP_IF_OBD_Warm_Up_Cycle_XIX_diagnosis_infrastructure_Info_El_XIX_diagnosis_infrastructure_XIX_HCP3_IONode <-> outer port RP_IF_OBD_Warm_Up_Cycle_XIX_HCP3_IONode  # _XIX_MIL_Master_XIX_OBD_XIX_HCP1_XIX_diagnosis_infrastructure_Info_El_XIX_diagnosis_infrastructure_XIX_HCP3_IONode_XIX_OBD_Warm_Up_Cycle
    delegate diagnosis_infrastructure_Info_El_XIX_diagnosis_infrastructure_XIX_HCP3_IONode.RP_IF_OBD_Driving_Cycle_XIX_diagnosis_infrastructure_Info_El_XIX_diagnosis_infrastructure_XIX_HCP3_IONode <-> outer port RP_IF_OBD_Driving_Cycle_XIX_HCP3_IONode  # _XIX_MIL_Master_XIX_OBD_XIX_HCP1_XIX_diagnosis_infrastructure_Info_El_XIX_diagnosis_infrastructure_XIX_HCP3_IONode_XIX_OBD_Driving_Cycle
    delegate Infrastructure_Info_El_XIX_network_infrastructure_XIX_HCP3_IONode.RP_IF_NVEM_Abschaltstufe_XIX_Infrastructure_Info_El_XIX_network_infrastructure_XIX_HCP3_IONode <-> outer port RP_IF_NVEM_Abschaltstufe_XIX_HCP3_IONode  # _XIX_NiedervoltEnergiemanagement_XIX_NVEV_Basis_XIX_HCP5_P2_OBD_Safety_XIX_Infrastructure_Info_El_XIX_network_infrastructure_XIX_HCP3_IONode_XIX_NVEM_Abschaltstufe
    delegate PowerManagement_HCP3_IONode_XIX_CockpitInfotainment_Systemfunktionen_XIX_HCP3_IONode.RP_IF_NVEM_Abschaltstufe_XIX_PowerManagement_HCP3_IONode_XIX_CockpitInfotainment_Systemfunktionen_XIX_HCP3_IONode <-> outer port RP_IF_NVEM_Abschaltstufe_XIX_HCP3_IONode  # _XIX_NiedervoltEnergiemanagement_XIX_NVEV_Basis_XIX_HCP5_P2_OBD_Safety_XIX_PowerManagement_HCP3_IONode_XIX_CockpitInfotainment_Systemfunktionen_XIX_HCP3_IONode_XIX_NVEM_Abschaltstufe
    delegate VehicleComm_HCP3_IONode_XIX_CockpitInfotainment_Systemfunktionen_XIX_HCP3_IONode.RP_IF_NVEM_Abschaltstufe_XIX_VehicleComm_HCP3_IONode_XIX_CockpitInfotainment_Systemfunktionen_XIX_HCP3_IONode <-> outer port RP_IF_NVEM_Abschaltstufe_XIX_HCP3_IONode  # _XIX_NiedervoltEnergiemanagement_XIX_NVEV_Basis_XIX_HCP5_P2_OBD_Safety_XIX_VehicleComm_HCP3_IONode_XIX_CockpitInfotainment_Systemfunktionen_XIX_HCP3_IONode_XIX_NVEM_Abschaltstufe
    delegate WUM_Client3_XIX_WUM_XIX_HCP3_IONode.RP_IF_NVEM_Abschaltstufe_XIX_WUM_Client3_XIX_WUM_XIX_HCP3_IONode <-> outer port RP_IF_NVEM_Abschaltstufe_XIX_HCP3_IONode  # _XIX_NiedervoltEnergiemanagement_XIX_NVEV_Basis_XIX_HCP5_P2_OBD_Safety_XIX_WUM_Client3_XIX_WUM_XIX_HCP3_IONode_XIX_NVEM_Abschaltstufe
    delegate OTA_Infrastructure_HCP3_XIX_OTAMC_XIX_HCP3_IONode.RP_IF_SG_ORU_Control_A_01_XIX_OTA_Infrastructure_HCP3_XIX_OTAMC_XIX_HCP3_IONode <-> outer port RP_IF_SG_ORU_Control_A_01_XIX_HCP3_IONode
    delegate OTA_Infrastructure_Info_El_XIX_RP_XIX_HCP3_IONode.RP_IF_SG_ORU_Control_A_01_XIX_OTA_Infrastructure_Info_El_XIX_RP_XIX_HCP3_IONode <-> outer port RP_IF_SG_ORU_Control_A_01_XIX_HCP3_IONode  # DCon_XIX_ORU_Control_A_XIX_ORU6_XIX_HCP5_P2_OBD_Safety_XIX_OTA_Infrastructure_Info_El_XIX_RP_XIX_HCP3_IONode_XIX_SG_ORU_Control_A_01
    delegate OTA_Infrastructure_HCP3_XIX_OTAMC_XIX_HCP3_IONode.RP_IF_SG_ORU_Control_D_01_XIX_OTA_Infrastructure_HCP3_XIX_OTAMC_XIX_HCP3_IONode <-> outer port RP_IF_SG_ORU_Control_D_01_XIX_HCP3_IONode
    delegate OTA_Infrastructure_Info_El_XIX_RP_XIX_HCP3_IONode.RP_IF_SG_ORU_Control_D_01_XIX_OTA_Infrastructure_Info_El_XIX_RP_XIX_HCP3_IONode <-> outer port RP_IF_SG_ORU_Control_D_01_XIX_HCP3_IONode
    delegate OTA_Infrastructure_HCP3_XIX_OTAMC_XIX_HCP3_IONode.RP_IF_SG_OTAMC_D_01_XIX_OTA_Infrastructure_HCP3_XIX_OTAMC_XIX_HCP3_IONode <-> outer port RP_IF_SG_OTAMC_D_01_XIX_HCP3_IONode  # DCon_XIX_OTAMC_VehicleStateManager_Safety_D_XIX_OTAMC_XIX_HCP1_XIX_OTA_Infrastructure_HCP3_XIX_OTAMC_XIX_HCP3_IONode_XIX_SG_OTAMC_D_01
    delegate OTA_Infrastructure_Info_El_XIX_RP_XIX_HCP3_IONode.RP_IF_SG_OTAMC_D_01_XIX_OTA_Infrastructure_Info_El_XIX_RP_XIX_HCP3_IONode <-> outer port RP_IF_SG_OTAMC_D_01_XIX_HCP3_IONode  # DCon_XIX_OTAMC_VehicleStateManager_Safety_D_XIX_OTAMC_XIX_HCP1_XIX_OTA_Infrastructure_Info_El_XIX_RP_XIX_HCP3_IONode_XIX_SG_OTAMC_D_01
    delegate ORU_Infrastructure_Info_El_XIX_ORU6_XIX_HCP3_IONode.RP_IF_ORU_Status_XIX_ORU_Infrastructure_Info_El_XIX_ORU6_XIX_HCP3_IONode <-> outer port RP_IF_ORU_Status_XIX_HCP3_IONode  # _XIX_OTA_MasterCapability_SCILib_XIX_OTAMC_XIX_HCP5_P4_E3SWPAC_XIX_ORU_Infrastructure_Info_El_XIX_ORU6_XIX_HCP3_IONode_XIX_ORU_Status
    delegate OTA_Infrastructure_HCP3_XIX_OTAMC_XIX_HCP3_IONode.RP_IF_ORU_Status_XIX_OTA_Infrastructure_HCP3_XIX_OTAMC_XIX_HCP3_IONode <-> outer port RP_IF_ORU_Status_XIX_HCP3_IONode  # _XIX_OTA_MasterCapability_SCILib_XIX_OTAMC_XIX_HCP5_P4_E3SWPAC_XIX_OTA_Infrastructure_HCP3_XIX_OTAMC_XIX_HCP3_IONode_XIX_ORU_Status
    delegate PowerManagement_HCP3_IONode_XIX_CockpitInfotainment_Systemfunktionen_XIX_HCP3_IONode.RP_IF_PID_State_XIX_PowerManagement_HCP3_IONode_XIX_CockpitInfotainment_Systemfunktionen_XIX_HCP3_IONode <-> outer port RP_IF_PID_State_XIX_HCP3_IONode  # _XIX_PI_Common_XIX_UserInterface_XIX_PI_Disp_XIX_PowerManagement_HCP3_IONode_XIX_CockpitInfotainment_Systemfunktionen_XIX_HCP3_IONode_XIX_PID_State
    delegate PowerManagement_HCP3_IONode_XIX_CockpitInfotainment_Systemfunktionen_XIX_HCP3_IONode.RP_IF_PID_LVDS_State_XIX_PowerManagement_HCP3_IONode_XIX_CockpitInfotainment_Systemfunktionen_XIX_HCP3_IONode <-> outer port RP_IF_PID_LVDS_State_XIX_HCP3_IONode  # _XIX_PI_Common_XIX_UserInterface_XIX_PI_Disp_XIX_PowerManagement_HCP3_IONode_XIX_CockpitInfotainment_Systemfunktionen_XIX_HCP3_IONode_XIX_PID_LVDS_State
    delegate Tracing_HCP3_IONode_XIX_CockpitInfotainment_Systemfunktionen_XIX_HCP3_IONode.RP_IF_PID_Slider_Errorstate_XIX_Tracing_HCP3_IONode_XIX_CockpitInfotainment_Systemfunktionen_XIX_HCP3_IONode <-> outer port RP_IF_PID_Slider_Errorstate_XIX_HCP3_IONode  # _XIX_PI_Common_XIX_UserInterface_XIX_PI_Disp_XIX_Tracing_HCP3_IONode_XIX_CockpitInfotainment_Systemfunktionen_XIX_HCP3_IONode_XIX_PID_Slider_Errorstate
    delegate Tracing_HCP3_IONode_XIX_CockpitInfotainment_Systemfunktionen_XIX_HCP3_IONode.RP_IF_PID_TempSensor_XIX_Tracing_HCP3_IONode_XIX_CockpitInfotainment_Systemfunktionen_XIX_HCP3_IONode <-> outer port RP_IF_PID_TempSensor_XIX_HCP3_IONode  # _XIX_PI_Common_XIX_UserInterface_XIX_PI_Disp_XIX_Tracing_HCP3_IONode_XIX_CockpitInfotainment_Systemfunktionen_XIX_HCP3_IONode_XIX_PID_TempSensor
    delegate Tracing_HCP3_IONode_XIX_CockpitInfotainment_Systemfunktionen_XIX_HCP3_IONode.RP_IF_PID_PCB_TempSensor_XIX_Tracing_HCP3_IONode_XIX_CockpitInfotainment_Systemfunktionen_XIX_HCP3_IONode <-> outer port RP_IF_PID_PCB_TempSensor_XIX_HCP3_IONode  # _XIX_PI_Common_XIX_UserInterface_XIX_PI_Disp_XIX_Tracing_HCP3_IONode_XIX_CockpitInfotainment_Systemfunktionen_XIX_HCP3_IONode_XIX_PID_PCB_TempSensor
    delegate Tracing_HCP3_IONode_XIX_CockpitInfotainment_Systemfunktionen_XIX_HCP3_IONode.RP_IF_PID_Backlight_ShortCircuit_XIX_Tracing_HCP3_IONode_XIX_CockpitInfotainment_Systemfunktionen_XIX_HCP3_IONode <-> outer port RP_IF_PID_Backlight_ShortCircuit_XIX_HCP3_IONode  # _XIX_PI_Common_XIX_UserInterface_XIX_PI_Disp_XIX_Tracing_HCP3_IONode_XIX_CockpitInfotainment_Systemfunktionen_XIX_HCP3_IONode_XIX_PID_Backlight_ShortCircuit
    delegate Tracing_HCP3_IONode_XIX_CockpitInfotainment_Systemfunktionen_XIX_HCP3_IONode.RP_IF_PID_TempSensorMax_XIX_Tracing_HCP3_IONode_XIX_CockpitInfotainment_Systemfunktionen_XIX_HCP3_IONode <-> outer port RP_IF_PID_TempSensorMax_XIX_HCP3_IONode  # _XIX_PI_Common_XIX_UserInterface_XIX_PI_Disp_XIX_Tracing_HCP3_IONode_XIX_CockpitInfotainment_Systemfunktionen_XIX_HCP3_IONode_XIX_PID_TempSensorMax
    delegate Tracing_HCP3_IONode_XIX_CockpitInfotainment_Systemfunktionen_XIX_HCP3_IONode.RP_IF_PID_OperatingTime_hr_XIX_Tracing_HCP3_IONode_XIX_CockpitInfotainment_Systemfunktionen_XIX_HCP3_IONode <-> outer port RP_IF_PID_OperatingTime_hr_XIX_HCP3_IONode  # _XIX_PI_Common_XIX_UserInterface_XIX_PI_Disp_XIX_Tracing_HCP3_IONode_XIX_CockpitInfotainment_Systemfunktionen_XIX_HCP3_IONode_XIX_PID_OperatingTime_hr
    delegate Tracing_HCP3_IONode_XIX_CockpitInfotainment_Systemfunktionen_XIX_HCP3_IONode.RP_IF_PID_CL30_Overvoltage_Error_XIX_Tracing_HCP3_IONode_XIX_CockpitInfotainment_Systemfunktionen_XIX_HCP3_IONode <-> outer port RP_IF_PID_CL30_Overvoltage_Error_XIX_HCP3_IONode  # _XIX_PI_Common_XIX_UserInterface_XIX_PI_Disp_XIX_Tracing_HCP3_IONode_XIX_CockpitInfotainment_Systemfunktionen_XIX_HCP3_IONode_XIX_PID_CL30_Overvoltage_Error
    delegate Tracing_HCP3_IONode_XIX_CockpitInfotainment_Systemfunktionen_XIX_HCP3_IONode.RP_IF_PID_Temp_Error_XIX_Tracing_HCP3_IONode_XIX_CockpitInfotainment_Systemfunktionen_XIX_HCP3_IONode <-> outer port RP_IF_PID_Temp_Error_XIX_HCP3_IONode  # _XIX_PI_Common_XIX_UserInterface_XIX_PI_Disp_XIX_Tracing_HCP3_IONode_XIX_CockpitInfotainment_Systemfunktionen_XIX_HCP3_IONode_XIX_PID_Temp_Error
    delegate Tracing_HCP3_IONode_XIX_CockpitInfotainment_Systemfunktionen_XIX_HCP3_IONode.RP_IF_PID_LVDS_Errorstate_XIX_Tracing_HCP3_IONode_XIX_CockpitInfotainment_Systemfunktionen_XIX_HCP3_IONode <-> outer port RP_IF_PID_LVDS_Errorstate_XIX_HCP3_IONode  # _XIX_PI_Common_XIX_UserInterface_XIX_PI_Disp_XIX_Tracing_HCP3_IONode_XIX_CockpitInfotainment_Systemfunktionen_XIX_HCP3_IONode_XIX_PID_LVDS_Errorstate
    delegate Tracing_HCP3_IONode_XIX_CockpitInfotainment_Systemfunktionen_XIX_HCP3_IONode.RP_IF_PID_Touchstate_XIX_Tracing_HCP3_IONode_XIX_CockpitInfotainment_Systemfunktionen_XIX_HCP3_IONode <-> outer port RP_IF_PID_Touchstate_XIX_HCP3_IONode  # _XIX_PI_Common_XIX_UserInterface_XIX_PI_Disp_XIX_Tracing_HCP3_IONode_XIX_CockpitInfotainment_Systemfunktionen_XIX_HCP3_IONode_XIX_PID_Touchstate
    delegate Tracing_HCP3_IONode_XIX_CockpitInfotainment_Systemfunktionen_XIX_HCP3_IONode.RP_IF_PID_SystemMode_XIX_Tracing_HCP3_IONode_XIX_CockpitInfotainment_Systemfunktionen_XIX_HCP3_IONode <-> outer port RP_IF_PID_SystemMode_XIX_HCP3_IONode  # _XIX_PI_Common_XIX_UserInterface_XIX_PI_Disp_XIX_Tracing_HCP3_IONode_XIX_CockpitInfotainment_Systemfunktionen_XIX_HCP3_IONode_XIX_PID_SystemMode
    delegate Tracing_HCP3_IONode_XIX_CockpitInfotainment_Systemfunktionen_XIX_HCP3_IONode.RP_IF_PID_Proximity_Errorstate_XIX_Tracing_HCP3_IONode_XIX_CockpitInfotainment_Systemfunktionen_XIX_HCP3_IONode <-> outer port RP_IF_PID_Proximity_Errorstate_XIX_HCP3_IONode  # _XIX_PI_Common_XIX_UserInterface_XIX_PI_Disp_XIX_Tracing_HCP3_IONode_XIX_CockpitInfotainment_Systemfunktionen_XIX_HCP3_IONode_XIX_PID_Proximity_Errorstate
    delegate Tracing_HCP3_IONode_XIX_CockpitInfotainment_Systemfunktionen_XIX_HCP3_IONode.RP_IF_PID_DispDerating_XIX_Tracing_HCP3_IONode_XIX_CockpitInfotainment_Systemfunktionen_XIX_HCP3_IONode <-> outer port RP_IF_PID_DispDerating_XIX_HCP3_IONode  # _XIX_PI_Common_XIX_UserInterface_XIX_PI_Disp_XIX_Tracing_HCP3_IONode_XIX_CockpitInfotainment_Systemfunktionen_XIX_HCP3_IONode_XIX_PID_DispDerating
    delegate Tracing_HCP3_IONode_XIX_CockpitInfotainment_Systemfunktionen_XIX_HCP3_IONode.RP_IF_PID_CL_30F_XIX_Tracing_HCP3_IONode_XIX_CockpitInfotainment_Systemfunktionen_XIX_HCP3_IONode <-> outer port RP_IF_PID_CL_30F_XIX_HCP3_IONode  # _XIX_PI_Common_XIX_UserInterface_XIX_PI_Disp_XIX_Tracing_HCP3_IONode_XIX_CockpitInfotainment_Systemfunktionen_XIX_HCP3_IONode_XIX_PID_CL_30F
    delegate Tracing_HCP3_IONode_XIX_CockpitInfotainment_Systemfunktionen_XIX_HCP3_IONode.RP_IF_PID_EEPROM_Error_XIX_Tracing_HCP3_IONode_XIX_CockpitInfotainment_Systemfunktionen_XIX_HCP3_IONode <-> outer port RP_IF_PID_EEPROM_Error_XIX_HCP3_IONode  # _XIX_PI_Common_XIX_UserInterface_XIX_PI_Disp_XIX_Tracing_HCP3_IONode_XIX_CockpitInfotainment_Systemfunktionen_XIX_HCP3_IONode_XIX_PID_EEPROM_Error
    delegate Tracing_HCP3_IONode_XIX_CockpitInfotainment_Systemfunktionen_XIX_HCP3_IONode.RP_IF_PID_FanSpeed_XIX_Tracing_HCP3_IONode_XIX_CockpitInfotainment_Systemfunktionen_XIX_HCP3_IONode <-> outer port RP_IF_PID_FanSpeed_XIX_HCP3_IONode  # _XIX_PI_Common_XIX_UserInterface_XIX_PI_Disp_XIX_Tracing_HCP3_IONode_XIX_CockpitInfotainment_Systemfunktionen_XIX_HCP3_IONode_XIX_PID_FanSpeed
    delegate Tracing_HCP3_IONode_XIX_CockpitInfotainment_Systemfunktionen_XIX_HCP3_IONode.RP_IF_PID_ShutterFoil_Errorstate_XIX_Tracing_HCP3_IONode_XIX_CockpitInfotainment_Systemfunktionen_XIX_HCP3_IONode <-> outer port RP_IF_PID_ShutterFoil_Errorstate_XIX_HCP3_IONode  # _XIX_PI_Common_XIX_UserInterface_XIX_PI_Disp_XIX_Tracing_HCP3_IONode_XIX_CockpitInfotainment_Systemfunktionen_XIX_HCP3_IONode_XIX_PID_ShutterFoil_Errorstate
    delegate Tracing_HCP3_IONode_XIX_CockpitInfotainment_Systemfunktionen_XIX_HCP3_IONode.RP_IF_PID_LVDS_Splitter_Errorstate_XIX_Tracing_HCP3_IONode_XIX_CockpitInfotainment_Systemfunktionen_XIX_HCP3_IONode <-> outer port RP_IF_PID_LVDS_Splitter_Errorstate_XIX_HCP3_IONode  # _XIX_PI_Common_XIX_UserInterface_XIX_PI_Disp_XIX_Tracing_HCP3_IONode_XIX_CockpitInfotainment_Systemfunktionen_XIX_HCP3_IONode_XIX_PID_LVDS_Splitter_Errorstate
    delegate Tracing_HCP3_IONode_XIX_CockpitInfotainment_Systemfunktionen_XIX_HCP3_IONode.RP_IF_PID_PCB_Temp_Error_XIX_Tracing_HCP3_IONode_XIX_CockpitInfotainment_Systemfunktionen_XIX_HCP3_IONode <-> outer port RP_IF_PID_PCB_Temp_Error_XIX_HCP3_IONode  # _XIX_PI_Common_XIX_UserInterface_XIX_PI_Disp_XIX_Tracing_HCP3_IONode_XIX_CockpitInfotainment_Systemfunktionen_XIX_HCP3_IONode_XIX_PID_PCB_Temp_Error
    delegate Tracing_HCP3_IONode_XIX_CockpitInfotainment_Systemfunktionen_XIX_HCP3_IONode.RP_IF_PID_PCB_TempSensorMax_XIX_Tracing_HCP3_IONode_XIX_CockpitInfotainment_Systemfunktionen_XIX_HCP3_IONode <-> outer port RP_IF_PID_PCB_TempSensorMax_XIX_HCP3_IONode  # _XIX_PI_Common_XIX_UserInterface_XIX_PI_Disp_XIX_Tracing_HCP3_IONode_XIX_CockpitInfotainment_Systemfunktionen_XIX_HCP3_IONode_XIX_PID_PCB_TempSensorMax
    delegate Tracing_HCP3_IONode_XIX_CockpitInfotainment_Systemfunktionen_XIX_HCP3_IONode.RP_IF_PID_SW_inconsistent_XIX_Tracing_HCP3_IONode_XIX_CockpitInfotainment_Systemfunktionen_XIX_HCP3_IONode <-> outer port RP_IF_PID_SW_inconsistent_XIX_HCP3_IONode  # _XIX_PI_Common_XIX_UserInterface_XIX_PI_Disp_XIX_Tracing_HCP3_IONode_XIX_CockpitInfotainment_Systemfunktionen_XIX_HCP3_IONode_XIX_PID_SW_inconsistent
    delegate Tracing_HCP3_IONode_XIX_CockpitInfotainment_Systemfunktionen_XIX_HCP3_IONode.RP_IF_PID_OperatingTime_min_XIX_Tracing_HCP3_IONode_XIX_CockpitInfotainment_Systemfunktionen_XIX_HCP3_IONode <-> outer port RP_IF_PID_OperatingTime_min_XIX_HCP3_IONode  # _XIX_PI_Common_XIX_UserInterface_XIX_PI_Disp_XIX_Tracing_HCP3_IONode_XIX_CockpitInfotainment_Systemfunktionen_XIX_HCP3_IONode_XIX_PID_OperatingTime_min
    delegate Tracing_HCP3_IONode_XIX_CockpitInfotainment_Systemfunktionen_XIX_HCP3_IONode.RP_IF_PID_Touch_Errorstate_XIX_Tracing_HCP3_IONode_XIX_CockpitInfotainment_Systemfunktionen_XIX_HCP3_IONode <-> outer port RP_IF_PID_Touch_Errorstate_XIX_HCP3_IONode  # _XIX_PI_Common_XIX_UserInterface_XIX_PI_Disp_XIX_Tracing_HCP3_IONode_XIX_CockpitInfotainment_Systemfunktionen_XIX_HCP3_IONode_XIX_PID_Touch_Errorstate
    delegate Tracing_HCP3_IONode_XIX_CockpitInfotainment_Systemfunktionen_XIX_HCP3_IONode.RP_IF_PID_CL30_Undervoltage_Error_XIX_Tracing_HCP3_IONode_XIX_CockpitInfotainment_Systemfunktionen_XIX_HCP3_IONode <-> outer port RP_IF_PID_CL30_Undervoltage_Error_XIX_HCP3_IONode  # _XIX_PI_Common_XIX_UserInterface_XIX_PI_Disp_XIX_Tracing_HCP3_IONode_XIX_CockpitInfotainment_Systemfunktionen_XIX_HCP3_IONode_XIX_PID_CL30_Undervoltage_Error
    delegate Tracing_HCP3_IONode_XIX_CockpitInfotainment_Systemfunktionen_XIX_HCP3_IONode.RP_IF_PID_Haptik_Errorstate_XIX_Tracing_HCP3_IONode_XIX_CockpitInfotainment_Systemfunktionen_XIX_HCP3_IONode <-> outer port RP_IF_PID_Haptik_Errorstate_XIX_HCP3_IONode  # _XIX_PI_Common_XIX_UserInterface_XIX_PI_Disp_XIX_Tracing_HCP3_IONode_XIX_CockpitInfotainment_Systemfunktionen_XIX_HCP3_IONode_XIX_PID_Haptik_Errorstate
    delegate Tracing_HCP3_IONode_XIX_CockpitInfotainment_Systemfunktionen_XIX_HCP3_IONode.RP_IF_PID_Backlight_OpenCircuit_XIX_Tracing_HCP3_IONode_XIX_CockpitInfotainment_Systemfunktionen_XIX_HCP3_IONode <-> outer port RP_IF_PID_Backlight_OpenCircuit_XIX_HCP3_IONode  # _XIX_PI_Common_XIX_UserInterface_XIX_PI_Disp_XIX_Tracing_HCP3_IONode_XIX_CockpitInfotainment_Systemfunktionen_XIX_HCP3_IONode_XIX_PID_Backlight_OpenCircuit
    delegate Tracing_HCP3_IONode_XIX_CockpitInfotainment_Systemfunktionen_XIX_HCP3_IONode.RP_IF_PID_HDCP_Status_XIX_Tracing_HCP3_IONode_XIX_CockpitInfotainment_Systemfunktionen_XIX_HCP3_IONode <-> outer port RP_IF_PID_HDCP_Status_XIX_HCP3_IONode  # _XIX_PI_Common_XIX_UserInterface_XIX_PI_Disp_XIX_Tracing_HCP3_IONode_XIX_CockpitInfotainment_Systemfunktionen_XIX_HCP3_IONode_XIX_PID_HDCP_Status
    delegate Tracing_HCP3_IONode_XIX_CockpitInfotainment_Systemfunktionen_XIX_HCP3_IONode.RP_IF_PID_Photosensor_XIX_Tracing_HCP3_IONode_XIX_CockpitInfotainment_Systemfunktionen_XIX_HCP3_IONode <-> outer port RP_IF_PID_Photosensor_XIX_HCP3_IONode  # _XIX_PI_Common_XIX_UserInterface_XIX_PI_Disp_XIX_Tracing_HCP3_IONode_XIX_CockpitInfotainment_Systemfunktionen_XIX_HCP3_IONode_XIX_PID_Photosensor
    delegate VehicleComm_HCP3_IONode_XIX_CockpitInfotainment_Systemfunktionen_XIX_HCP3_IONode.RP_IF_PID_VA_Communication_Init_XIX_VehicleComm_HCP3_IONode_XIX_CockpitInfotainment_Systemfunktionen_XIX_HCP3_IONode <-> outer port RP_IF_PID_VA_Communication_Init_XIX_HCP3_IONode  # _XIX_PI_Common_XIX_UserInterface_XIX_PI_Disp_XIX_VehicleComm_HCP3_IONode_XIX_CockpitInfotainment_Systemfunktionen_XIX_HCP3_IONode_XIX_PID_VA_Communication_Init
    delegate VehicleComm_HCP3_IONode_XIX_CockpitInfotainment_Systemfunktionen_XIX_HCP3_IONode.RP_IF_PID_VA_Response_XIX_VehicleComm_HCP3_IONode_XIX_CockpitInfotainment_Systemfunktionen_XIX_HCP3_IONode <-> outer port RP_IF_PID_VA_Response_XIX_HCP3_IONode  # _XIX_PI_Common_XIX_UserInterface_XIX_PI_Disp_XIX_VehicleComm_HCP3_IONode_XIX_CockpitInfotainment_Systemfunktionen_XIX_HCP3_IONode_XIX_PID_VA_Response
    delegate VehicleComm_HCP3_IONode_XIX_CockpitInfotainment_Systemfunktionen_XIX_HCP3_IONode.RP_IF_PID_VA_Communication_Init_Ack_XIX_VehicleComm_HCP3_IONode_XIX_CockpitInfotainment_Systemfunktionen_XIX_HCP3_IONode <-> outer port RP_IF_PID_VA_Communication_Init_Ack_XIX_HCP3_IONode  # _XIX_PI_Common_XIX_UserInterface_XIX_PI_Disp_XIX_VehicleComm_HCP3_IONode_XIX_CockpitInfotainment_Systemfunktionen_XIX_HCP3_IONode_XIX_PID_VA_Communication_Init_Ack
    delegate Tracing_HCP3_IONode_XIX_CockpitInfotainment_Systemfunktionen_XIX_HCP3_IONode.RP_IF_PID_VW_SL_HW_Version_Nr_XIX_Tracing_HCP3_IONode_XIX_CockpitInfotainment_Systemfunktionen_XIX_HCP3_IONode <-> outer port RP_IF_PID_VW_SL_HW_Version_Nr_XIX_HCP3_IONode  # _XIX_PI_ECU_Info_XIX_UserInterface_XIX_PI_Disp_XIX_Tracing_HCP3_IONode_XIX_CockpitInfotainment_Systemfunktionen_XIX_HCP3_IONode_XIX_PID_VW_SL_HW_Version_Nr
    delegate Tracing_HCP3_IONode_XIX_CockpitInfotainment_Systemfunktionen_XIX_HCP3_IONode.RP_IF_PID_VW_SL_Spare_Part_Nr_EndNr_XIX_Tracing_HCP3_IONode_XIX_CockpitInfotainment_Systemfunktionen_XIX_HCP3_IONode <-> outer port RP_IF_PID_VW_SL_Spare_Part_Nr_EndNr_XIX_HCP3_IONode  # _XIX_PI_ECU_Info_XIX_UserInterface_XIX_PI_Disp_XIX_Tracing_HCP3_IONode_XIX_CockpitInfotainment_Systemfunktionen_XIX_HCP3_IONode_XIX_PID_VW_SL_Spare_Part_Nr_EndNr
    delegate Tracing_HCP3_IONode_XIX_CockpitInfotainment_Systemfunktionen_XIX_HCP3_IONode.RP_IF_PID_VW_SL_App_SW_Version_Nr_XIX_Tracing_HCP3_IONode_XIX_CockpitInfotainment_Systemfunktionen_XIX_HCP3_IONode <-> outer port RP_IF_PID_VW_SL_App_SW_Version_Nr_XIX_HCP3_IONode  # _XIX_PI_ECU_Info_XIX_UserInterface_XIX_PI_Disp_XIX_Tracing_HCP3_IONode_XIX_CockpitInfotainment_Systemfunktionen_XIX_HCP3_IONode_XIX_PID_VW_SL_App_SW_Version_Nr
    delegate Tracing_HCP3_IONode_XIX_CockpitInfotainment_Systemfunktionen_XIX_HCP3_IONode.RP_IF_PID_VW_SL_Spare_Part_Nr_TMA_XIX_Tracing_HCP3_IONode_XIX_CockpitInfotainment_Systemfunktionen_XIX_HCP3_IONode <-> outer port RP_IF_PID_VW_SL_Spare_Part_Nr_TMA_XIX_HCP3_IONode  # _XIX_PI_ECU_Info_XIX_UserInterface_XIX_PI_Disp_XIX_Tracing_HCP3_IONode_XIX_CockpitInfotainment_Systemfunktionen_XIX_HCP3_IONode_XIX_PID_VW_SL_Spare_Part_Nr_TMA
    delegate Tracing_HCP3_IONode_XIX_CockpitInfotainment_Systemfunktionen_XIX_HCP3_IONode.RP_IF_PID_VW_SL_Spare_Part_Nr_Index_XIX_Tracing_HCP3_IONode_XIX_CockpitInfotainment_Systemfunktionen_XIX_HCP3_IONode <-> outer port RP_IF_PID_VW_SL_Spare_Part_Nr_Index_XIX_HCP3_IONode  # _XIX_PI_ECU_Info_XIX_UserInterface_XIX_PI_Disp_XIX_Tracing_HCP3_IONode_XIX_CockpitInfotainment_Systemfunktionen_XIX_HCP3_IONode_XIX_PID_VW_SL_Spare_Part_Nr_Index
    delegate Tracing_HCP3_IONode_XIX_CockpitInfotainment_Systemfunktionen_XIX_HCP3_IONode.RP_IF_PID_VW_SL_Spare_Part_Nr_MittelNr_XIX_Tracing_HCP3_IONode_XIX_CockpitInfotainment_Systemfunktionen_XIX_HCP3_IONode <-> outer port RP_IF_PID_VW_SL_Spare_Part_Nr_MittelNr_XIX_HCP3_IONode  # _XIX_PI_ECU_Info_XIX_UserInterface_XIX_PI_Disp_XIX_Tracing_HCP3_IONode_XIX_CockpitInfotainment_Systemfunktionen_XIX_HCP3_IONode_XIX_PID_VW_SL_Spare_Part_Nr_MittelNr
    delegate PowerManagement_HCP3_IONode_XIX_CockpitInfotainment_Systemfunktionen_XIX_HCP3_IONode.SP_IF_ZR_State_CID_XIX_PowerManagement_HCP3_IONode_XIX_CockpitInfotainment_Systemfunktionen_XIX_HCP3_IONode <-> outer port SP_IF_ZR_State_CID_XIX_HCP3_IONode  # _XIX_PowerManagement_HCP3_IONode_XIX_CockpitInfotainment_Systemfunktionen_XIX_HCP3_IONode_XIX_CI_Common_XIX_UserInterface_XIX_CI_Disp_XIX_ZR_State_CID
    delegate PowerManagement_HCP3_IONode_XIX_CockpitInfotainment_Systemfunktionen_XIX_HCP3_IONode.SP_IF_ZR_State_FID_XIX_PowerManagement_HCP3_IONode_XIX_CockpitInfotainment_Systemfunktionen_XIX_HCP3_IONode <-> outer port SP_IF_ZR_State_FID_XIX_HCP3_IONode  # _XIX_PowerManagement_HCP3_IONode_XIX_CockpitInfotainment_Systemfunktionen_XIX_HCP3_IONode_XIX_FIDAnzeigen_XIX_Fahrerinformation_XIX_Kombi_XIX_ZR_State_FID
    delegate PowerManagement_HCP3_IONode_XIX_CockpitInfotainment_Systemfunktionen_XIX_HCP3_IONode.SP_IF_ZR_State_PID_XIX_PowerManagement_HCP3_IONode_XIX_CockpitInfotainment_Systemfunktionen_XIX_HCP3_IONode <-> outer port SP_IF_ZR_State_PID_XIX_HCP3_IONode  # _XIX_PowerManagement_HCP3_IONode_XIX_CockpitInfotainment_Systemfunktionen_XIX_HCP3_IONode_XIX_PI_Common_XIX_UserInterface_XIX_PI_Disp_XIX_ZR_State_PID
    delegate VehicleComm_HCP3_IONode_XIX_CockpitInfotainment_Systemfunktionen_XIX_HCP3_IONode.RP_IF_PTAcvSrv_StDrvMd_XIX_VehicleComm_HCP3_IONode_XIX_CockpitInfotainment_Systemfunktionen_XIX_HCP3_IONode <-> outer port RP_IF_PTAcvSrv_StDrvMd_XIX_HCP3_IONode  # _XIX_PowertrainActivationService_XIX_Rekuperation_XIX_HCP1_XIX_VehicleComm_HCP3_IONode_XIX_CockpitInfotainment_Systemfunktionen_XIX_HCP3_IONode_XIX_PTAcvSrv_StDrvMd
    delegate VehicleComm_HCP3_IONode_XIX_CockpitInfotainment_Systemfunktionen_XIX_HCP3_IONode.RP_IF_PTAcvSrv_StPwrMd_XIX_VehicleComm_HCP3_IONode_XIX_CockpitInfotainment_Systemfunktionen_XIX_HCP3_IONode <-> outer port RP_IF_PTAcvSrv_StPwrMd_XIX_HCP3_IONode  # _XIX_PowertrainActivationService_XIX_Rekuperation_XIX_HCP1_XIX_VehicleComm_HCP3_IONode_XIX_CockpitInfotainment_Systemfunktionen_XIX_HCP3_IONode_XIX_PTAcvSrv_StPwrMd
    delegate SOK_Participant_HCP3_IONode_XIX_SOK_XIX_HCP3_IONode.SP_IF_SOK_Zeit_Info_El_Challenge_XIX_SOK_Participant_HCP3_IONode_XIX_SOK_XIX_HCP3_IONode <-> outer port SP_IF_SOK_Zeit_Info_El_Challenge_XIX_HCP3_IONode  # _XIX_SOK_Participant_HCP3_IONode_XIX_SOK_XIX_HCP3_IONode_XIX_SOK_TimeServer_XIX_SOK_XIX_HCP5_P1_Gateway_XIX_SOK_Zeit_Info_El_Challenge
    delegate SOK_Participant_HCP3_IONode_XIX_SOK_XIX_HCP3_IONode.RP_IF_SOK_Zeit_Info_El_Zeit_XIX_SOK_Participant_HCP3_IONode_XIX_SOK_XIX_HCP3_IONode <-> outer port RP_IF_SOK_Zeit_Info_El_Zeit_XIX_HCP3_IONode  # _XIX_SOK_TimeServer_XIX_SOK_XIX_HCP5_P1_Gateway_XIX_SOK_Participant_HCP3_IONode_XIX_SOK_XIX_HCP3_IONode_XIX_SOK_Zeit_Info_El_Zeit
    delegate SOK_Participant_HCP3_IONode_XIX_SOK_XIX_HCP3_IONode.RP_IF_SOK_ungeschuetzte_Zeit_XIX_SOK_Participant_HCP3_IONode_XIX_SOK_XIX_HCP3_IONode <-> outer port RP_IF_SOK_ungeschuetzte_Zeit_XIX_HCP3_IONode  # _XIX_SOK_TimeServer_XIX_SOK_XIX_HCP5_P1_Gateway_XIX_SOK_Participant_HCP3_IONode_XIX_SOK_XIX_HCP3_IONode_XIX_SOK_ungeschuetzte_Zeit
    delegate TankAlgorithm_XIX_Tank_XIX_HCP3_IONode.RP_IF_TG_Geber_1_Mittelwert_XIX_TankAlgorithm_XIX_Tank_XIX_HCP3_IONode <-> outer port RP_IF_TG_Geber_1_Mittelwert_XIX_HCP3_IONode
    delegate TankAlgorithm_XIX_Tank_XIX_HCP3_IONode.RP_IF_TG_Geber_1_Stand_XIX_TankAlgorithm_XIX_Tank_XIX_HCP3_IONode <-> outer port RP_IF_TG_Geber_1_Stand_XIX_HCP3_IONode
    delegate TankAlgorithm_XIX_Tank_XIX_HCP3_IONode.RP_IF_TG_Geber_2_Mittelwert_XIX_TankAlgorithm_XIX_Tank_XIX_HCP3_IONode <-> outer port RP_IF_TG_Geber_2_Mittelwert_XIX_HCP3_IONode
    delegate TankAlgorithm_XIX_Tank_XIX_HCP3_IONode.RP_IF_TG_Geber_2_Stand_XIX_TankAlgorithm_XIX_Tank_XIX_HCP3_IONode <-> outer port RP_IF_TG_Geber_2_Stand_XIX_HCP3_IONode
    delegate TankAlgorithm_XIX_Tank_XIX_HCP3_IONode.RP_IF_TG_Geber_3_Mittelwert_XIX_TankAlgorithm_XIX_Tank_XIX_HCP3_IONode <-> outer port RP_IF_TG_Geber_3_Mittelwert_XIX_HCP3_IONode
    delegate TankAlgorithm_XIX_Tank_XIX_HCP3_IONode.RP_IF_TG_Geber_3_Stand_XIX_TankAlgorithm_XIX_Tank_XIX_HCP3_IONode <-> outer port RP_IF_TG_Geber_3_Stand_XIX_HCP3_IONode
    delegate TankAlgorithm_XIX_Tank_XIX_HCP3_IONode.RP_IF_TG_Geber_4_Mittelwert_XIX_TankAlgorithm_XIX_Tank_XIX_HCP3_IONode <-> outer port RP_IF_TG_Geber_4_Mittelwert_XIX_HCP3_IONode
    delegate TankAlgorithm_XIX_Tank_XIX_HCP3_IONode.RP_IF_TG_Geber_4_Stand_XIX_TankAlgorithm_XIX_Tank_XIX_HCP3_IONode <-> outer port RP_IF_TG_Geber_4_Stand_XIX_HCP3_IONode
    delegate TankAlgorithm_XIX_Tank_XIX_HCP3_IONode.RP_IF_TG_QBit_Geber_{1..4}_XIX_TankAlgorithm_XIX_Tank_XIX_HCP3_IONode <-> outer port RP_IF_TG_QBit_Geber_{1..4}_XIX_HCP3_IONode
    delegate TankAlgorithm_XIX_Tank_XIX_HCP3_IONode.RP_IF_STH_KVS_XIX_TankAlgorithm_XIX_Tank_XIX_HCP3_IONode <-> outer port RP_IF_STH_KVS_XIX_HCP3_IONode
    delegate TankAlgorithm_XIX_Tank_XIX_HCP3_IONode.RP_IF_STH_KVS_Ueberlauf_XIX_TankAlgorithm_XIX_Tank_XIX_HCP3_IONode <-> outer port RP_IF_STH_KVS_Ueberlauf_XIX_HCP3_IONode
    delegate TankAlgorithm_XIX_Tank_XIX_HCP3_IONode.SP_IF_TNK_FStatus_Tank_XIX_TankAlgorithm_XIX_Tank_XIX_HCP3_IONode <-> outer port SP_IF_TNK_FStatus_Tank_XIX_HCP3_IONode  # _XIX_TankAlgorithm_XIX_Tank_XIX_HCP3_IONode_XIX_ClusterHMI_XIX_FahrerinformationUndBedienung_XIX_HCP3_CN1_Cluster_XIX_TNK_FStatus_Tank
    delegate TankAlgorithm_XIX_Tank_XIX_HCP3_IONode.SP_IF_TNK_Kraftstoffvorrat_XIX_TankAlgorithm_XIX_Tank_XIX_HCP3_IONode <-> outer port SP_IF_TNK_Kraftstoffvorrat_XIX_HCP3_IONode  # _XIX_TankAlgorithm_XIX_Tank_XIX_HCP3_IONode_XIX_ClusterHMI_XIX_FahrerinformationUndBedienung_XIX_HCP3_CN1_Cluster_XIX_TNK_Kraftstoffvorrat
    delegate TankAlgorithm_XIX_Tank_XIX_HCP3_IONode.SP_IF_TNK_Max_Tankinhalt_XIX_TankAlgorithm_XIX_Tank_XIX_HCP3_IONode <-> outer port SP_IF_TNK_Max_Tankinhalt_XIX_HCP3_IONode  # _XIX_TankAlgorithm_XIX_Tank_XIX_HCP3_IONode_XIX_ClusterHMI_XIX_FahrerinformationUndBedienung_XIX_HCP3_CN1_Cluster_XIX_TNK_Max_Tankinhalt
    delegate TankAlgorithm_XIX_Tank_XIX_HCP3_IONode.SP_IF_TNK_Min_Tankinhalt_XIX_TankAlgorithm_XIX_Tank_XIX_HCP3_IONode <-> outer port SP_IF_TNK_Min_Tankinhalt_XIX_HCP3_IONode  # _XIX_TankAlgorithm_XIX_Tank_XIX_HCP3_IONode_XIX_ClusterHMI_XIX_FahrerinformationUndBedienung_XIX_HCP3_CN1_Cluster_XIX_TNK_Min_Tankinhalt
    delegate TankAlgorithm_XIX_Tank_XIX_HCP3_IONode.SP_IF_TNK_Nachtanken_erkannt_XIX_TankAlgorithm_XIX_Tank_XIX_HCP3_IONode <-> outer port SP_IF_TNK_Nachtanken_erkannt_XIX_HCP3_IONode  # _XIX_TankAlgorithm_XIX_Tank_XIX_HCP3_IONode_XIX_ClusterHMI_XIX_FahrerinformationUndBedienung_XIX_HCP3_CN1_Cluster_XIX_TNK_Nachtanken_erkannt
    delegate TankAlgorithm_XIX_Tank_XIX_HCP3_IONode.SP_IF_TNK_Tankanzeigefreigabe_XIX_TankAlgorithm_XIX_Tank_XIX_HCP3_IONode <-> outer port SP_IF_TNK_Tankanzeigefreigabe_XIX_HCP3_IONode  # _XIX_TankAlgorithm_XIX_Tank_XIX_HCP3_IONode_XIX_ClusterHMI_XIX_FahrerinformationUndBedienung_XIX_HCP3_CN1_Cluster_XIX_TNK_Tankanzeigefreigabe
    delegate TankAlgorithm_XIX_Tank_XIX_HCP3_IONode.SP_IF_TNK_Tankinhalt_hochaufl_XIX_TankAlgorithm_XIX_Tank_XIX_HCP3_IONode <-> outer port SP_IF_TNK_Tankinhalt_hochaufl_XIX_HCP3_IONode  # _XIX_TankAlgorithm_XIX_Tank_XIX_HCP3_IONode_XIX_ClusterHMI_XIX_FahrerinformationUndBedienung_XIX_HCP3_CN1_Cluster_XIX_TNK_Tankinhalt_hochaufl
    delegate TankAlgorithm_XIX_Tank_XIX_HCP3_IONode.SP_IF_TNK_Tankinhalt_roh_XIX_TankAlgorithm_XIX_Tank_XIX_HCP3_IONode <-> outer port SP_IF_TNK_Tankinhalt_roh_XIX_HCP3_IONode
    delegate TankAlgorithm_XIX_Tank_XIX_HCP3_IONode.SP_IF_TNK_Tankwarnung_XIX_TankAlgorithm_XIX_Tank_XIX_HCP3_IONode <-> outer port SP_IF_TNK_Tankwarnung_XIX_HCP3_IONode
    delegate TankAlgorithm_XIX_Tank_XIX_HCP3_IONode.SP_IF_TNK_Tankwarnung_ungueltig_XIX_TankAlgorithm_XIX_Tank_XIX_HCP3_IONode <-> outer port SP_IF_TNK_Tankwarnung_ungueltig_XIX_HCP3_IONode  # _XIX_TankAlgorithm_XIX_Tank_XIX_HCP3_IONode_XIX_ClusterHMI_XIX_FahrerinformationUndBedienung_XIX_HCP3_CN1_Cluster_XIX_TNK_Tankwarnung_ungueltig
    delegate TankAlgorithm_XIX_Tank_XIX_HCP3_IONode.SP_IF_TNK_Wegstrecke_Hinweis_XIX_TankAlgorithm_XIX_Tank_XIX_HCP3_IONode <-> outer port SP_IF_TNK_Wegstrecke_Hinweis_XIX_HCP3_IONode  # _XIX_TankAlgorithm_XIX_Tank_XIX_HCP3_IONode_XIX_DriverWarningValidator_XIX_FahrerinformationUndBedienung_XIX_HCP3_CN1_Cluster_XIX_TNK_Wegstrecke_Hinweis
    delegate diagnosis_infrastructure_Info_El_XIX_diagnosis_infrastructure_XIX_HCP3_IONode.RP_IF_UH_Stunde_XIX_diagnosis_infrastructure_Info_El_XIX_diagnosis_infrastructure_XIX_HCP3_IONode <-> outer port RP_IF_UH_Stunde_XIX_HCP3_IONode  # _XIX_TimeMaster_Base_XIX_ZM_XIX_HCP5_P1_Gateway_XIX_diagnosis_infrastructure_Info_El_XIX_diagnosis_infrastructure_XIX_HCP3_IONode_XIX_UH_Stunde
    delegate diagnosis_infrastructure_Info_El_XIX_diagnosis_infrastructure_XIX_HCP3_IONode.RP_IF_UH_Minute_XIX_diagnosis_infrastructure_Info_El_XIX_diagnosis_infrastructure_XIX_HCP3_IONode <-> outer port RP_IF_UH_Minute_XIX_HCP3_IONode  # _XIX_TimeMaster_Base_XIX_ZM_XIX_HCP5_P1_Gateway_XIX_diagnosis_infrastructure_Info_El_XIX_diagnosis_infrastructure_XIX_HCP3_IONode_XIX_UH_Minute
    delegate diagnosis_infrastructure_Info_El_XIX_diagnosis_infrastructure_XIX_HCP3_IONode.RP_IF_UH_Jahr_XIX_diagnosis_infrastructure_Info_El_XIX_diagnosis_infrastructure_XIX_HCP3_IONode <-> outer port RP_IF_UH_Jahr_XIX_HCP3_IONode  # _XIX_TimeMaster_Base_XIX_ZM_XIX_HCP5_P1_Gateway_XIX_diagnosis_infrastructure_Info_El_XIX_diagnosis_infrastructure_XIX_HCP3_IONode_XIX_UH_Jahr
    delegate diagnosis_infrastructure_Info_El_XIX_diagnosis_infrastructure_XIX_HCP3_IONode.RP_IF_UH_Sekunde_XIX_diagnosis_infrastructure_Info_El_XIX_diagnosis_infrastructure_XIX_HCP3_IONode <-> outer port RP_IF_UH_Sekunde_XIX_HCP3_IONode  # _XIX_TimeMaster_Base_XIX_ZM_XIX_HCP5_P1_Gateway_XIX_diagnosis_infrastructure_Info_El_XIX_diagnosis_infrastructure_XIX_HCP3_IONode_XIX_UH_Sekunde
    delegate diagnosis_infrastructure_Info_El_XIX_diagnosis_infrastructure_XIX_HCP3_IONode.RP_IF_UH_Tag_XIX_diagnosis_infrastructure_Info_El_XIX_diagnosis_infrastructure_XIX_HCP3_IONode <-> outer port RP_IF_UH_Tag_XIX_HCP3_IONode  # _XIX_TimeMaster_Base_XIX_ZM_XIX_HCP5_P1_Gateway_XIX_diagnosis_infrastructure_Info_El_XIX_diagnosis_infrastructure_XIX_HCP3_IONode_XIX_UH_Tag
    delegate diagnosis_infrastructure_Info_El_XIX_diagnosis_infrastructure_XIX_HCP3_IONode.RP_IF_UH_Monat_XIX_diagnosis_infrastructure_Info_El_XIX_diagnosis_infrastructure_XIX_HCP3_IONode <-> outer port RP_IF_UH_Monat_XIX_HCP3_IONode  # _XIX_TimeMaster_Base_XIX_ZM_XIX_HCP5_P1_Gateway_XIX_diagnosis_infrastructure_Info_El_XIX_diagnosis_infrastructure_XIX_HCP3_IONode_XIX_UH_Monat
    delegate Tracing_HCP3_IONode_XIX_CockpitInfotainment_Systemfunktionen_XIX_HCP3_IONode.SP_IF_ZR_CL_Mode_XIX_Tracing_HCP3_IONode_XIX_CockpitInfotainment_Systemfunktionen_XIX_HCP3_IONode <-> outer port SP_IF_ZR_CL_Mode_XIX_HCP3_IONode  # _XIX_Tracing_HCP3_IONode_XIX_CockpitInfotainment_Systemfunktionen_XIX_HCP3_IONode_XIX_CI_Common_XIX_UserInterface_XIX_CI_Disp_XIX_ZR_CL_Mode
    delegate Tracing_HCP3_IONode_XIX_CockpitInfotainment_Systemfunktionen_XIX_HCP3_IONode.SP_IF_ZR_HUD_Mode_XIX_Tracing_HCP3_IONode_XIX_CockpitInfotainment_Systemfunktionen_XIX_HCP3_IONode <-> outer port SP_IF_ZR_HUD_Mode_XIX_HCP3_IONode  # _XIX_Tracing_HCP3_IONode_XIX_CockpitInfotainment_Systemfunktionen_XIX_HCP3_IONode_XIX_CI_Common_XIX_UserInterface_XIX_CI_Disp_XIX_ZR_HUD_Mode
    delegate Tracing_HCP3_IONode_XIX_CockpitInfotainment_Systemfunktionen_XIX_HCP3_IONode.SP_IF_ZR_IOC_Mode_XIX_Tracing_HCP3_IONode_XIX_CockpitInfotainment_Systemfunktionen_XIX_HCP3_IONode <-> outer port SP_IF_ZR_IOC_Mode_XIX_HCP3_IONode  # _XIX_Tracing_HCP3_IONode_XIX_CockpitInfotainment_Systemfunktionen_XIX_HCP3_IONode_XIX_CI_Common_XIX_UserInterface_XIX_CI_Disp_XIX_ZR_IOC_Mode
    delegate Tracing_HCP3_IONode_XIX_CockpitInfotainment_Systemfunktionen_XIX_HCP3_IONode.SP_IF_ZR_IVI1_Mode_XIX_Tracing_HCP3_IONode_XIX_CockpitInfotainment_Systemfunktionen_XIX_HCP3_IONode <-> outer port SP_IF_ZR_IVI1_Mode_XIX_HCP3_IONode  # _XIX_Tracing_HCP3_IONode_XIX_CockpitInfotainment_Systemfunktionen_XIX_HCP3_IONode_XIX_CI_Common_XIX_UserInterface_XIX_CI_Disp_XIX_ZR_IVI1_Mode
    delegate Tracing_HCP3_IONode_XIX_CockpitInfotainment_Systemfunktionen_XIX_HCP3_IONode.SP_IF_ZR_SYS1_Mode_XIX_Tracing_HCP3_IONode_XIX_CockpitInfotainment_Systemfunktionen_XIX_HCP3_IONode <-> outer port SP_IF_ZR_SYS1_Mode_XIX_HCP3_IONode  # _XIX_Tracing_HCP3_IONode_XIX_CockpitInfotainment_Systemfunktionen_XIX_HCP3_IONode_XIX_CI_Common_XIX_UserInterface_XIX_CI_Disp_XIX_ZR_SYS1_Mode
    delegate VehicleComm_HCP3_IONode_XIX_CockpitInfotainment_Systemfunktionen_XIX_HCP3_IONode.RP_IF_BT_Tuer_Status_XIX_VehicleComm_HCP3_IONode_XIX_CockpitInfotainment_Systemfunktionen_XIX_HCP3_IONode <-> outer port RP_IF_BT_Tuer_Status_XIX_HCP3_IONode  # _XIX_Tuerfunktionen_BFS_XIX_DoorFunctions_XIX_TSG_BFS_XIX_VehicleComm_HCP3_IONode_XIX_CockpitInfotainment_Systemfunktionen_XIX_HCP3_IONode_XIX_BT_Tuer_Status
    delegate PowerManagement_HCP3_IONode_XIX_CockpitInfotainment_Systemfunktionen_XIX_HCP3_IONode.RP_IF_FT_Tuer_Status_XIX_PowerManagement_HCP3_IONode_XIX_CockpitInfotainment_Systemfunktionen_XIX_HCP3_IONode <-> outer port RP_IF_FT_Tuer_Status_XIX_HCP3_IONode  # _XIX_Tuerfunktionen_FS_XIX_DoorFunctions_XIX_TSG_FS_XIX_PowerManagement_HCP3_IONode_XIX_CockpitInfotainment_Systemfunktionen_XIX_HCP3_IONode_XIX_FT_Tuer_Status
    delegate VehicleComm_HCP3_IONode_XIX_CockpitInfotainment_Systemfunktionen_XIX_HCP3_IONode.RP_IF_FT_Tuer_Status_XIX_VehicleComm_HCP3_IONode_XIX_CockpitInfotainment_Systemfunktionen_XIX_HCP3_IONode <-> outer port RP_IF_FT_Tuer_Status_XIX_HCP3_IONode  # _XIX_Tuerfunktionen_FS_XIX_DoorFunctions_XIX_TSG_FS_XIX_VehicleComm_HCP3_IONode_XIX_CockpitInfotainment_Systemfunktionen_XIX_HCP3_IONode_XIX_FT_Tuer_Status
    delegate VehicleComm_HCP3_IONode_XIX_CockpitInfotainment_Systemfunktionen_XIX_HCP3_IONode.RP_IF_FT_Tuer_geoeffnet_XIX_VehicleComm_HCP3_IONode_XIX_CockpitInfotainment_Systemfunktionen_XIX_HCP3_IONode <-> outer port RP_IF_FT_Tuer_geoeffnet_XIX_HCP3_IONode  # _XIX_Tuerfunktionen_FS_XIX_DoorFunctions_XIX_TSG_FS_XIX_VehicleComm_HCP3_IONode_XIX_CockpitInfotainment_Systemfunktionen_XIX_HCP3_IONode_XIX_FT_Tuer_geoeffnet
    delegate VehicleComm_HCP3_IONode_XIX_CockpitInfotainment_Systemfunktionen_XIX_HCP3_IONode.RP_IF_HBFS_Tuer_Status_XIX_VehicleComm_HCP3_IONode_XIX_CockpitInfotainment_Systemfunktionen_XIX_HCP3_IONode <-> outer port RP_IF_HBFS_Tuer_Status_XIX_HCP3_IONode  # _XIX_Tuerfunktionen_HBFS_XIX_DoorFunctions_XIX_TSG_HBFS_XIX_VehicleComm_HCP3_IONode_XIX_CockpitInfotainment_Systemfunktionen_XIX_HCP3_IONode_XIX_HBFS_Tuer_Status
    delegate VehicleComm_HCP3_IONode_XIX_CockpitInfotainment_Systemfunktionen_XIX_HCP3_IONode.RP_IF_HFS_Tuer_Status_XIX_VehicleComm_HCP3_IONode_XIX_CockpitInfotainment_Systemfunktionen_XIX_HCP3_IONode <-> outer port RP_IF_HFS_Tuer_Status_XIX_HCP3_IONode  # _XIX_Tuerfunktionen_HFS_XIX_DoorFunctions_XIX_TSG_HFS_XIX_VehicleComm_HCP3_IONode_XIX_CockpitInfotainment_Systemfunktionen_XIX_HCP3_IONode_XIX_HFS_Tuer_Status
    delegate VehicleComm_HCP3_IONode_XIX_CockpitInfotainment_Systemfunktionen_XIX_HCP3_IONode.SP_IF_RA_AM_Tuning_XIX_VehicleComm_HCP3_IONode_XIX_CockpitInfotainment_Systemfunktionen_XIX_HCP3_IONode <-> outer port SP_IF_RA_AM_Tuning_XIX_HCP3_IONode  # _XIX_VehicleComm_HCP3_IONode_XIX_CockpitInfotainment_Systemfunktionen_XIX_HCP3_IONode_XIX_TrailerFunctions_XIX_TrailerFunctions_XIX_AAG_XIX_RA_AM_Tuning
    delegate VehicleComm_HCP3_IONode_XIX_CockpitInfotainment_Systemfunktionen_XIX_HCP3_IONode.SP_IF_RA_Frequency_XIX_VehicleComm_HCP3_IONode_XIX_CockpitInfotainment_Systemfunktionen_XIX_HCP3_IONode <-> outer port SP_IF_RA_Frequency_XIX_HCP3_IONode  # _XIX_VehicleComm_HCP3_IONode_XIX_CockpitInfotainment_Systemfunktionen_XIX_HCP3_IONode_XIX_TrailerFunctions_XIX_TrailerFunctions_XIX_AAG_XIX_RA_Frequency
    delegate VehicleComm_HCP3_IONode_XIX_CockpitInfotainment_Systemfunktionen_XIX_HCP3_IONode.SP_IF_RA_Frequency_unit_XIX_VehicleComm_HCP3_IONode_XIX_CockpitInfotainment_Systemfunktionen_XIX_HCP3_IONode <-> outer port SP_IF_RA_Frequency_unit_XIX_HCP3_IONode  # _XIX_VehicleComm_HCP3_IONode_XIX_CockpitInfotainment_Systemfunktionen_XIX_HCP3_IONode_XIX_TrailerFunctions_XIX_TrailerFunctions_XIX_AAG_XIX_RA_Frequency_unit
    delegate VehicleComm_HCP3_IONode_XIX_CockpitInfotainment_Systemfunktionen_XIX_HCP3_IONode.SP_IF_WLC1_Systemzustand_XIX_VehicleComm_HCP3_IONode_XIX_CockpitInfotainment_Systemfunktionen_XIX_HCP3_IONode <-> outer port SP_IF_WLC1_Systemzustand_XIX_HCP3_IONode  # _XIX_VehicleComm_HCP3_IONode_XIX_CockpitInfotainment_Systemfunktionen_XIX_HCP3_IONode_XIX_VehicleConnectorHighLevelAPI_XIX_VC_IoT_XIX_HCP5_P6_MOD_XIX_WLC1_Systemzustand
    delegate VehicleComm_HCP3_IONode_XIX_CockpitInfotainment_Systemfunktionen_XIX_HCP3_IONode.SP_IF_WLC2_Systemzustand_XIX_VehicleComm_HCP3_IONode_XIX_CockpitInfotainment_Systemfunktionen_XIX_HCP3_IONode <-> outer port SP_IF_WLC2_Systemzustand_XIX_HCP3_IONode  # _XIX_VehicleComm_HCP3_IONode_XIX_CockpitInfotainment_Systemfunktionen_XIX_HCP3_IONode_XIX_VehicleConnectorHighLevelAPI_XIX_VC_IoT_XIX_HCP5_P6_MOD_XIX_WLC2_Systemzustand
    delegate VehicleComm_HCP3_IONode_XIX_CockpitInfotainment_Systemfunktionen_XIX_HCP3_IONode.SP_IF_ZR_VA_Challenge_CID_XIX_VehicleComm_HCP3_IONode_XIX_CockpitInfotainment_Systemfunktionen_XIX_HCP3_IONode <-> outer port SP_IF_ZR_VA_Challenge_CID_XIX_HCP3_IONode  # _XIX_VehicleComm_HCP3_IONode_XIX_CockpitInfotainment_Systemfunktionen_XIX_HCP3_IONode_XIX_CI_Common_XIX_UserInterface_XIX_CI_Disp_XIX_ZR_VA_Challenge_CID
    delegate VehicleComm_HCP3_IONode_XIX_CockpitInfotainment_Systemfunktionen_XIX_HCP3_IONode.SP_IF_ZR_VA_Challenge_FID_XIX_VehicleComm_HCP3_IONode_XIX_CockpitInfotainment_Systemfunktionen_XIX_HCP3_IONode <-> outer port SP_IF_ZR_VA_Challenge_FID_XIX_HCP3_IONode  # _XIX_VehicleComm_HCP3_IONode_XIX_CockpitInfotainment_Systemfunktionen_XIX_HCP3_IONode_XIX_FIDAnzeigen_XIX_Fahrerinformation_XIX_Kombi_XIX_ZR_VA_Challenge_FID
    delegate VehicleComm_HCP3_IONode_XIX_CockpitInfotainment_Systemfunktionen_XIX_HCP3_IONode.SP_IF_ZR_VA_Challenge_PID_XIX_VehicleComm_HCP3_IONode_XIX_CockpitInfotainment_Systemfunktionen_XIX_HCP3_IONode <-> outer port SP_IF_ZR_VA_Challenge_PID_XIX_HCP3_IONode  # _XIX_VehicleComm_HCP3_IONode_XIX_CockpitInfotainment_Systemfunktionen_XIX_HCP3_IONode_XIX_PI_Common_XIX_UserInterface_XIX_PI_Disp_XIX_ZR_VA_Challenge_PID
    delegate VehicleComm_HCP3_IONode_XIX_CockpitInfotainment_Systemfunktionen_XIX_HCP3_IONode.SP_IF_ZR_VA_Communication_Init_Ack_CID_XIX_VehicleComm_HCP3_IONode_XIX_CockpitInfotainment_Systemfunktionen_XIX_HCP3_IONode <-> outer port SP_IF_ZR_VA_Communication_Init_Ack_CID_XIX_HCP3_IONode  # _XIX_VehicleComm_HCP3_IONode_XIX_CockpitInfotainment_Systemfunktionen_XIX_HCP3_IONode_XIX_CI_Common_XIX_UserInterface_XIX_CI_Disp_XIX_ZR_VA_Communication_Init_Ack_CID
    delegate VehicleComm_HCP3_IONode_XIX_CockpitInfotainment_Systemfunktionen_XIX_HCP3_IONode.SP_IF_ZR_VA_Communication_Init_Ack_FID_XIX_VehicleComm_HCP3_IONode_XIX_CockpitInfotainment_Systemfunktionen_XIX_HCP3_IONode <-> outer port SP_IF_ZR_VA_Communication_Init_Ack_FID_XIX_HCP3_IONode  # _XIX_VehicleComm_HCP3_IONode_XIX_CockpitInfotainment_Systemfunktionen_XIX_HCP3_IONode_XIX_FIDAnzeigen_XIX_Fahrerinformation_XIX_Kombi_XIX_ZR_VA_Communication_Init_Ack_FID
    delegate VehicleComm_HCP3_IONode_XIX_CockpitInfotainment_Systemfunktionen_XIX_HCP3_IONode.SP_IF_ZR_VA_Communication_Init_Ack_PID_XIX_VehicleComm_HCP3_IONode_XIX_CockpitInfotainment_Systemfunktionen_XIX_HCP3_IONode <-> outer port SP_IF_ZR_VA_Communication_Init_Ack_PID_XIX_HCP3_IONode  # _XIX_VehicleComm_HCP3_IONode_XIX_CockpitInfotainment_Systemfunktionen_XIX_HCP3_IONode_XIX_PI_Common_XIX_UserInterface_XIX_PI_Disp_XIX_ZR_VA_Communication_Init_Ack_PID
    delegate VehicleComm_HCP3_IONode_XIX_CockpitInfotainment_Systemfunktionen_XIX_HCP3_IONode.SP_IF_ZR_VA_Communication_Init_CID_XIX_VehicleComm_HCP3_IONode_XIX_CockpitInfotainment_Systemfunktionen_XIX_HCP3_IONode <-> outer port SP_IF_ZR_VA_Communication_Init_CID_XIX_HCP3_IONode  # _XIX_VehicleComm_HCP3_IONode_XIX_CockpitInfotainment_Systemfunktionen_XIX_HCP3_IONode_XIX_CI_Common_XIX_UserInterface_XIX_CI_Disp_XIX_ZR_VA_Communication_Init_CID
    delegate VehicleComm_HCP3_IONode_XIX_CockpitInfotainment_Systemfunktionen_XIX_HCP3_IONode.SP_IF_ZR_VA_Communication_Init_FID_XIX_VehicleComm_HCP3_IONode_XIX_CockpitInfotainment_Systemfunktionen_XIX_HCP3_IONode <-> outer port SP_IF_ZR_VA_Communication_Init_FID_XIX_HCP3_IONode  # _XIX_VehicleComm_HCP3_IONode_XIX_CockpitInfotainment_Systemfunktionen_XIX_HCP3_IONode_XIX_FIDAnzeigen_XIX_Fahrerinformation_XIX_Kombi_XIX_ZR_VA_Communication_Init_FID
    delegate VehicleComm_HCP3_IONode_XIX_CockpitInfotainment_Systemfunktionen_XIX_HCP3_IONode.SP_IF_ZR_VA_Communication_Init_PID_XIX_VehicleComm_HCP3_IONode_XIX_CockpitInfotainment_Systemfunktionen_XIX_HCP3_IONode <-> outer port SP_IF_ZR_VA_Communication_Init_PID_XIX_HCP3_IONode  # _XIX_VehicleComm_HCP3_IONode_XIX_CockpitInfotainment_Systemfunktionen_XIX_HCP3_IONode_XIX_PI_Common_XIX_UserInterface_XIX_PI_Disp_XIX_ZR_VA_Communication_Init_PID
    delegate PowerManagement_HCP3_IONode_XIX_CockpitInfotainment_Systemfunktionen_XIX_HCP3_IONode.RP_IF_SG_VDSO_05_XIX_PowerManagement_HCP3_IONode_XIX_CockpitInfotainment_Systemfunktionen_XIX_HCP3_IONode <-> outer port RP_IF_SG_VDSO_05_XIX_HCP3_IONode  # DCon_XIX_VehicleDrivingStateObserver_XIX_AntriebsMom_Regelung_und_Verteilung_XIX_HCP1_XIX_PowerManagement_HCP3_IONode_XIX_CockpitInfotainment_Systemfunktionen_XIX_HCP3_IONode_XIX_SG_VDSO_05
    delegate VehicleComm_HCP3_IONode_XIX_CockpitInfotainment_Systemfunktionen_XIX_HCP3_IONode.RP_IF_VDSO_DKmtg_Auth_XIX_VehicleComm_HCP3_IONode_XIX_CockpitInfotainment_Systemfunktionen_XIX_HCP3_IONode <-> outer port RP_IF_VDSO_DKmtg_Auth_XIX_HCP3_IONode  # _XIX_VehicleDrivingStateObserver_XIX_AntriebsMom_Regelung_und_Verteilung_XIX_HCP1_XIX_VehicleComm_HCP3_IONode_XIX_CockpitInfotainment_Systemfunktionen_XIX_HCP3_IONode_XIX_VDSO_DKmtg_Auth
    delegate VehicleComm_HCP3_IONode_XIX_CockpitInfotainment_Systemfunktionen_XIX_HCP3_IONode.RP_IF_SG_VDSO_05_XIX_VehicleComm_HCP3_IONode_XIX_CockpitInfotainment_Systemfunktionen_XIX_HCP3_IONode <-> outer port RP_IF_SG_VDSO_05_XIX_HCP3_IONode  # DCon_XIX_VehicleDrivingStateObserver_XIX_AntriebsMom_Regelung_und_Verteilung_XIX_HCP1_XIX_VehicleComm_HCP3_IONode_XIX_CockpitInfotainment_Systemfunktionen_XIX_HCP3_IONode_XIX_SG_VDSO_05
    delegate VehicleComm_HCP3_IONode_XIX_CockpitInfotainment_Systemfunktionen_XIX_HCP3_IONode.RP_IF_VDSO_DKmtg_XIX_VehicleComm_HCP3_IONode_XIX_CockpitInfotainment_Systemfunktionen_XIX_HCP3_IONode <-> outer port RP_IF_VDSO_DKmtg_XIX_HCP3_IONode  # _XIX_VehicleDrivingStateObserver_XIX_AntriebsMom_Regelung_und_Verteilung_XIX_HCP1_XIX_VehicleComm_HCP3_IONode_XIX_CockpitInfotainment_Systemfunktionen_XIX_HCP3_IONode_XIX_VDSO_DKmtg
    delegate diagnosis_infrastructure_Info_El_XIX_diagnosis_infrastructure_XIX_HCP3_IONode.RP_IF_SG_VDSO_05_XIX_diagnosis_infrastructure_Info_El_XIX_diagnosis_infrastructure_XIX_HCP3_IONode <-> outer port RP_IF_SG_VDSO_05_XIX_HCP3_IONode  # DCon_XIX_VehicleDrivingStateObserver_XIX_AntriebsMom_Regelung_und_Verteilung_XIX_HCP1_XIX_diagnosis_infrastructure_Info_El_XIX_diagnosis_infrastructure_XIX_HCP3_IONode_XIX_SG_VDSO_05
    delegate VehicleComm_HCP3_IONode_XIX_CockpitInfotainment_Systemfunktionen_XIX_HCP3_IONode.RP_IF_WLC1_UsedChargingStandard_XIX_VehicleComm_HCP3_IONode_XIX_CockpitInfotainment_Systemfunktionen_XIX_HCP3_IONode <-> outer port RP_IF_WLC1_UsedChargingStandard_XIX_HCP3_IONode  # _XIX_WirelessChargerFront_XIX_WirelessCharge_XIX_WLC_01_XIX_VehicleComm_HCP3_IONode_XIX_CockpitInfotainment_Systemfunktionen_XIX_HCP3_IONode_XIX_WLC1_UsedChargingStandard
    delegate VehicleComm_HCP3_IONode_XIX_CockpitInfotainment_Systemfunktionen_XIX_HCP3_IONode.RP_IF_WLC1_ChargingStatus_XIX_VehicleComm_HCP3_IONode_XIX_CockpitInfotainment_Systemfunktionen_XIX_HCP3_IONode <-> outer port RP_IF_WLC1_ChargingStatus_XIX_HCP3_IONode  # _XIX_WirelessChargerFront_XIX_WirelessCharge_XIX_WLC_01_XIX_VehicleComm_HCP3_IONode_XIX_CockpitInfotainment_Systemfunktionen_XIX_HCP3_IONode_XIX_WLC1_ChargingStatus
    delegate VehicleComm_HCP3_IONode_XIX_CockpitInfotainment_Systemfunktionen_XIX_HCP3_IONode.RP_IF_WLC1_ChargingEfficiency_XIX_VehicleComm_HCP3_IONode_XIX_CockpitInfotainment_Systemfunktionen_XIX_HCP3_IONode <-> outer port RP_IF_WLC1_ChargingEfficiency_XIX_HCP3_IONode  # _XIX_WirelessChargerFront_XIX_WirelessCharge_XIX_WLC_01_XIX_VehicleComm_HCP3_IONode_XIX_CockpitInfotainment_Systemfunktionen_XIX_HCP3_IONode_XIX_WLC1_ChargingEfficiency
    delegate VehicleComm_HCP3_IONode_XIX_CockpitInfotainment_Systemfunktionen_XIX_HCP3_IONode.RP_IF_WLC2_ChargingStatus_XIX_VehicleComm_HCP3_IONode_XIX_CockpitInfotainment_Systemfunktionen_XIX_HCP3_IONode <-> outer port RP_IF_WLC2_ChargingStatus_XIX_HCP3_IONode  # _XIX_WirelessChargerRear_XIX_WirelessCharge_XIX_WLC_02_XIX_VehicleComm_HCP3_IONode_XIX_CockpitInfotainment_Systemfunktionen_XIX_HCP3_IONode_XIX_WLC2_ChargingStatus
    delegate VehicleComm_HCP3_IONode_XIX_CockpitInfotainment_Systemfunktionen_XIX_HCP3_IONode.RP_IF_WLC2_UsedChargingStandard_XIX_VehicleComm_HCP3_IONode_XIX_CockpitInfotainment_Systemfunktionen_XIX_HCP3_IONode <-> outer port RP_IF_WLC2_UsedChargingStandard_XIX_HCP3_IONode  # _XIX_WirelessChargerRear_XIX_WirelessCharge_XIX_WLC_02_XIX_VehicleComm_HCP3_IONode_XIX_CockpitInfotainment_Systemfunktionen_XIX_HCP3_IONode_XIX_WLC2_UsedChargingStandard
    delegate VehicleComm_HCP3_IONode_XIX_CockpitInfotainment_Systemfunktionen_XIX_HCP3_IONode.RP_IF_WLC2_ChargingEfficiency_XIX_VehicleComm_HCP3_IONode_XIX_CockpitInfotainment_Systemfunktionen_XIX_HCP3_IONode <-> outer port RP_IF_WLC2_ChargingEfficiency_XIX_HCP3_IONode  # _XIX_WirelessChargerRear_XIX_WirelessCharge_XIX_WLC_02_XIX_VehicleComm_HCP3_IONode_XIX_CockpitInfotainment_Systemfunktionen_XIX_HCP3_IONode_XIX_WLC2_ChargingEfficiency
    delegate diagnosis_infrastructure_Info_El_XIX_diagnosis_infrastructure_XIX_HCP3_IONode.RP_IF_KN_AMP_DiagPfad_V12_XIX_diagnosis_infrastructure_Info_El_XIX_diagnosis_infrastructure_XIX_HCP3_IONode <-> outer port RP_IF_KN_AMP_DiagPfad_V12_XIX_HCP3_IONode  # _XIX_diagnosis_infrastructure_AMP_XIX_diagnosis_infrastructure_XIX_DSP_XIX_diagnosis_infrastructure_Info_El_XIX_diagnosis_infrastructure_XIX_HCP3_IONode_XIX_KN_AMP_DiagPfad_V12
    delegate diagnosis_infrastructure_Info_El_XIX_diagnosis_infrastructure_XIX_HCP3_IONode.RP_IF_AMP_SNI_10_XIX_diagnosis_infrastructure_Info_El_XIX_diagnosis_infrastructure_XIX_HCP3_IONode <-> outer port RP_IF_AMP_SNI_10_XIX_HCP3_IONode  # _XIX_diagnosis_infrastructure_AMP_XIX_diagnosis_infrastructure_XIX_DSP_XIX_diagnosis_infrastructure_Info_El_XIX_diagnosis_infrastructure_XIX_HCP3_IONode_XIX_AMP_SNI_10
    delegate diagnosis_infrastructure_Info_El_XIX_diagnosis_infrastructure_XIX_HCP3_IONode.RP_IF_AMP_KD_Fehler_XIX_diagnosis_infrastructure_Info_El_XIX_diagnosis_infrastructure_XIX_HCP3_IONode <-> outer port RP_IF_AMP_KD_Fehler_XIX_HCP3_IONode  # _XIX_diagnosis_infrastructure_AMP_XIX_diagnosis_infrastructure_XIX_DSP_XIX_diagnosis_infrastructure_Info_El_XIX_diagnosis_infrastructure_XIX_HCP3_IONode_XIX_AMP_KD_Fehler
    delegate diagnosis_infrastructure_Info_El_XIX_diagnosis_infrastructure_XIX_HCP3_IONode.RP_IF_KN_CCF_DiagPfad_V12_XIX_diagnosis_infrastructure_Info_El_XIX_diagnosis_infrastructure_XIX_HCP3_IONode <-> outer port RP_IF_KN_CCF_DiagPfad_V12_XIX_HCP3_IONode  # _XIX_diagnosis_infrastructure_CCF_XIX_diagnosis_infrastructure_XIX_BKE_XIX_diagnosis_infrastructure_Info_El_XIX_diagnosis_infrastructure_XIX_HCP3_IONode_XIX_KN_CCF_DiagPfad_V12
    delegate diagnosis_infrastructure_Info_El_XIX_diagnosis_infrastructure_XIX_HCP3_IONode.RP_IF_CCF_KD_Fehler_XIX_diagnosis_infrastructure_Info_El_XIX_diagnosis_infrastructure_XIX_HCP3_IONode <-> outer port RP_IF_CCF_KD_Fehler_XIX_HCP3_IONode  # _XIX_diagnosis_infrastructure_CCF_XIX_diagnosis_infrastructure_XIX_BKE_XIX_diagnosis_infrastructure_Info_El_XIX_diagnosis_infrastructure_XIX_HCP3_IONode_XIX_CCF_KD_Fehler
    delegate diagnosis_infrastructure_Info_El_XIX_diagnosis_infrastructure_XIX_HCP3_IONode.RP_IF_CCF_SNI_10_XIX_diagnosis_infrastructure_Info_El_XIX_diagnosis_infrastructure_XIX_HCP3_IONode <-> outer port RP_IF_CCF_SNI_10_XIX_HCP3_IONode  # _XIX_diagnosis_infrastructure_CCF_XIX_diagnosis_infrastructure_XIX_BKE_XIX_diagnosis_infrastructure_Info_El_XIX_diagnosis_infrastructure_XIX_HCP3_IONode_XIX_CCF_SNI_10
    delegate diagnosis_infrastructure_Info_El_XIX_diagnosis_infrastructure_XIX_HCP3_IONode.RP_IF_CID_KD_Fehler_XIX_diagnosis_infrastructure_Info_El_XIX_diagnosis_infrastructure_XIX_HCP3_IONode <-> outer port RP_IF_CID_KD_Fehler_XIX_HCP3_IONode  # _XIX_diagnosis_infrastructure_CID_XIX_diagnosis_infrastructure_XIX_CI_Disp_XIX_diagnosis_infrastructure_Info_El_XIX_diagnosis_infrastructure_XIX_HCP3_IONode_XIX_CID_KD_Fehler
    delegate diagnosis_infrastructure_Info_El_XIX_diagnosis_infrastructure_XIX_HCP3_IONode.RP_IF_CID_SNI_10_XIX_diagnosis_infrastructure_Info_El_XIX_diagnosis_infrastructure_XIX_HCP3_IONode <-> outer port RP_IF_CID_SNI_10_XIX_HCP3_IONode  # _XIX_diagnosis_infrastructure_CID_XIX_diagnosis_infrastructure_XIX_CI_Disp_XIX_diagnosis_infrastructure_Info_El_XIX_diagnosis_infrastructure_XIX_HCP3_IONode_XIX_CID_SNI_10
    delegate diagnosis_infrastructure_Info_El_XIX_diagnosis_infrastructure_XIX_HCP3_IONode.RP_IF_KN_CID_DiagPfad_V12_XIX_diagnosis_infrastructure_Info_El_XIX_diagnosis_infrastructure_XIX_HCP3_IONode <-> outer port RP_IF_KN_CID_DiagPfad_V12_XIX_HCP3_IONode  # _XIX_diagnosis_infrastructure_CID_XIX_diagnosis_infrastructure_XIX_CI_Disp_XIX_diagnosis_infrastructure_Info_El_XIX_diagnosis_infrastructure_XIX_HCP3_IONode_XIX_KN_CID_DiagPfad_V12
    delegate diagnosis_infrastructure_Info_El_XIX_diagnosis_infrastructure_XIX_HCP3_IONode.RP_IF_KN_DispKBI_FS_DiagPfad_V12_XIX_diagnosis_infrastructure_Info_El_XIX_diagnosis_infrastructure_XIX_HCP3_IONode <-> outer port RP_IF_KN_DispKBI_FS_DiagPfad_V12_XIX_HCP3_IONode  # _XIX_diagnosis_infrastructure_DispKBI_FS_XIX_diagnosis_infrastructure_XIX_Main_Disp_XIX_diagnosis_infrastructure_Info_El_XIX_diagnosis_infrastructure_XIX_HCP3_IONode_XIX_KN_DispKBI_FS_DiagPfad_V12
    delegate diagnosis_infrastructure_Info_El_XIX_diagnosis_infrastructure_XIX_HCP3_IONode.RP_IF_DispKBI_FS_SNI_10_XIX_diagnosis_infrastructure_Info_El_XIX_diagnosis_infrastructure_XIX_HCP3_IONode <-> outer port RP_IF_DispKBI_FS_SNI_10_XIX_HCP3_IONode  # _XIX_diagnosis_infrastructure_DispKBI_FS_XIX_diagnosis_infrastructure_XIX_Main_Disp_XIX_diagnosis_infrastructure_Info_El_XIX_diagnosis_infrastructure_XIX_HCP3_IONode_XIX_DispKBI_FS_SNI_10
    delegate diagnosis_infrastructure_Info_El_XIX_diagnosis_infrastructure_XIX_HCP3_IONode.RP_IF_DispKBI_FS_KD_Fehler_XIX_diagnosis_infrastructure_Info_El_XIX_diagnosis_infrastructure_XIX_HCP3_IONode <-> outer port RP_IF_DispKBI_FS_KD_Fehler_XIX_HCP3_IONode  # _XIX_diagnosis_infrastructure_DispKBI_FS_XIX_diagnosis_infrastructure_XIX_Main_Disp_XIX_diagnosis_infrastructure_Info_El_XIX_diagnosis_infrastructure_XIX_HCP3_IONode_XIX_DispKBI_FS_KD_Fehler
    delegate diagnosis_infrastructure_Info_El_XIX_diagnosis_infrastructure_XIX_HCP3_IONode.RP_IF_HCP3Sys03_KD_Fehler_XIX_diagnosis_infrastructure_Info_El_XIX_diagnosis_infrastructure_XIX_HCP3_IONode <-> outer port RP_IF_HCP3Sys03_KD_Fehler_XIX_HCP3_IONode  # _XIX_diagnosis_infrastructure_HCP3Sys03_XIX_diagnosis_infrastructure_XIX_HCP3_CN1_IVIPartition_XIX_diagnosis_infrastructure_Info_El_XIX_diagnosis_infrastructure_XIX_HCP3_IONode_XIX_HCP3Sys03_KD_Fehler
    delegate diagnosis_infrastructure_Info_El_XIX_diagnosis_infrastructure_XIX_HCP3_IONode.RP_IF_KN_HCP3Sys03_DiagPfad_V12_XIX_diagnosis_infrastructure_Info_El_XIX_diagnosis_infrastructure_XIX_HCP3_IONode <-> outer port RP_IF_KN_HCP3Sys03_DiagPfad_V12_XIX_HCP3_IONode  # _XIX_diagnosis_infrastructure_HCP3Sys03_XIX_diagnosis_infrastructure_XIX_HCP3_CN1_IVIPartition_XIX_diagnosis_infrastructure_Info_El_XIX_diagnosis_infrastructure_XIX_HCP3_IONode_XIX_KN_HCP3Sys03_DiagPfad_V12
    delegate diagnosis_infrastructure_Info_El_XIX_diagnosis_infrastructure_XIX_HCP3_IONode.RP_IF_HCP3Sys03_SNI_10_XIX_diagnosis_infrastructure_Info_El_XIX_diagnosis_infrastructure_XIX_HCP3_IONode <-> outer port RP_IF_HCP3Sys03_SNI_10_XIX_HCP3_IONode  # _XIX_diagnosis_infrastructure_HCP3Sys03_XIX_diagnosis_infrastructure_XIX_HCP3_CN1_IVIPartition_XIX_diagnosis_infrastructure_Info_El_XIX_diagnosis_infrastructure_XIX_HCP3_IONode_XIX_HCP3Sys03_SNI_10
    delegate diagnosis_infrastructure_Info_El_XIX_diagnosis_infrastructure_XIX_HCP3_IONode.RP_IF_HUD_KD_Fehler_XIX_diagnosis_infrastructure_Info_El_XIX_diagnosis_infrastructure_XIX_HCP3_IONode <-> outer port RP_IF_HUD_KD_Fehler_XIX_HCP3_IONode  # _XIX_diagnosis_infrastructure_HUD_XIX_diagnosis_infrastructure_XIX_AR_HUD_XIX_diagnosis_infrastructure_Info_El_XIX_diagnosis_infrastructure_XIX_HCP3_IONode_XIX_HUD_KD_Fehler
    delegate diagnosis_infrastructure_Info_El_XIX_diagnosis_infrastructure_XIX_HCP3_IONode.RP_IF_HUD_SNI_10_XIX_diagnosis_infrastructure_Info_El_XIX_diagnosis_infrastructure_XIX_HCP3_IONode <-> outer port RP_IF_HUD_SNI_10_XIX_HCP3_IONode  # _XIX_diagnosis_infrastructure_HUD_XIX_diagnosis_infrastructure_XIX_AR_HUD_XIX_diagnosis_infrastructure_Info_El_XIX_diagnosis_infrastructure_XIX_HCP3_IONode_XIX_HUD_SNI_10
    delegate diagnosis_infrastructure_Info_El_XIX_diagnosis_infrastructure_XIX_HCP3_IONode.RP_IF_KN_HUD_DiagPfad_V12_XIX_diagnosis_infrastructure_Info_El_XIX_diagnosis_infrastructure_XIX_HCP3_IONode <-> outer port RP_IF_KN_HUD_DiagPfad_V12_XIX_HCP3_IONode  # _XIX_diagnosis_infrastructure_HUD_XIX_diagnosis_infrastructure_XIX_AR_HUD_XIX_diagnosis_infrastructure_Info_El_XIX_diagnosis_infrastructure_XIX_HCP3_IONode_XIX_KN_HUD_DiagPfad_V12
    delegate diagnosis_infrastructure_Info_El_XIX_diagnosis_infrastructure_XIX_HCP3_IONode.RP_IF_ICAS3Sys01_KD_Fehler_XIX_diagnosis_infrastructure_Info_El_XIX_diagnosis_infrastructure_XIX_HCP3_IONode <-> outer port RP_IF_ICAS3Sys01_KD_Fehler_XIX_HCP3_IONode  # _XIX_diagnosis_infrastructure_ICAS3Sys01_XIX_diagnosis_infrastructure_XIX_HCP3_CN1_Systempartition_XIX_diagnosis_infrastructure_Info_El_XIX_diagnosis_infrastructure_XIX_HCP3_IONode_XIX_ICAS3Sys01_KD_Fehler
    delegate diagnosis_infrastructure_Info_El_XIX_diagnosis_infrastructure_XIX_HCP3_IONode.RP_IF_KN_ICAS3Sys01_DiagPfad_V12_XIX_diagnosis_infrastructure_Info_El_XIX_diagnosis_infrastructure_XIX_HCP3_IONode <-> outer port RP_IF_KN_ICAS3Sys01_DiagPfad_V12_XIX_HCP3_IONode  # _XIX_diagnosis_infrastructure_ICAS3Sys01_XIX_diagnosis_infrastructure_XIX_HCP3_CN1_Systempartition_XIX_diagnosis_infrastructure_Info_El_XIX_diagnosis_infrastructure_XIX_HCP3_IONode_XIX_KN_ICAS3Sys01_DiagPfad_V12
    delegate diagnosis_infrastructure_Info_El_XIX_diagnosis_infrastructure_XIX_HCP3_IONode.RP_IF_ICAS3Sys01_SNI_10_XIX_diagnosis_infrastructure_Info_El_XIX_diagnosis_infrastructure_XIX_HCP3_IONode <-> outer port RP_IF_ICAS3Sys01_SNI_10_XIX_HCP3_IONode  # _XIX_diagnosis_infrastructure_ICAS3Sys01_XIX_diagnosis_infrastructure_XIX_HCP3_CN1_Systempartition_XIX_diagnosis_infrastructure_Info_El_XIX_diagnosis_infrastructure_XIX_HCP3_IONode_XIX_ICAS3Sys01_SNI_10
    delegate diagnosis_infrastructure_Info_El_XIX_diagnosis_infrastructure_XIX_HCP3_IONode.SP_IF_DS_Info_El_ConfDTCChanged_XIX_diagnosis_infrastructure_Info_El_XIX_diagnosis_infrastructure_XIX_HCP3_IONode <-> outer port SP_IF_DS_Info_El_ConfDTCChanged_XIX_HCP3_IONode  # _XIX_diagnosis_infrastructure_Info_El_XIX_diagnosis_infrastructure_XIX_HCP3_IONode_XIX_Kommunikationsserver_HCP5_Generierung_XIX_ComServ_XIX_HCP5_P4_E3SWPAC_XIX_DS_Info_El_ConfDTCChanged
    delegate diagnosis_infrastructure_Info_El_XIX_diagnosis_infrastructure_XIX_HCP3_IONode.SP_IF_DS_Info_El_DiagAdr_XIX_diagnosis_infrastructure_Info_El_XIX_diagnosis_infrastructure_XIX_HCP3_IONode <-> outer port SP_IF_DS_Info_El_DiagAdr_XIX_HCP3_IONode  # _XIX_diagnosis_infrastructure_Info_El_XIX_diagnosis_infrastructure_XIX_HCP3_IONode_XIX_Kommunikationsserver_HCP5_Generierung_XIX_ComServ_XIX_HCP5_P4_E3SWPAC_XIX_DS_Info_El_DiagAdr
    delegate diagnosis_infrastructure_Info_El_XIX_diagnosis_infrastructure_XIX_HCP3_IONode.SP_IF_DS_Info_El_IdentValid_XIX_diagnosis_infrastructure_Info_El_XIX_diagnosis_infrastructure_XIX_HCP3_IONode <-> outer port SP_IF_DS_Info_El_IdentValid_XIX_HCP3_IONode  # _XIX_diagnosis_infrastructure_Info_El_XIX_diagnosis_infrastructure_XIX_HCP3_IONode_XIX_Kommunikationsserver_HCP5_Generierung_XIX_ComServ_XIX_HCP5_P4_E3SWPAC_XIX_DS_Info_El_IdentValid
    delegate diagnosis_infrastructure_Info_El_XIX_diagnosis_infrastructure_XIX_HCP3_IONode.SP_IF_DS_Info_El_MemSel10Changed_XIX_diagnosis_infrastructure_Info_El_XIX_diagnosis_infrastructure_XIX_HCP3_IONode <-> outer port SP_IF_DS_Info_El_MemSel10Changed_XIX_HCP3_IONode  # _XIX_diagnosis_infrastructure_Info_El_XIX_diagnosis_infrastructure_XIX_HCP3_IONode_XIX_Kommunikationsserver_HCP5_Generierung_XIX_ComServ_XIX_HCP5_P4_E3SWPAC_XIX_DS_Info_El_MemSel10Changed
    delegate diagnosis_infrastructure_Info_El_XIX_diagnosis_infrastructure_XIX_HCP3_IONode.SP_IF_DS_Info_El_MemSelChanged_XIX_diagnosis_infrastructure_Info_El_XIX_diagnosis_infrastructure_XIX_HCP3_IONode <-> outer port SP_IF_DS_Info_El_MemSelChanged_XIX_HCP3_IONode  # _XIX_diagnosis_infrastructure_Info_El_XIX_diagnosis_infrastructure_XIX_HCP3_IONode_XIX_Kommunikationsserver_HCP5_Generierung_XIX_ComServ_XIX_HCP5_P4_E3SWPAC_XIX_DS_Info_El_MemSelChanged
    delegate diagnosis_infrastructure_Info_El_XIX_diagnosis_infrastructure_XIX_HCP3_IONode.SP_IF_DS_Info_El_StMemChanged_XIX_diagnosis_infrastructure_Info_El_XIX_diagnosis_infrastructure_XIX_HCP3_IONode <-> outer port SP_IF_DS_Info_El_StMemChanged_XIX_HCP3_IONode  # _XIX_diagnosis_infrastructure_Info_El_XIX_diagnosis_infrastructure_XIX_HCP3_IONode_XIX_Kommunikationsserver_HCP5_Generierung_XIX_ComServ_XIX_HCP5_P4_E3SWPAC_XIX_DS_Info_El_StMemChanged
    delegate diagnosis_infrastructure_Info_El_XIX_diagnosis_infrastructure_XIX_HCP3_IONode.SP_IF_DS_Info_El_TestFailedChanged_XIX_diagnosis_infrastructure_Info_El_XIX_diagnosis_infrastructure_XIX_HCP3_IONode <-> outer port SP_IF_DS_Info_El_TestFailedChanged_XIX_HCP3_IONode  # _XIX_diagnosis_infrastructure_Info_El_XIX_diagnosis_infrastructure_XIX_HCP3_IONode_XIX_Kommunikationsserver_HCP5_Generierung_XIX_ComServ_XIX_HCP5_P4_E3SWPAC_XIX_DS_Info_El_TestFailedChanged
    delegate diagnosis_infrastructure_Info_El_XIX_diagnosis_infrastructure_XIX_HCP3_IONode.SP_IF_DS_Info_El_WIRChanged_XIX_diagnosis_infrastructure_Info_El_XIX_diagnosis_infrastructure_XIX_HCP3_IONode <-> outer port SP_IF_DS_Info_El_WIRChanged_XIX_HCP3_IONode  # _XIX_diagnosis_infrastructure_Info_El_XIX_diagnosis_infrastructure_XIX_HCP3_IONode_XIX_Kommunikationsserver_HCP5_Generierung_XIX_ComServ_XIX_HCP5_P4_E3SWPAC_XIX_DS_Info_El_WIRChanged
    delegate diagnosis_infrastructure_Info_El_XIX_diagnosis_infrastructure_XIX_HCP3_IONode.SP_IF_Info_El_KD_Fehler_XIX_diagnosis_infrastructure_Info_El_XIX_diagnosis_infrastructure_XIX_HCP3_IONode <-> outer port SP_IF_Info_El_KD_Fehler_XIX_HCP3_IONode  # _XIX_diagnosis_infrastructure_Info_El_XIX_diagnosis_infrastructure_XIX_HCP3_IONode_XIX_diagnosis_infrastructure_Gateway_XIX_diagnosis_infrastructure_XIX_HCP5_P1_Gateway_XIX_Info_El_KD_Fehler
    delegate diagnosis_infrastructure_Info_El_XIX_diagnosis_infrastructure_XIX_HCP3_IONode.SP_IF_Info_El_SNI_10_XIX_diagnosis_infrastructure_Info_El_XIX_diagnosis_infrastructure_XIX_HCP3_IONode <-> outer port SP_IF_Info_El_SNI_10_XIX_HCP3_IONode  # _XIX_diagnosis_infrastructure_Info_El_XIX_diagnosis_infrastructure_XIX_HCP3_IONode_XIX_diagnosis_infrastructure_Gateway_XIX_diagnosis_infrastructure_XIX_HCP5_P1_Gateway_XIX_Info_El_SNI_10
    delegate diagnosis_infrastructure_Info_El_XIX_diagnosis_infrastructure_XIX_HCP3_IONode.SP_IF_KN_Info_El_DiagPfad_V12_XIX_diagnosis_infrastructure_Info_El_XIX_diagnosis_infrastructure_XIX_HCP3_IONode <-> outer port SP_IF_KN_Info_El_DiagPfad_V12_XIX_HCP3_IONode  # _XIX_diagnosis_infrastructure_Info_El_XIX_diagnosis_infrastructure_XIX_HCP3_IONode_XIX_diagnosis_infrastructure_Gateway_XIX_diagnosis_infrastructure_XIX_HCP5_P1_Gateway_XIX_KN_Info_El_DiagPfad_V12
    delegate diagnosis_infrastructure_Info_El_XIX_diagnosis_infrastructure_XIX_HCP3_IONode.RP_IF_PID_SNI_10_XIX_diagnosis_infrastructure_Info_El_XIX_diagnosis_infrastructure_XIX_HCP3_IONode <-> outer port RP_IF_PID_SNI_10_XIX_HCP3_IONode  # _XIX_diagnosis_infrastructure_PID_XIX_diagnosis_infrastructure_XIX_PI_Disp_XIX_diagnosis_infrastructure_Info_El_XIX_diagnosis_infrastructure_XIX_HCP3_IONode_XIX_PID_SNI_10
    delegate diagnosis_infrastructure_Info_El_XIX_diagnosis_infrastructure_XIX_HCP3_IONode.RP_IF_KN_PID_DiagPfad_V12_XIX_diagnosis_infrastructure_Info_El_XIX_diagnosis_infrastructure_XIX_HCP3_IONode <-> outer port RP_IF_KN_PID_DiagPfad_V12_XIX_HCP3_IONode  # _XIX_diagnosis_infrastructure_PID_XIX_diagnosis_infrastructure_XIX_PI_Disp_XIX_diagnosis_infrastructure_Info_El_XIX_diagnosis_infrastructure_XIX_HCP3_IONode_XIX_KN_PID_DiagPfad_V12
    delegate diagnosis_infrastructure_Info_El_XIX_diagnosis_infrastructure_XIX_HCP3_IONode.RP_IF_PID_KD_Fehler_XIX_diagnosis_infrastructure_Info_El_XIX_diagnosis_infrastructure_XIX_HCP3_IONode <-> outer port RP_IF_PID_KD_Fehler_XIX_HCP3_IONode  # _XIX_diagnosis_infrastructure_PID_XIX_diagnosis_infrastructure_XIX_PI_Disp_XIX_diagnosis_infrastructure_Info_El_XIX_diagnosis_infrastructure_XIX_HCP3_IONode_XIX_PID_KD_Fehler
    delegate Infrastructure_Info_El_XIX_network_infrastructure_XIX_HCP3_IONode.RP_IF_SI_NWDF_XIX_Infrastructure_Info_El_XIX_network_infrastructure_XIX_HCP3_IONode <-> outer port RP_IF_SI_NWDF_XIX_HCP3_IONode  # _XIX_diagnosis_infrastructure_SGW04_XIX_diagnosis_infrastructure_XIX_HCP5_P2_OBD_Safety_XIX_Infrastructure_Info_El_XIX_network_infrastructure_XIX_HCP3_IONode_XIX_SI_NWDF
    delegate Infrastructure_Info_El_XIX_network_infrastructure_XIX_HCP3_IONode.RP_IF_SI_NWDF_30_XIX_Infrastructure_Info_El_XIX_network_infrastructure_XIX_HCP3_IONode <-> outer port RP_IF_SI_NWDF_30_XIX_HCP3_IONode  # _XIX_diagnosis_infrastructure_SGW04_XIX_diagnosis_infrastructure_XIX_HCP5_P2_OBD_Safety_XIX_Infrastructure_Info_El_XIX_network_infrastructure_XIX_HCP3_IONode_XIX_SI_NWDF_30
    delegate PowerManagement_HCP3_IONode_XIX_CockpitInfotainment_Systemfunktionen_XIX_HCP3_IONode.RP_IF_SI_NWDF_gueltig_XIX_PowerManagement_HCP3_IONode_XIX_CockpitInfotainment_Systemfunktionen_XIX_HCP3_IONode <-> outer port RP_IF_SI_NWDF_gueltig_XIX_HCP3_IONode  # _XIX_diagnosis_infrastructure_SGW04_XIX_diagnosis_infrastructure_XIX_HCP5_P2_OBD_Safety_XIX_PowerManagement_HCP3_IONode_XIX_CockpitInfotainment_Systemfunktionen_XIX_HCP3_IONode_XIX_SI_NWDF_gueltig
    delegate PowerManagement_HCP3_IONode_XIX_CockpitInfotainment_Systemfunktionen_XIX_HCP3_IONode.RP_IF_SI_NWDF_XIX_PowerManagement_HCP3_IONode_XIX_CockpitInfotainment_Systemfunktionen_XIX_HCP3_IONode <-> outer port RP_IF_SI_NWDF_XIX_HCP3_IONode  # _XIX_diagnosis_infrastructure_SGW04_XIX_diagnosis_infrastructure_XIX_HCP5_P2_OBD_Safety_XIX_PowerManagement_HCP3_IONode_XIX_CockpitInfotainment_Systemfunktionen_XIX_HCP3_IONode_XIX_SI_NWDF
    delegate PowerManagement_HCP3_IONode_XIX_CockpitInfotainment_Systemfunktionen_XIX_HCP3_IONode.RP_IF_SI_T_Schutz_XIX_PowerManagement_HCP3_IONode_XIX_CockpitInfotainment_Systemfunktionen_XIX_HCP3_IONode <-> outer port RP_IF_SI_T_Schutz_XIX_HCP3_IONode  # _XIX_diagnosis_infrastructure_SGW04_XIX_diagnosis_infrastructure_XIX_HCP5_P2_OBD_Safety_XIX_PowerManagement_HCP3_IONode_XIX_CockpitInfotainment_Systemfunktionen_XIX_HCP3_IONode_XIX_SI_T_Schutz
    delegate PowerManagement_HCP3_IONode_XIX_CockpitInfotainment_Systemfunktionen_XIX_HCP3_IONode.RP_IF_SI_T_Mode_XIX_PowerManagement_HCP3_IONode_XIX_CockpitInfotainment_Systemfunktionen_XIX_HCP3_IONode <-> outer port RP_IF_SI_T_Mode_XIX_HCP3_IONode  # _XIX_diagnosis_infrastructure_SGW04_XIX_diagnosis_infrastructure_XIX_HCP5_P2_OBD_Safety_XIX_PowerManagement_HCP3_IONode_XIX_CockpitInfotainment_Systemfunktionen_XIX_HCP3_IONode_XIX_SI_T_Mode
    delegate PowerManagement_HCP3_IONode_XIX_CockpitInfotainment_Systemfunktionen_XIX_HCP3_IONode.RP_IF_SI_QRS_Mode_XIX_PowerManagement_HCP3_IONode_XIX_CockpitInfotainment_Systemfunktionen_XIX_HCP3_IONode <-> outer port RP_IF_SI_QRS_Mode_XIX_HCP3_IONode  # _XIX_diagnosis_infrastructure_SGW04_XIX_diagnosis_infrastructure_XIX_HCP5_P2_OBD_Safety_XIX_PowerManagement_HCP3_IONode_XIX_CockpitInfotainment_Systemfunktionen_XIX_HCP3_IONode_XIX_SI_QRS_Mode
    delegate PowerManagement_HCP3_IONode_XIX_CockpitInfotainment_Systemfunktionen_XIX_HCP3_IONode.RP_IF_SI_NWDF_30_XIX_PowerManagement_HCP3_IONode_XIX_CockpitInfotainment_Systemfunktionen_XIX_HCP3_IONode <-> outer port RP_IF_SI_NWDF_30_XIX_HCP3_IONode  # _XIX_diagnosis_infrastructure_SGW04_XIX_diagnosis_infrastructure_XIX_HCP5_P2_OBD_Safety_XIX_PowerManagement_HCP3_IONode_XIX_CockpitInfotainment_Systemfunktionen_XIX_HCP3_IONode_XIX_SI_NWDF_30
    delegate VehicleComm_HCP3_IONode_XIX_CockpitInfotainment_Systemfunktionen_XIX_HCP3_IONode.RP_IF_SI_P_Mode_XIX_VehicleComm_HCP3_IONode_XIX_CockpitInfotainment_Systemfunktionen_XIX_HCP3_IONode <-> outer port RP_IF_SI_P_Mode_XIX_HCP3_IONode  # _XIX_diagnosis_infrastructure_SGW04_XIX_diagnosis_infrastructure_XIX_HCP5_P2_OBD_Safety_XIX_VehicleComm_HCP3_IONode_XIX_CockpitInfotainment_Systemfunktionen_XIX_HCP3_IONode_XIX_SI_P_Mode
    delegate VehicleComm_HCP3_IONode_XIX_CockpitInfotainment_Systemfunktionen_XIX_HCP3_IONode.RP_IF_SI_P_Mode_gueltig_XIX_VehicleComm_HCP3_IONode_XIX_CockpitInfotainment_Systemfunktionen_XIX_HCP3_IONode <-> outer port RP_IF_SI_P_Mode_gueltig_XIX_HCP3_IONode  # _XIX_diagnosis_infrastructure_SGW04_XIX_diagnosis_infrastructure_XIX_HCP5_P2_OBD_Safety_XIX_VehicleComm_HCP3_IONode_XIX_CockpitInfotainment_Systemfunktionen_XIX_HCP3_IONode_XIX_SI_P_Mode_gueltig
    delegate diagnosis_infrastructure_Info_El_XIX_diagnosis_infrastructure_XIX_HCP3_IONode.RP_IF_SI_P_Mode_XIX_diagnosis_infrastructure_Info_El_XIX_diagnosis_infrastructure_XIX_HCP3_IONode <-> outer port RP_IF_SI_P_Mode_XIX_HCP3_IONode  # _XIX_diagnosis_infrastructure_SGW04_XIX_diagnosis_infrastructure_XIX_HCP5_P2_OBD_Safety_XIX_diagnosis_infrastructure_Info_El_XIX_diagnosis_infrastructure_XIX_HCP3_IONode_XIX_SI_P_Mode
    delegate diagnosis_infrastructure_Info_El_XIX_diagnosis_infrastructure_XIX_HCP3_IONode.RP_IF_SI_NWDF_gueltig_XIX_diagnosis_infrastructure_Info_El_XIX_diagnosis_infrastructure_XIX_HCP3_IONode <-> outer port RP_IF_SI_NWDF_gueltig_XIX_HCP3_IONode  # _XIX_diagnosis_infrastructure_SGW04_XIX_diagnosis_infrastructure_XIX_HCP5_P2_OBD_Safety_XIX_diagnosis_infrastructure_Info_El_XIX_diagnosis_infrastructure_XIX_HCP3_IONode_XIX_SI_NWDF_gueltig
    delegate diagnosis_infrastructure_Info_El_XIX_diagnosis_infrastructure_XIX_HCP3_IONode.RP_IF_SI_P_Mode_gueltig_XIX_diagnosis_infrastructure_Info_El_XIX_diagnosis_infrastructure_XIX_HCP3_IONode <-> outer port RP_IF_SI_P_Mode_gueltig_XIX_HCP3_IONode  # _XIX_diagnosis_infrastructure_SGW04_XIX_diagnosis_infrastructure_XIX_HCP5_P2_OBD_Safety_XIX_diagnosis_infrastructure_Info_El_XIX_diagnosis_infrastructure_XIX_HCP3_IONode_XIX_SI_P_Mode_gueltig
    delegate diagnosis_infrastructure_Info_El_XIX_diagnosis_infrastructure_XIX_HCP3_IONode.RP_IF_SI_NWDF_30_XIX_diagnosis_infrastructure_Info_El_XIX_diagnosis_infrastructure_XIX_HCP3_IONode <-> outer port RP_IF_SI_NWDF_30_XIX_HCP3_IONode  # _XIX_diagnosis_infrastructure_SGW04_XIX_diagnosis_infrastructure_XIX_HCP5_P2_OBD_Safety_XIX_diagnosis_infrastructure_Info_El_XIX_diagnosis_infrastructure_XIX_HCP3_IONode_XIX_SI_NWDF_30
    delegate diagnosis_infrastructure_Info_El_XIX_diagnosis_infrastructure_XIX_HCP3_IONode.RP_IF_SI_NWDF_XIX_diagnosis_infrastructure_Info_El_XIX_diagnosis_infrastructure_XIX_HCP3_IONode <-> outer port RP_IF_SI_NWDF_XIX_HCP3_IONode  # _XIX_diagnosis_infrastructure_SGW04_XIX_diagnosis_infrastructure_XIX_HCP5_P2_OBD_Safety_XIX_diagnosis_infrastructure_Info_El_XIX_diagnosis_infrastructure_XIX_HCP3_IONode_XIX_SI_NWDF
    delegate diagnosis_infrastructure_Info_El_XIX_diagnosis_infrastructure_XIX_HCP3_IONode.RP_IF_WLC1_SNI_10_XIX_diagnosis_infrastructure_Info_El_XIX_diagnosis_infrastructure_XIX_HCP3_IONode <-> outer port RP_IF_WLC1_SNI_10_XIX_HCP3_IONode  # _XIX_diagnosis_infrastructure_WLC1_XIX_diagnosis_infrastructure_XIX_WLC_01_XIX_diagnosis_infrastructure_Info_El_XIX_diagnosis_infrastructure_XIX_HCP3_IONode_XIX_WLC1_SNI_10
    delegate diagnosis_infrastructure_Info_El_XIX_diagnosis_infrastructure_XIX_HCP3_IONode.RP_IF_WLC1_KD_Fehler_XIX_diagnosis_infrastructure_Info_El_XIX_diagnosis_infrastructure_XIX_HCP3_IONode <-> outer port RP_IF_WLC1_KD_Fehler_XIX_HCP3_IONode  # _XIX_diagnosis_infrastructure_WLC1_XIX_diagnosis_infrastructure_XIX_WLC_01_XIX_diagnosis_infrastructure_Info_El_XIX_diagnosis_infrastructure_XIX_HCP3_IONode_XIX_WLC1_KD_Fehler
    delegate diagnosis_infrastructure_Info_El_XIX_diagnosis_infrastructure_XIX_HCP3_IONode.RP_IF_KN_WLC1_DiagPfad_V12_XIX_diagnosis_infrastructure_Info_El_XIX_diagnosis_infrastructure_XIX_HCP3_IONode <-> outer port RP_IF_KN_WLC1_DiagPfad_V12_XIX_HCP3_IONode  # _XIX_diagnosis_infrastructure_WLC1_XIX_diagnosis_infrastructure_XIX_WLC_01_XIX_diagnosis_infrastructure_Info_El_XIX_diagnosis_infrastructure_XIX_HCP3_IONode_XIX_KN_WLC1_DiagPfad_V12
    delegate diagnosis_infrastructure_Info_El_XIX_diagnosis_infrastructure_XIX_HCP3_IONode.RP_IF_WLC2_KD_Fehler_XIX_diagnosis_infrastructure_Info_El_XIX_diagnosis_infrastructure_XIX_HCP3_IONode <-> outer port RP_IF_WLC2_KD_Fehler_XIX_HCP3_IONode  # _XIX_diagnosis_infrastructure_WLC2_XIX_diagnosis_infrastructure_XIX_WLC_02_XIX_diagnosis_infrastructure_Info_El_XIX_diagnosis_infrastructure_XIX_HCP3_IONode_XIX_WLC2_KD_Fehler
    delegate diagnosis_infrastructure_Info_El_XIX_diagnosis_infrastructure_XIX_HCP3_IONode.RP_IF_KN_WLC2_DiagPfad_V12_XIX_diagnosis_infrastructure_Info_El_XIX_diagnosis_infrastructure_XIX_HCP3_IONode <-> outer port RP_IF_KN_WLC2_DiagPfad_V12_XIX_HCP3_IONode  # _XIX_diagnosis_infrastructure_WLC2_XIX_diagnosis_infrastructure_XIX_WLC_02_XIX_diagnosis_infrastructure_Info_El_XIX_diagnosis_infrastructure_XIX_HCP3_IONode_XIX_KN_WLC2_DiagPfad_V12
    delegate diagnosis_infrastructure_Info_El_XIX_diagnosis_infrastructure_XIX_HCP3_IONode.RP_IF_WLC2_SNI_10_XIX_diagnosis_infrastructure_Info_El_XIX_diagnosis_infrastructure_XIX_HCP3_IONode <-> outer port RP_IF_WLC2_SNI_10_XIX_HCP3_IONode  # _XIX_diagnosis_infrastructure_WLC2_XIX_diagnosis_infrastructure_XIX_WLC_02_XIX_diagnosis_infrastructure_Info_El_XIX_diagnosis_infrastructure_XIX_HCP3_IONode_XIX_WLC2_SNI_10
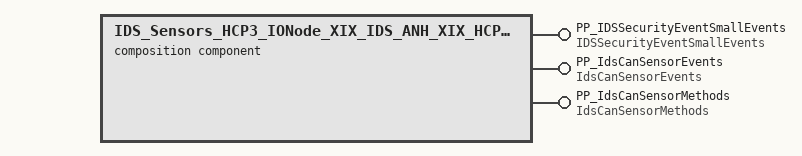
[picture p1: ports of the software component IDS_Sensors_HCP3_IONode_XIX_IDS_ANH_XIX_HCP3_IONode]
  composition sw component type IDS_Sensors_HCP3_IONode_XIX_IDS_ANH_XIX_HCP3_IONode
    provide port PP_IDSSecurityEventSmallEvents: provided-interface=IDSSecurityEventSmallEvents
    provide port PP_IdsCanSensorEvents: provided-interface=IdsCanSensorEvents
    provide port PP_IdsCanSensorMethods: provided-interface=IdsCanSensorMethods
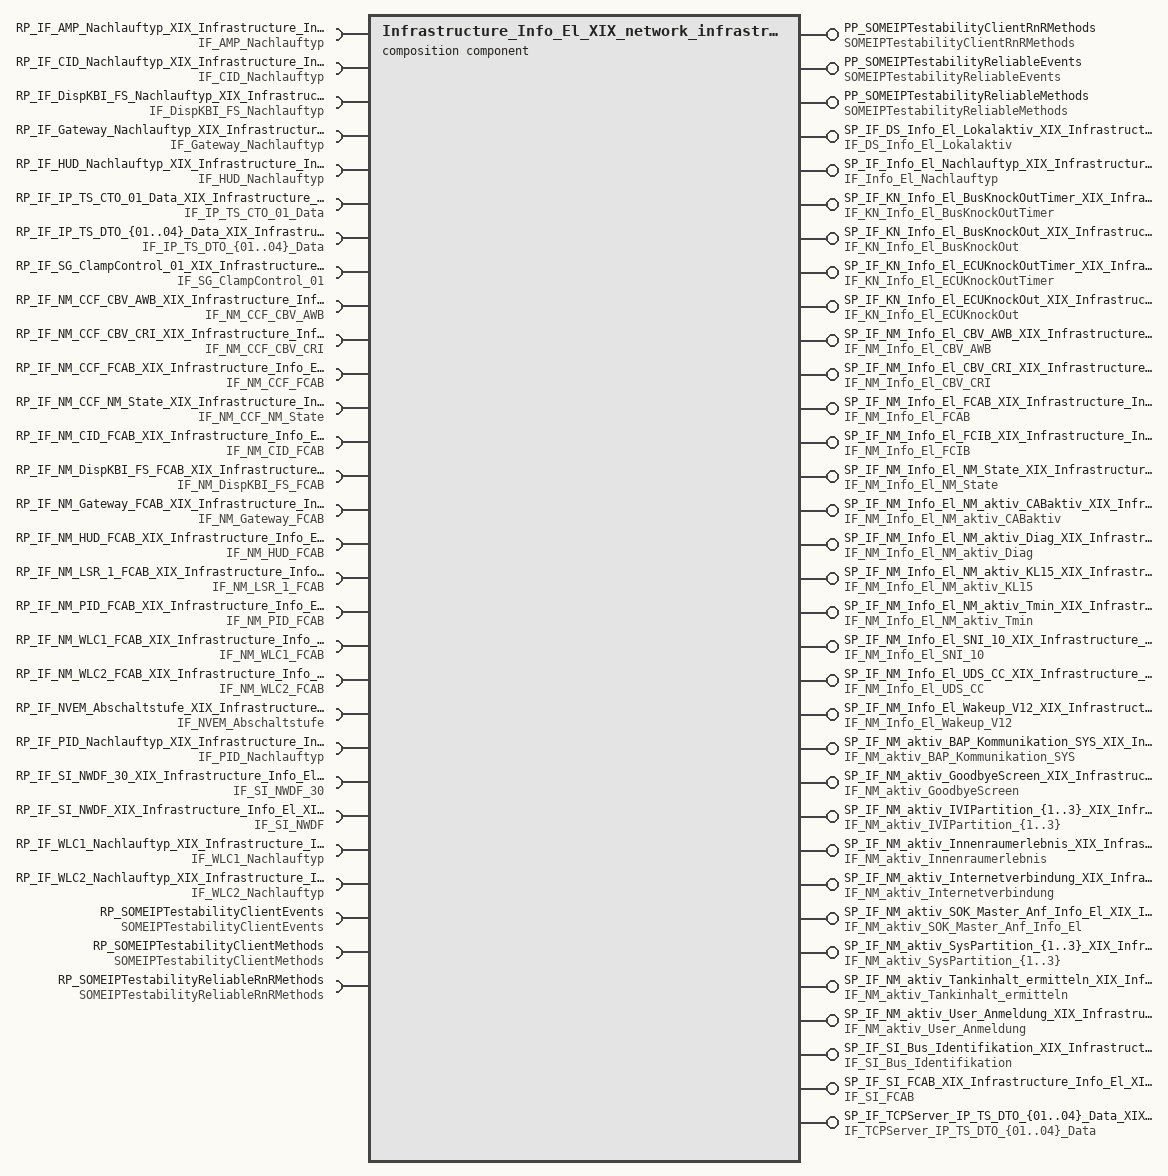
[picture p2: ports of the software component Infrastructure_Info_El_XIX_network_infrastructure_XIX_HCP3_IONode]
  composition sw component type Infrastructure_Info_El_XIX_network_infrastructure_XIX_HCP3_IONode
    40 x provide port:
      PP_SOMEIPTestabilityClientRnRMethods: provided-interface=SOMEIPTestabilityClientRnRMethods
      PP_SOMEIPTestabilityReliableEvents: provided-interface=SOMEIPTestabilityReliableEvents
      PP_SOMEIPTestabilityReliableMethods: provided-interface=SOMEIPTestabilityReliableMethods
      SP_IF_DS_Info_El_Lokalaktiv_XIX_Infrastructure_Info_El_XIX_network_infrastructure_XIX_HCP3_IONode: provided-interface=IF_DS_Info_El_Lokalaktiv
      SP_IF_Info_El_Nachlauftyp_XIX_Infrastructure_Info_El_XIX_network_infrastructure_XIX_HCP3_IONode: provided-interface=IF_Info_El_Nachlauftyp
      SP_IF_KN_Info_El_BusKnockOutTimer_XIX_Infrastructure_Info_El_XIX_network_infrastructure_XIX_HCP3_IONode: provided-interface=IF_KN_Info_El_BusKnockOutTimer
      SP_IF_KN_Info_El_BusKnockOut_XIX_Infrastructure_Info_El_XIX_network_infrastructure_XIX_HCP3_IONode: provided-interface=IF_KN_Info_El_BusKnockOut
      SP_IF_KN_Info_El_ECUKnockOutTimer_XIX_Infrastructure_Info_El_XIX_network_infrastructure_XIX_HCP3_IONode: provided-interface=IF_KN_Info_El_ECUKnockOutTimer
      SP_IF_KN_Info_El_ECUKnockOut_XIX_Infrastructure_Info_El_XIX_network_infrastructure_XIX_HCP3_IONode: provided-interface=IF_KN_Info_El_ECUKnockOut
      SP_IF_NM_Info_El_CBV_AWB_XIX_Infrastructure_Info_El_XIX_network_infrastructure_XIX_HCP3_IONode: provided-interface=IF_NM_Info_El_CBV_AWB
      SP_IF_NM_Info_El_CBV_CRI_XIX_Infrastructure_Info_El_XIX_network_infrastructure_XIX_HCP3_IONode: provided-interface=IF_NM_Info_El_CBV_CRI
      SP_IF_NM_Info_El_FCAB_XIX_Infrastructure_Info_El_XIX_network_infrastructure_XIX_HCP3_IONode: provided-interface=IF_NM_Info_El_FCAB
      SP_IF_NM_Info_El_FCIB_XIX_Infrastructure_Info_El_XIX_network_infrastructure_XIX_HCP3_IONode: provided-interface=IF_NM_Info_El_FCIB
      SP_IF_NM_Info_El_NM_State_XIX_Infrastructure_Info_El_XIX_network_infrastructure_XIX_HCP3_IONode: provided-interface=IF_NM_Info_El_NM_State
      SP_IF_NM_Info_El_NM_aktiv_CABaktiv_XIX_Infrastructure_Info_El_XIX_network_infrastructure_XIX_HCP3_IONode: provided-interface=IF_NM_Info_El_NM_aktiv_CABaktiv
      SP_IF_NM_Info_El_NM_aktiv_Diag_XIX_Infrastructure_Info_El_XIX_network_infrastructure_XIX_HCP3_IONode: provided-interface=IF_NM_Info_El_NM_aktiv_Diag
      SP_IF_NM_Info_El_NM_aktiv_KL15_XIX_Infrastructure_Info_El_XIX_network_infrastructure_XIX_HCP3_IONode: provided-interface=IF_NM_Info_El_NM_aktiv_KL15
      SP_IF_NM_Info_El_NM_aktiv_Tmin_XIX_Infrastructure_Info_El_XIX_network_infrastructure_XIX_HCP3_IONode: provided-interface=IF_NM_Info_El_NM_aktiv_Tmin
      SP_IF_NM_Info_El_SNI_10_XIX_Infrastructure_Info_El_XIX_network_infrastructure_XIX_HCP3_IONode: provided-interface=IF_NM_Info_El_SNI_10
      SP_IF_NM_Info_El_UDS_CC_XIX_Infrastructure_Info_El_XIX_network_infrastructure_XIX_HCP3_IONode: provided-interface=IF_NM_Info_El_UDS_CC
      SP_IF_NM_Info_El_Wakeup_V12_XIX_Infrastructure_Info_El_XIX_network_infrastructure_XIX_HCP3_IONode: provided-interface=IF_NM_Info_El_Wakeup_V12
      SP_IF_NM_aktiv_BAP_Kommunikation_SYS_XIX_Infrastructure_Info_El_XIX_network_infrastructure_XIX_HCP3_IONode: provided-interface=IF_NM_aktiv_BAP_Kommunikation_SYS
      SP_IF_NM_aktiv_GoodbyeScreen_XIX_Infrastructure_Info_El_XIX_network_infrastructure_XIX_HCP3_IONode: provided-interface=IF_NM_aktiv_GoodbyeScreen
      SP_IF_NM_aktiv_IVIPartition_{1..3}_XIX_Infrastructure_Info_El_XIX_network_infrastructure_XIX_HCP3_IONode: provided-interface=IF_NM_aktiv_IVIPartition_{1..3}
      SP_IF_NM_aktiv_Innenraumerlebnis_XIX_Infrastructure_Info_El_XIX_network_infrastructure_XIX_HCP3_IONode: provided-interface=IF_NM_aktiv_Innenraumerlebnis
      SP_IF_NM_aktiv_Internetverbindung_XIX_Infrastructure_Info_El_XIX_network_infrastructure_XIX_HCP3_IONode: provided-interface=IF_NM_aktiv_Internetverbindung
      SP_IF_NM_aktiv_SOK_Master_Anf_Info_El_XIX_Infrastructure_Info_El_XIX_network_infrastructure_XIX_HCP3_IONode: provided-interface=IF_NM_aktiv_SOK_Master_Anf_Info_El
      SP_IF_NM_aktiv_SysPartition_{1..3}_XIX_Infrastructure_Info_El_XIX_network_infrastructure_XIX_HCP3_IONode: provided-interface=IF_NM_aktiv_SysPartition_{1..3}
      SP_IF_NM_aktiv_Tankinhalt_ermitteln_XIX_Infrastructure_Info_El_XIX_network_infrastructure_XIX_HCP3_IONode: provided-interface=IF_NM_aktiv_Tankinhalt_ermitteln
      SP_IF_NM_aktiv_User_Anmeldung_XIX_Infrastructure_Info_El_XIX_network_infrastructure_XIX_HCP3_IONode: provided-interface=IF_NM_aktiv_User_Anmeldung
      SP_IF_SI_Bus_Identifikation_XIX_Infrastructure_Info_El_XIX_network_infrastructure_XIX_HCP3_IONode: provided-interface=IF_SI_Bus_Identifikation
      SP_IF_SI_FCAB_XIX_Infrastructure_Info_El_XIX_network_infrastructure_XIX_HCP3_IONode: provided-interface=IF_SI_FCAB
      SP_IF_TCPServer_IP_TS_DTO_{01..04}_Data_XIX_Infrastructure_Info_El_XIX_network_infrastructure_XIX_HCP3_IONode: provided-interface=IF_TCPServer_IP_TS_DTO_{01..04}_Data
    32 x require port:
      RP_IF_AMP_Nachlauftyp_XIX_Infrastructure_Info_El_XIX_network_infrastructure_XIX_HCP3_IONode: required-interface=IF_AMP_Nachlauftyp
      RP_IF_CID_Nachlauftyp_XIX_Infrastructure_Info_El_XIX_network_infrastructure_XIX_HCP3_IONode: required-interface=IF_CID_Nachlauftyp
      RP_IF_DispKBI_FS_Nachlauftyp_XIX_Infrastructure_Info_El_XIX_network_infrastructure_XIX_HCP3_IONode: required-interface=IF_DispKBI_FS_Nachlauftyp
      RP_IF_Gateway_Nachlauftyp_XIX_Infrastructure_Info_El_XIX_network_infrastructure_XIX_HCP3_IONode: required-interface=IF_Gateway_Nachlauftyp
      RP_IF_HUD_Nachlauftyp_XIX_Infrastructure_Info_El_XIX_network_infrastructure_XIX_HCP3_IONode: required-interface=IF_HUD_Nachlauftyp
      RP_IF_IP_TS_CTO_01_Data_XIX_Infrastructure_Info_El_XIX_network_infrastructure_XIX_HCP3_IONode: required-interface=IF_IP_TS_CTO_01_Data
      RP_IF_IP_TS_DTO_{01..04}_Data_XIX_Infrastructure_Info_El_XIX_network_infrastructure_XIX_HCP3_IONode: required-interface=IF_IP_TS_DTO_{01..04}_Data
      RP_IF_SG_ClampControl_01_XIX_Infrastructure_Info_El_XIX_network_infrastructure_XIX_HCP3_IONode: required-interface=IF_SG_ClampControl_01
      RP_IF_NM_CCF_CBV_AWB_XIX_Infrastructure_Info_El_XIX_network_infrastructure_XIX_HCP3_IONode: required-interface=IF_NM_CCF_CBV_AWB
      RP_IF_NM_CCF_CBV_CRI_XIX_Infrastructure_Info_El_XIX_network_infrastructure_XIX_HCP3_IONode: required-interface=IF_NM_CCF_CBV_CRI
      RP_IF_NM_CCF_FCAB_XIX_Infrastructure_Info_El_XIX_network_infrastructure_XIX_HCP3_IONode: required-interface=IF_NM_CCF_FCAB
      RP_IF_NM_CCF_NM_State_XIX_Infrastructure_Info_El_XIX_network_infrastructure_XIX_HCP3_IONode: required-interface=IF_NM_CCF_NM_State
      RP_IF_NM_CID_FCAB_XIX_Infrastructure_Info_El_XIX_network_infrastructure_XIX_HCP3_IONode: required-interface=IF_NM_CID_FCAB
      RP_IF_NM_DispKBI_FS_FCAB_XIX_Infrastructure_Info_El_XIX_network_infrastructure_XIX_HCP3_IONode: required-interface=IF_NM_DispKBI_FS_FCAB
      RP_IF_NM_Gateway_FCAB_XIX_Infrastructure_Info_El_XIX_network_infrastructure_XIX_HCP3_IONode: required-interface=IF_NM_Gateway_FCAB
      RP_IF_NM_HUD_FCAB_XIX_Infrastructure_Info_El_XIX_network_infrastructure_XIX_HCP3_IONode: required-interface=IF_NM_HUD_FCAB
      RP_IF_NM_LSR_1_FCAB_XIX_Infrastructure_Info_El_XIX_network_infrastructure_XIX_HCP3_IONode: required-interface=IF_NM_LSR_1_FCAB
      RP_IF_NM_PID_FCAB_XIX_Infrastructure_Info_El_XIX_network_infrastructure_XIX_HCP3_IONode: required-interface=IF_NM_PID_FCAB
      RP_IF_NM_WLC1_FCAB_XIX_Infrastructure_Info_El_XIX_network_infrastructure_XIX_HCP3_IONode: required-interface=IF_NM_WLC1_FCAB
      RP_IF_NM_WLC2_FCAB_XIX_Infrastructure_Info_El_XIX_network_infrastructure_XIX_HCP3_IONode: required-interface=IF_NM_WLC2_FCAB
      RP_IF_NVEM_Abschaltstufe_XIX_Infrastructure_Info_El_XIX_network_infrastructure_XIX_HCP3_IONode: required-interface=IF_NVEM_Abschaltstufe
      RP_IF_PID_Nachlauftyp_XIX_Infrastructure_Info_El_XIX_network_infrastructure_XIX_HCP3_IONode: required-interface=IF_PID_Nachlauftyp
      RP_IF_SI_NWDF_30_XIX_Infrastructure_Info_El_XIX_network_infrastructure_XIX_HCP3_IONode: required-interface=IF_SI_NWDF_30
      RP_IF_SI_NWDF_XIX_Infrastructure_Info_El_XIX_network_infrastructure_XIX_HCP3_IONode: required-interface=IF_SI_NWDF
      RP_IF_WLC1_Nachlauftyp_XIX_Infrastructure_Info_El_XIX_network_infrastructure_XIX_HCP3_IONode: required-interface=IF_WLC1_Nachlauftyp
      RP_IF_WLC2_Nachlauftyp_XIX_Infrastructure_Info_El_XIX_network_infrastructure_XIX_HCP3_IONode: required-interface=IF_WLC2_Nachlauftyp
      RP_SOMEIPTestabilityClientEvents: required-interface=SOMEIPTestabilityClientEvents
      RP_SOMEIPTestabilityClientMethods: required-interface=SOMEIPTestabilityClientMethods
      RP_SOMEIPTestabilityReliableRnRMethods: required-interface=SOMEIPTestabilityReliableRnRMethods
  composition sw component type ORU_Infrastructure_Info_El_XIX_ORU6_XIX_HCP3_IONode
    require port RP_IF_ORU_Status_XIX_ORU_Infrastructure_Info_El_XIX_ORU6_XIX_HCP3_IONode: required-interface=IF_ORU_Status
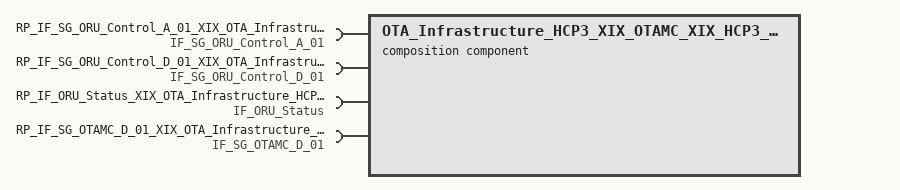
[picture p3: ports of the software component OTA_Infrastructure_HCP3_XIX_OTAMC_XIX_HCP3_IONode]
  composition sw component type OTA_Infrastructure_HCP3_XIX_OTAMC_XIX_HCP3_IONode
    4 x require port:
      RP_IF_SG_ORU_Control_A_01_XIX_OTA_Infrastructure_HCP3_XIX_OTAMC_XIX_HCP3_IONode: required-interface=IF_SG_ORU_Control_A_01
      RP_IF_SG_ORU_Control_D_01_XIX_OTA_Infrastructure_HCP3_XIX_OTAMC_XIX_HCP3_IONode: required-interface=IF_SG_ORU_Control_D_01
      RP_IF_ORU_Status_XIX_OTA_Infrastructure_HCP3_XIX_OTAMC_XIX_HCP3_IONode: required-interface=IF_ORU_Status
      RP_IF_SG_OTAMC_D_01_XIX_OTA_Infrastructure_HCP3_XIX_OTAMC_XIX_HCP3_IONode: required-interface=IF_SG_OTAMC_D_01
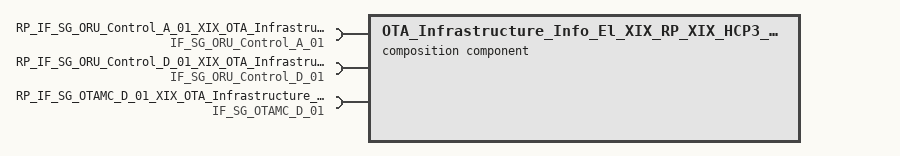
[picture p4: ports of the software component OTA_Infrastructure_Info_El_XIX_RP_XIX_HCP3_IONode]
  composition sw component type OTA_Infrastructure_Info_El_XIX_RP_XIX_HCP3_IONode
    require port RP_IF_SG_ORU_Control_A_01_XIX_OTA_Infrastructure_Info_El_XIX_RP_XIX_HCP3_IONode: required-interface=IF_SG_ORU_Control_A_01
    require port RP_IF_SG_ORU_Control_D_01_XIX_OTA_Infrastructure_Info_El_XIX_RP_XIX_HCP3_IONode: required-interface=IF_SG_ORU_Control_D_01
    require port RP_IF_SG_OTAMC_D_01_XIX_OTA_Infrastructure_Info_El_XIX_RP_XIX_HCP3_IONode: required-interface=IF_SG_OTAMC_D_01
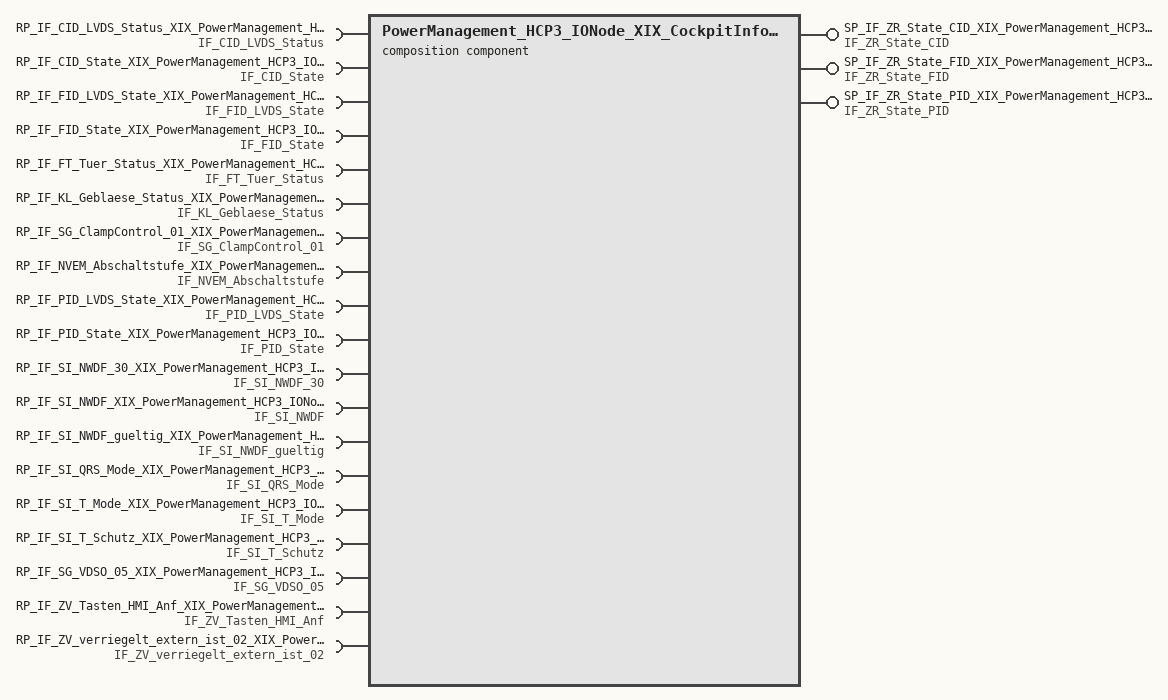
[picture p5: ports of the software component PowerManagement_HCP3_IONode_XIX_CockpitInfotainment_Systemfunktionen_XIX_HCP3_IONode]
  composition sw component type PowerManagement_HCP3_IONode_XIX_CockpitInfotainment_Systemfunktionen_XIX_HCP3_IONode
    provide port SP_IF_ZR_State_CID_XIX_PowerManagement_HCP3_IONode_XIX_CockpitInfotainment_Systemfunktionen_XIX_HCP3_IONode: provided-interface=IF_ZR_State_CID
    provide port SP_IF_ZR_State_FID_XIX_PowerManagement_HCP3_IONode_XIX_CockpitInfotainment_Systemfunktionen_XIX_HCP3_IONode: provided-interface=IF_ZR_State_FID
    provide port SP_IF_ZR_State_PID_XIX_PowerManagement_HCP3_IONode_XIX_CockpitInfotainment_Systemfunktionen_XIX_HCP3_IONode: provided-interface=IF_ZR_State_PID
    19 x require port:
      RP_IF_CID_LVDS_Status_XIX_PowerManagement_HCP3_IONode_XIX_CockpitInfotainment_Systemfunktionen_XIX_HCP3_IONode: required-interface=IF_CID_LVDS_Status
      RP_IF_CID_State_XIX_PowerManagement_HCP3_IONode_XIX_CockpitInfotainment_Systemfunktionen_XIX_HCP3_IONode: required-interface=IF_CID_State
      RP_IF_FID_LVDS_State_XIX_PowerManagement_HCP3_IONode_XIX_CockpitInfotainment_Systemfunktionen_XIX_HCP3_IONode: required-interface=IF_FID_LVDS_State
      RP_IF_FID_State_XIX_PowerManagement_HCP3_IONode_XIX_CockpitInfotainment_Systemfunktionen_XIX_HCP3_IONode: required-interface=IF_FID_State
      RP_IF_FT_Tuer_Status_XIX_PowerManagement_HCP3_IONode_XIX_CockpitInfotainment_Systemfunktionen_XIX_HCP3_IONode: required-interface=IF_FT_Tuer_Status
      RP_IF_KL_Geblaese_Status_XIX_PowerManagement_HCP3_IONode_XIX_CockpitInfotainment_Systemfunktionen_XIX_HCP3_IONode: required-interface=IF_KL_Geblaese_Status
      RP_IF_SG_ClampControl_01_XIX_PowerManagement_HCP3_IONode_XIX_CockpitInfotainment_Systemfunktionen_XIX_HCP3_IONode: required-interface=IF_SG_ClampControl_01
      RP_IF_NVEM_Abschaltstufe_XIX_PowerManagement_HCP3_IONode_XIX_CockpitInfotainment_Systemfunktionen_XIX_HCP3_IONode: required-interface=IF_NVEM_Abschaltstufe
      RP_IF_PID_LVDS_State_XIX_PowerManagement_HCP3_IONode_XIX_CockpitInfotainment_Systemfunktionen_XIX_HCP3_IONode: required-interface=IF_PID_LVDS_State
      RP_IF_PID_State_XIX_PowerManagement_HCP3_IONode_XIX_CockpitInfotainment_Systemfunktionen_XIX_HCP3_IONode: required-interface=IF_PID_State
      RP_IF_SI_NWDF_30_XIX_PowerManagement_HCP3_IONode_XIX_CockpitInfotainment_Systemfunktionen_XIX_HCP3_IONode: required-interface=IF_SI_NWDF_30
      RP_IF_SI_NWDF_XIX_PowerManagement_HCP3_IONode_XIX_CockpitInfotainment_Systemfunktionen_XIX_HCP3_IONode: required-interface=IF_SI_NWDF
      RP_IF_SI_NWDF_gueltig_XIX_PowerManagement_HCP3_IONode_XIX_CockpitInfotainment_Systemfunktionen_XIX_HCP3_IONode: required-interface=IF_SI_NWDF_gueltig
      RP_IF_SI_QRS_Mode_XIX_PowerManagement_HCP3_IONode_XIX_CockpitInfotainment_Systemfunktionen_XIX_HCP3_IONode: required-interface=IF_SI_QRS_Mode
      RP_IF_SI_T_Mode_XIX_PowerManagement_HCP3_IONode_XIX_CockpitInfotainment_Systemfunktionen_XIX_HCP3_IONode: required-interface=IF_SI_T_Mode
      RP_IF_SI_T_Schutz_XIX_PowerManagement_HCP3_IONode_XIX_CockpitInfotainment_Systemfunktionen_XIX_HCP3_IONode: required-interface=IF_SI_T_Schutz
      RP_IF_SG_VDSO_05_XIX_PowerManagement_HCP3_IONode_XIX_CockpitInfotainment_Systemfunktionen_XIX_HCP3_IONode: required-interface=IF_SG_VDSO_05
      RP_IF_ZV_Tasten_HMI_Anf_XIX_PowerManagement_HCP3_IONode_XIX_CockpitInfotainment_Systemfunktionen_XIX_HCP3_IONode: required-interface=IF_ZV_Tasten_HMI_Anf
      RP_IF_ZV_verriegelt_extern_ist_02_XIX_PowerManagement_HCP3_IONode_XIX_CockpitInfotainment_Systemfunktionen_XIX_HCP3_IONode: required-interface=IF_ZV_verriegelt_extern_ist_02
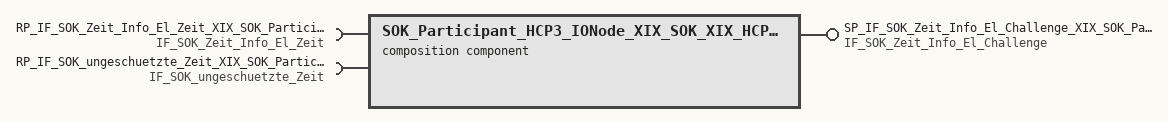
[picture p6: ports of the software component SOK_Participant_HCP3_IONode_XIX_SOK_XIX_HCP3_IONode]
  composition sw component type SOK_Participant_HCP3_IONode_XIX_SOK_XIX_HCP3_IONode
    provide port SP_IF_SOK_Zeit_Info_El_Challenge_XIX_SOK_Participant_HCP3_IONode_XIX_SOK_XIX_HCP3_IONode: provided-interface=IF_SOK_Zeit_Info_El_Challenge
    require port RP_IF_SOK_Zeit_Info_El_Zeit_XIX_SOK_Participant_HCP3_IONode_XIX_SOK_XIX_HCP3_IONode: required-interface=IF_SOK_Zeit_Info_El_Zeit
    require port RP_IF_SOK_ungeschuetzte_Zeit_XIX_SOK_Participant_HCP3_IONode_XIX_SOK_XIX_HCP3_IONode: required-interface=IF_SOK_ungeschuetzte_Zeit
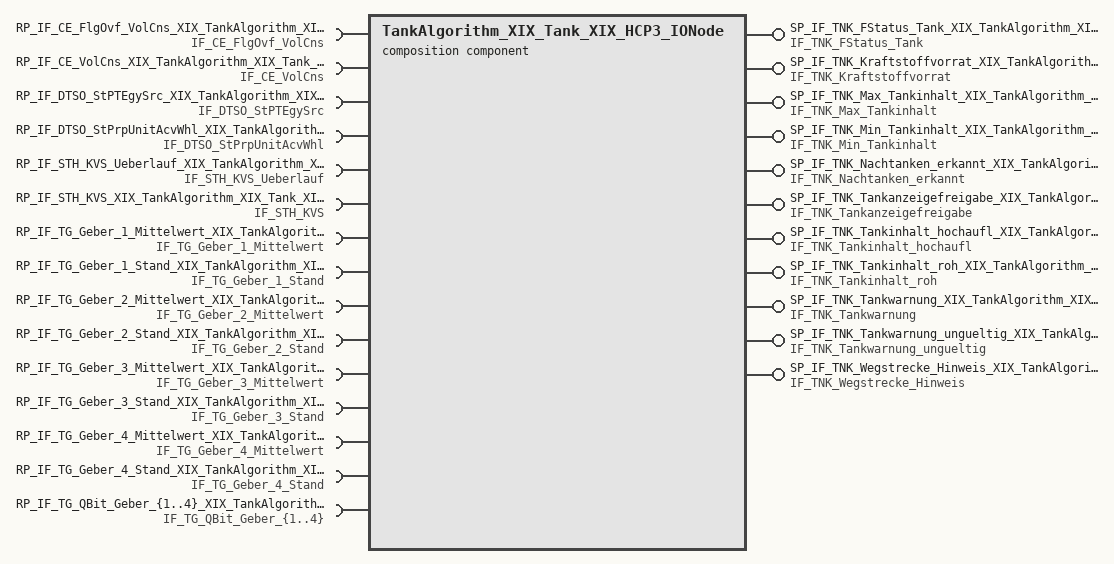
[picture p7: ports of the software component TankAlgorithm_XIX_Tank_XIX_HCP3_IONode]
  composition sw component type TankAlgorithm_XIX_Tank_XIX_HCP3_IONode
    11 x provide port:
      SP_IF_TNK_FStatus_Tank_XIX_TankAlgorithm_XIX_Tank_XIX_HCP3_IONode: provided-interface=IF_TNK_FStatus_Tank
      SP_IF_TNK_Kraftstoffvorrat_XIX_TankAlgorithm_XIX_Tank_XIX_HCP3_IONode: provided-interface=IF_TNK_Kraftstoffvorrat
      SP_IF_TNK_Max_Tankinhalt_XIX_TankAlgorithm_XIX_Tank_XIX_HCP3_IONode: provided-interface=IF_TNK_Max_Tankinhalt
      SP_IF_TNK_Min_Tankinhalt_XIX_TankAlgorithm_XIX_Tank_XIX_HCP3_IONode: provided-interface=IF_TNK_Min_Tankinhalt
      SP_IF_TNK_Nachtanken_erkannt_XIX_TankAlgorithm_XIX_Tank_XIX_HCP3_IONode: provided-interface=IF_TNK_Nachtanken_erkannt
      SP_IF_TNK_Tankanzeigefreigabe_XIX_TankAlgorithm_XIX_Tank_XIX_HCP3_IONode: provided-interface=IF_TNK_Tankanzeigefreigabe
      SP_IF_TNK_Tankinhalt_hochaufl_XIX_TankAlgorithm_XIX_Tank_XIX_HCP3_IONode: provided-interface=IF_TNK_Tankinhalt_hochaufl
      SP_IF_TNK_Tankinhalt_roh_XIX_TankAlgorithm_XIX_Tank_XIX_HCP3_IONode: provided-interface=IF_TNK_Tankinhalt_roh
      SP_IF_TNK_Tankwarnung_XIX_TankAlgorithm_XIX_Tank_XIX_HCP3_IONode: provided-interface=IF_TNK_Tankwarnung
      SP_IF_TNK_Tankwarnung_ungueltig_XIX_TankAlgorithm_XIX_Tank_XIX_HCP3_IONode: provided-interface=IF_TNK_Tankwarnung_ungueltig
      SP_IF_TNK_Wegstrecke_Hinweis_XIX_TankAlgorithm_XIX_Tank_XIX_HCP3_IONode: provided-interface=IF_TNK_Wegstrecke_Hinweis
    18 x require port:
      RP_IF_CE_FlgOvf_VolCns_XIX_TankAlgorithm_XIX_Tank_XIX_HCP3_IONode: required-interface=IF_CE_FlgOvf_VolCns
      RP_IF_CE_VolCns_XIX_TankAlgorithm_XIX_Tank_XIX_HCP3_IONode: required-interface=IF_CE_VolCns
      RP_IF_DTSO_StPTEgySrc_XIX_TankAlgorithm_XIX_Tank_XIX_HCP3_IONode: required-interface=IF_DTSO_StPTEgySrc
      RP_IF_DTSO_StPrpUnitAcvWhl_XIX_TankAlgorithm_XIX_Tank_XIX_HCP3_IONode: required-interface=IF_DTSO_StPrpUnitAcvWhl
      RP_IF_STH_KVS_Ueberlauf_XIX_TankAlgorithm_XIX_Tank_XIX_HCP3_IONode: required-interface=IF_STH_KVS_Ueberlauf
      RP_IF_STH_KVS_XIX_TankAlgorithm_XIX_Tank_XIX_HCP3_IONode: required-interface=IF_STH_KVS
      RP_IF_TG_Geber_1_Mittelwert_XIX_TankAlgorithm_XIX_Tank_XIX_HCP3_IONode: required-interface=IF_TG_Geber_1_Mittelwert
      RP_IF_TG_Geber_1_Stand_XIX_TankAlgorithm_XIX_Tank_XIX_HCP3_IONode: required-interface=IF_TG_Geber_1_Stand
      RP_IF_TG_Geber_2_Mittelwert_XIX_TankAlgorithm_XIX_Tank_XIX_HCP3_IONode: required-interface=IF_TG_Geber_2_Mittelwert
      RP_IF_TG_Geber_2_Stand_XIX_TankAlgorithm_XIX_Tank_XIX_HCP3_IONode: required-interface=IF_TG_Geber_2_Stand
      RP_IF_TG_Geber_3_Mittelwert_XIX_TankAlgorithm_XIX_Tank_XIX_HCP3_IONode: required-interface=IF_TG_Geber_3_Mittelwert
      RP_IF_TG_Geber_3_Stand_XIX_TankAlgorithm_XIX_Tank_XIX_HCP3_IONode: required-interface=IF_TG_Geber_3_Stand
      RP_IF_TG_Geber_4_Mittelwert_XIX_TankAlgorithm_XIX_Tank_XIX_HCP3_IONode: required-interface=IF_TG_Geber_4_Mittelwert
      RP_IF_TG_Geber_4_Stand_XIX_TankAlgorithm_XIX_Tank_XIX_HCP3_IONode: required-interface=IF_TG_Geber_4_Stand
      RP_IF_TG_QBit_Geber_{1..4}_XIX_TankAlgorithm_XIX_Tank_XIX_HCP3_IONode: required-interface=IF_TG_QBit_Geber_{1..4}
